VERSION ""

NS_ :

BS_:

BU_: IGW ADU

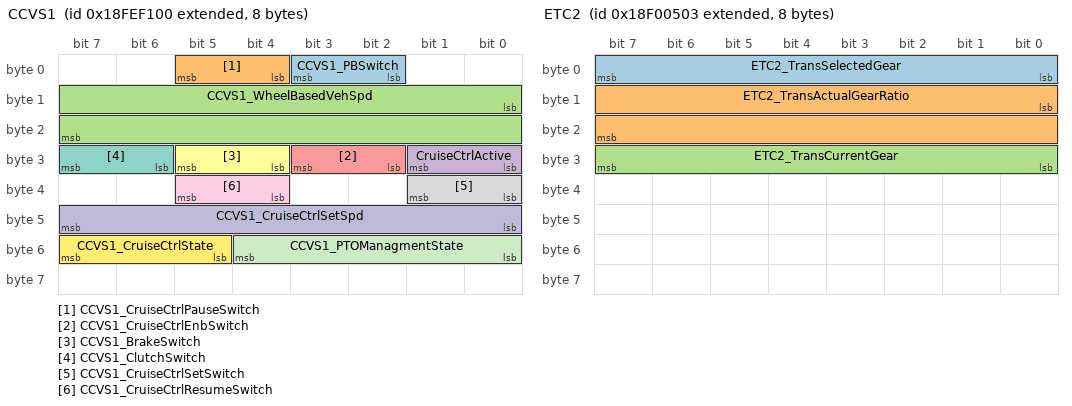
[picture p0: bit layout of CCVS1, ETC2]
BO_ 2566844672 CCVS1: 8 IGW
 SG_ CCVS1_PBSwitch : 2|2@1+ (1,0) [0|3] ""  ADU
 SG_ CCVS1_CruiseCtrlPauseSwitch : 4|2@1+ (1,0) [0|3] ""  ADU
 SG_ CCVS1_WheelBasedVehSpd : 8|16@1+ (0.00390625,0) [0|250.996] "km/h"  ADU
 SG_ CruiseCtrlActive : 24|2@1+ (1,0) [0|3] ""  ADU
 SG_ CCVS1_CruiseCtrlEnbSwitch : 26|2@1+ (1,0) [0|3] ""  ADU
 SG_ CCVS1_BrakeSwitch : 28|2@1+ (1,0) [0|3] ""  ADU
 SG_ CCVS1_ClutchSwitch : 30|2@1+ (1,0) [0|3] ""  ADU
 SG_ CCVS1_CruiseCtrlSetSwitch : 32|2@1+ (1,0) [0|3] ""  ADU
 SG_ CCVS1_CruiseCtrlResumeSwitch : 36|2@1+ (1,0) [0|3] ""  ADU
 SG_ CCVS1_CruiseCtrlSetSpd : 40|8@1+ (1,0) [0|250] "km/h"  ADU
 SG_ CCVS1_PTOManagmentState : 48|5@1+ (1,0) [0|31] ""  ADU
 SG_ CCVS1_CruiseCtrlState : 53|3@1+ (1,0) [0|7] ""  ADU

BO_ 2565866755 ETC2: 8 IGW
 SG_ ETC2_TransSelectedGear : 0|8@1+ (1,-125) [-125|125] ""  ADU
 SG_ ETC2_TransActualGearRatio : 8|16@1+ (0.001,0) [0|64.255] ""  ADU
 SG_ ETC2_TransCurrentGear : 24|8@1+ (1,-125) [-125|125] ""  ADU

BO_ 2566834768 DM1_EPB: 42 IGW
 SG_ DM1_EPB_ProtectLamp : 0|2@1+ (1,0) [0|3] ""  ADU
 SG_ DM1_EPB_AmberWarningLamp : 2|2@1+ (1,0) [0|3] ""  ADU
 SG_ DM1_EPB_RedStopLamp : 4|2@1+ (1,0) [0|3] ""  ADU
 SG_ DM1_EPB_MalfunctionIndicatorLamp : 6|2@1+ (1,0) [0|3] ""  ADU
 SG_ DM1_EPB_SAELamp_Reserved : 8|8@1+ (1,0) [0|255] ""  ADU
 SG_ DM1_EPB_SPN8_LeastSignificantBit : 16|8@1+ (1,0) [0|255] ""  ADU
 SG_ DM1_EPB_SPN_secondByteOfSPN : 24|8@1+ (1,0) [0|255] ""  ADU
 SG_ DM1_EPB_FMI : 32|5@1+ (1,0) [0|31] ""  ADU
 SG_ DM1_EPB_SPN3MmostSignificantBit : 37|3@1+ (1,0) [0|7] ""  ADU
 SG_ DM1_EPB_OccurrenceCount : 40|7@1+ (1,0) [0|126] ""  ADU
 SG_ DM1_EPB_SPNConversionMethod : 47|1@1+ (1,0) [0|1] ""  ADU

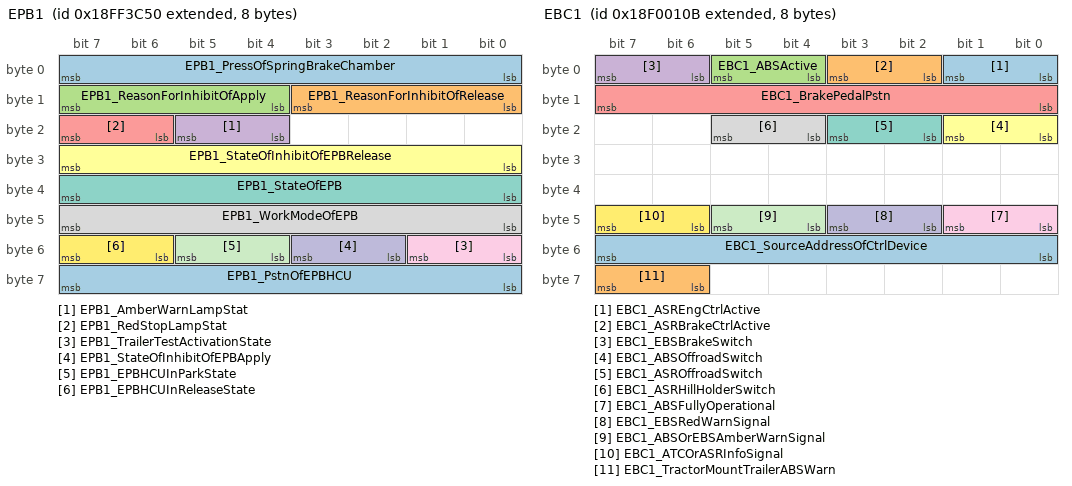
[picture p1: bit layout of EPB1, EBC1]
BO_ 2566863952 EPB1: 8 IGW
 SG_ EPB1_PressOfSpringBrakeChamber : 0|8@1+ (8,0) [0|2000] "kPa"  ADU
 SG_ EPB1_ReasonForInhibitOfRelease : 8|4@1+ (1,0) [0|15] ""  ADU
 SG_ EPB1_ReasonForInhibitOfApply : 12|4@1+ (1,0) [0|15] ""  ADU
 SG_ EPB1_AmberWarnLampStat : 20|2@1+ (1,0) [0|3] ""  ADU
 SG_ EPB1_RedStopLampStat : 22|2@1+ (1,0) [0|3] ""  ADU
 SG_ EPB1_StateOfInhibitOfEPBRelease : 24|8@1+ (1,0) [0|255] ""  ADU
 SG_ EPB1_StateOfEPB : 32|8@1+ (1,0) [0|255] ""  ADU
 SG_ EPB1_WorkModeOfEPB : 40|8@1+ (1,0) [0|255] ""  ADU
 SG_ EPB1_TrailerTestActivationState : 48|2@1+ (1,0) [0|3] ""  ADU
 SG_ EPB1_StateOfInhibitOfEPBApply : 50|2@1+ (1,0) [0|3] ""  ADU
 SG_ EPB1_EPBHCUInParkState : 52|2@1+ (1,0) [0|3] ""  ADU
 SG_ EPB1_EPBHCUInReleaseState : 54|2@1+ (1,0) [0|3] ""  ADU
 SG_ EPB1_PstnOfEPBHCU : 56|8@1+ (1,-125) [-125|125] "%"  ADU

BO_ 2566834699 DM1_ABS: 42 IGW
 SG_ DM1_ABS_ProtectLamp : 0|2@1+ (1,0) [0|3] ""  ADU
 SG_ DM1_ABS_AmberWarningLamp : 2|2@1+ (1,0) [0|3] ""  ADU
 SG_ DM1_ABS_RedStopLamp : 4|2@1+ (1,0) [0|3] ""  ADU
 SG_ DM1_ABS_MalfunctionIndicatorLamp : 6|2@1+ (1,0) [0|3] ""  ADU
 SG_ DM1_ABS_SPN8_LeastSignificantBit : 16|8@1+ (1,0) [0|255] ""  ADU
 SG_ DM1_ABS_SPN_secondByteOfSPN : 24|8@1+ (1,0) [0|255] ""  ADU
 SG_ DM1_ABS_FMI : 32|5@1+ (1,0) [0|31] ""  ADU
 SG_ DM1_ABS_SPN3MmostSignificantBit : 37|3@1+ (1,0) [0|7] ""  ADU
 SG_ DM1_ABS_OccurrenceCount : 40|7@1+ (1,0) [0|126] ""  ADU
 SG_ DM1_ABS_SPNConversionMethod : 47|1@1+ (1,0) [0|1] ""  ADU

BO_ 2565865739 EBC1: 8 IGW
 SG_ EBC1_ASREngCtrlActive : 0|2@1+ (1,0) [0|3] ""  ADU
 SG_ EBC1_ASRBrakeCtrlActive : 2|2@1+ (1,0) [0|3] ""  ADU
 SG_ EBC1_ABSActive : 4|2@1+ (1,0) [0|3] ""  ADU
 SG_ EBC1_EBSBrakeSwitch : 6|2@1+ (1,0) [0|3] ""  ADU
 SG_ EBC1_BrakePedalPstn : 8|8@1+ (0.4,0) [0|100] "%"  ADU
 SG_ EBC1_ABSOffroadSwitch : 16|2@1+ (1,0) [0|3] ""  ADU
 SG_ EBC1_ASROffroadSwitch : 18|2@1+ (1,0) [0|3] ""  ADU
 SG_ EBC1_ASRHillHolderSwitch : 20|2@1+ (1,0) [0|3] ""  ADU
 SG_ EBC1_ABSFullyOperational : 40|2@1+ (1,0) [0|3] ""  ADU
 SG_ EBC1_EBSRedWarnSignal : 42|2@1+ (1,0) [0|3] ""  ADU
 SG_ EBC1_ABSOrEBSAmberWarnSignal : 44|2@1+ (1,0) [0|3] ""  ADU
 SG_ EBC1_ATCOrASRInfoSignal : 46|2@1+ (1,0) [0|3] ""  ADU
 SG_ EBC1_SourceAddressOfCtrlDevice : 48|8@1+ (1,0) [0|253] ""  ADU
 SG_ EBC1_TractorMountTrailerABSWarn : 62|2@1+ (1,0) [0|3] ""  ADU

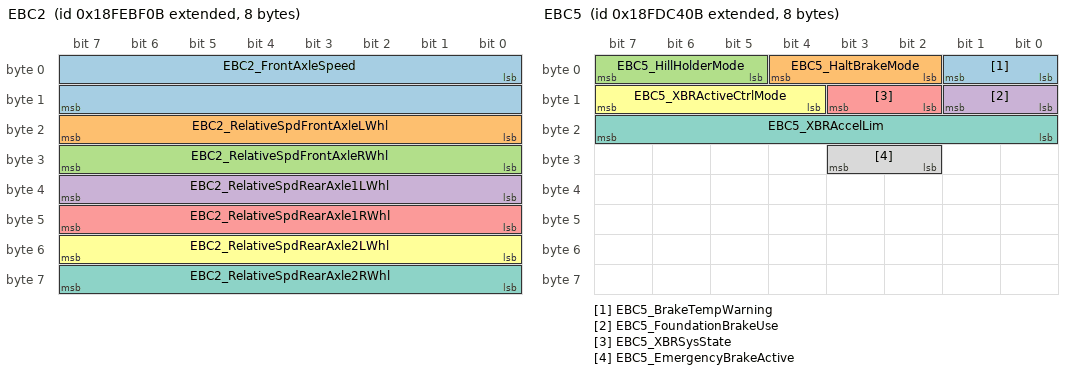
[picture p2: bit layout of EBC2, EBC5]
BO_ 2566831883 EBC2: 8 IGW
 SG_ EBC2_FrontAxleSpeed : 0|16@1+ (0.00390625,0) [0|250.996] "km/h"  ADU
 SG_ EBC2_RelativeSpdFrontAxleLWhl : 16|8@1+ (0.0625,-7.8125) [-7.8125|7.8125] "km/h"  ADU
 SG_ EBC2_RelativeSpdFrontAxleRWhl : 24|8@1+ (0.0625,-7.8125) [-7.8125|7.8125] "km/h"  ADU
 SG_ EBC2_RelativeSpdRearAxle1LWhl : 32|8@1+ (0.0625,-7.8125) [-7.8125|7.8125] "km/h"  ADU
 SG_ EBC2_RelativeSpdRearAxle1RWhl : 40|8@1+ (0.0625,-7.8125) [-7.8125|7.8125] "km/h"  ADU
 SG_ EBC2_RelativeSpdRearAxle2LWhl : 48|8@1+ (0.0625,-7.8125) [-7.8125|7.8125] "km/h"  ADU
 SG_ EBC2_RelativeSpdRearAxle2RWhl : 56|8@1+ (0.0625,-7.8125) [-7.8125|7.8125] "km/h"  ADU

BO_ 2566767627 EBC5: 8 IGW
 SG_ EBC5_BrakeTempWarning : 0|2@1+ (1,0) [0|3] ""  ADU
 SG_ EBC5_HaltBrakeMode : 2|3@1+ (1,0) [0|7] ""  ADU
 SG_ EBC5_HillHolderMode : 5|3@1+ (1,0) [0|7] ""  ADU
 SG_ EBC5_FoundationBrakeUse : 8|2@1+ (1,0) [0|3] ""  ADU
 SG_ EBC5_XBRSysState : 10|2@1+ (1,0) [0|3] ""  ADU
 SG_ EBC5_XBRActiveCtrlMode : 12|4@1+ (1,0) [0|15] ""  ADU
 SG_ EBC5_XBRAccelLim : 16|8@1+ (0.1,-12.5) [-12.5|12.5] "m/s2"  ADU
 SG_ EBC5_EmergencyBrakeActive : 26|2@1+ (1,0) [0|3] ""  ADU

BO_ 2566811659 CVW: 8 IGW
 SG_ CVW_PoweredVehWeight : 0|16@1+ (10,0) [0|642550] "kg"  ADU
 SG_ CVW_GrossCombineVehWeight : 16|16@1+ (10,0) [0|642550] "kg"  ADU

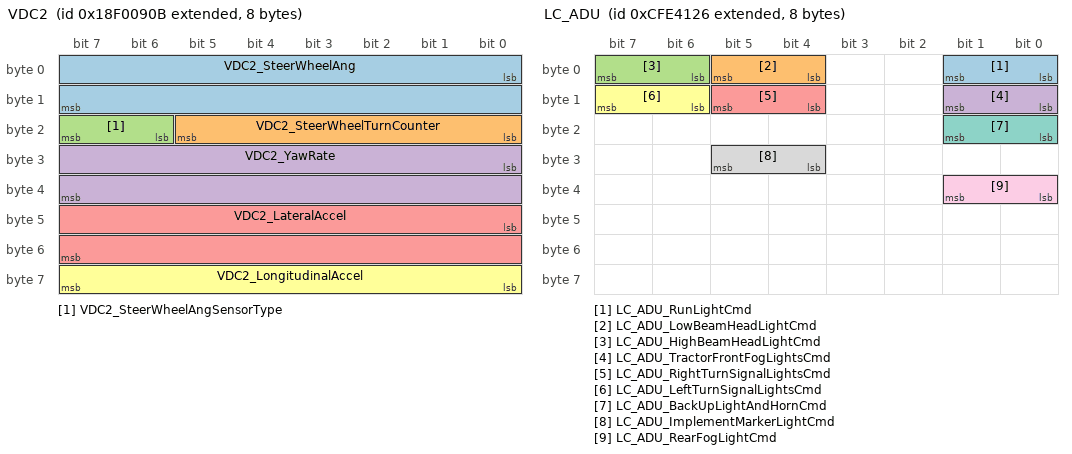
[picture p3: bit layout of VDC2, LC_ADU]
BO_ 2565867787 VDC2: 8 IGW
 SG_ VDC2_SteerWheelAng : 0|16@1+ (0.0009765625,-31.375) [-31.375|31.374] "rad"  ADU
 SG_ VDC2_SteerWheelTurnCounter : 16|6@1+ (1,-32) [-32|31] "turns"  ADU
 SG_ VDC2_SteerWheelAngSensorType : 22|2@1+ (1,0) [0|3] ""  ADU
 SG_ VDC2_YawRate : 24|16@1+ (0.0001220703125,-3.92) [-3.92|3.92] "rad/s"  ADU
 SG_ VDC2_LateralAccel : 40|16@1+ (0.00048828125,-15.687) [-15.687|15.687] "m/s2"  ADU
 SG_ VDC2_LongitudinalAccel : 56|8@1+ (0.1,-12.5) [-12.5|12.5] "m/s2"  ADU

BO_ 2365473062 LC_ADU: 8 ADU
 SG_ LC_ADU_RunLightCmd : 0|2@1+ (1,0) [0|3] ""  IGW
 SG_ LC_ADU_LowBeamHeadLightCmd : 4|2@1+ (1,0) [0|3] ""  IGW
 SG_ LC_ADU_HighBeamHeadLightCmd : 6|2@1+ (1,0) [0|3] ""  IGW
 SG_ LC_ADU_TractorFrontFogLightsCmd : 8|2@1+ (1,0) [0|3] ""  IGW
 SG_ LC_ADU_RightTurnSignalLightsCmd : 12|2@1+ (1,0) [0|3] ""  IGW
 SG_ LC_ADU_LeftTurnSignalLightsCmd : 14|2@1+ (1,0) [0|3] ""  IGW
 SG_ LC_ADU_BackUpLightAndHornCmd : 16|2@1+ (1,0) [0|3] ""  IGW
 SG_ LC_ADU_ImplementMarkerLightCmd : 28|2@1+ (1,0) [0|3] ""  IGW
 SG_ LC_ADU_RearFogLightCmd : 32|2@1+ (1,0) [0|3] ""  IGW

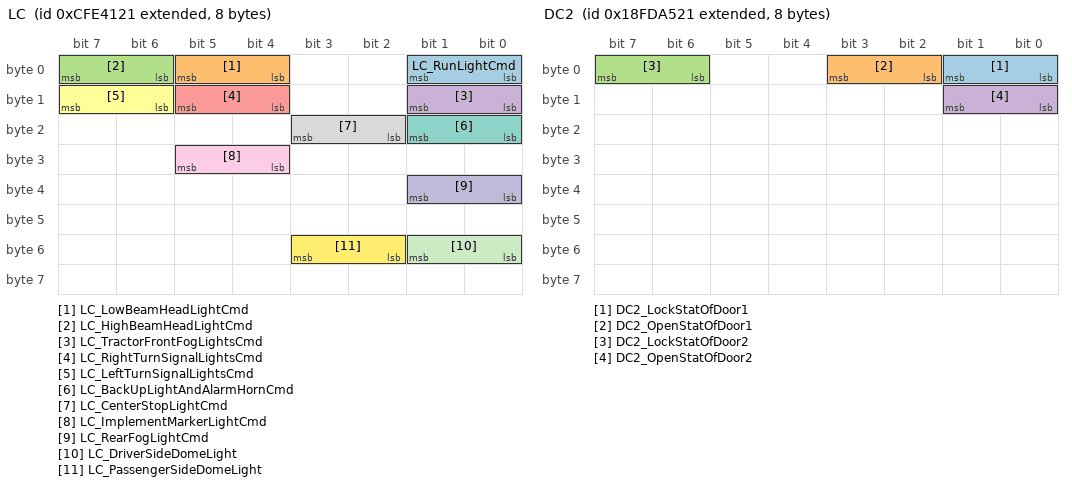
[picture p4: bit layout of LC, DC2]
BO_ 2365473057 LC: 8 IGW
 SG_ LC_RunLightCmd : 0|2@1+ (1,0) [0|3] ""  ADU
 SG_ LC_LowBeamHeadLightCmd : 4|2@1+ (1,0) [0|3] ""  ADU
 SG_ LC_HighBeamHeadLightCmd : 6|2@1+ (1,0) [0|3] ""  ADU
 SG_ LC_TractorFrontFogLightsCmd : 8|2@1+ (1,0) [0|3] ""  ADU
 SG_ LC_RightTurnSignalLightsCmd : 12|2@1+ (1,0) [0|3] ""  ADU
 SG_ LC_LeftTurnSignalLightsCmd : 14|2@1+ (1,0) [0|3] ""  ADU
 SG_ LC_BackUpLightAndAlarmHornCmd : 16|2@1+ (1,0) [0|3] ""  ADU
 SG_ LC_CenterStopLightCmd : 18|2@1+ (1,0) [0|3] ""  ADU
 SG_ LC_ImplementMarkerLightCmd : 28|2@1+ (1,0) [0|3] ""  ADU
 SG_ LC_RearFogLightCmd : 32|2@1+ (1,0) [0|3] ""  ADU
 SG_ LC_DriverSideDomeLight : 48|2@1+ (1,0) [0|3] ""  ADU
 SG_ LC_PassengerSideDomeLight : 50|2@1+ (1,0) [0|3] ""  ADU

BO_ 2566759713 DC2: 8 IGW
 SG_ DC2_LockStatOfDoor1 : 0|2@1+ (1,0) [0|3] ""  ADU
 SG_ DC2_OpenStatOfDoor1 : 2|2@1+ (1,0) [0|3] ""  ADU
 SG_ DC2_LockStatOfDoor2 : 6|2@1+ (1,0) [0|3] ""  ADU
 SG_ DC2_OpenStatOfDoor2 : 8|2@1+ (1,0) [0|3] ""  ADU

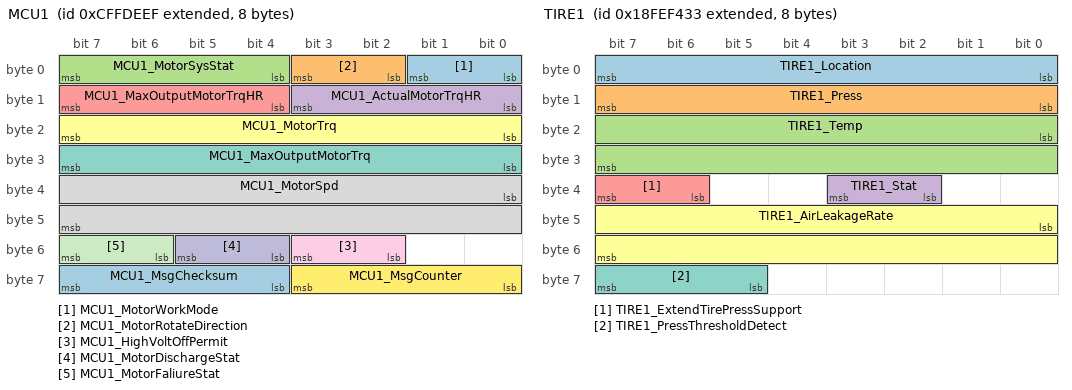
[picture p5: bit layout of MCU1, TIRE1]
BO_ 2365578991 MCU1: 8 IGW
 SG_ MCU1_MotorWorkMode : 0|2@1+ (1,0) [0|3] ""  ADU
 SG_ MCU1_MotorRotateDirection : 2|2@1+ (1,0) [0|3] ""  ADU
 SG_ MCU1_MotorSysStat : 4|4@1+ (1,0) [0|15] ""  ADU
 SG_ MCU1_ActualMotorTrqHR : 8|4@1+ (1,0) [0|15] ""  ADU
 SG_ MCU1_MaxOutputMotorTrqHR : 12|4@1+ (1,0) [0|15] ""  ADU
 SG_ MCU1_MotorTrq : 16|8@1+ (1,-125) [-125|125] "%"  ADU
 SG_ MCU1_MaxOutputMotorTrq : 24|8@1+ (1,-125) [-125|125] "%"  ADU
 SG_ MCU1_MotorSpd : 32|16@1+ (0.125,0) [0|8031.875] "rpm"  ADU
 SG_ MCU1_HighVoltOffPermit : 50|2@1+ (1,0) [0|3] ""  ADU
 SG_ MCU1_MotorDischargeStat : 52|2@1+ (1,0) [0|3] ""  ADU
 SG_ MCU1_MotorFaliureStat : 54|2@1+ (1,0) [0|3] ""  ADU
 SG_ MCU1_MsgCounter : 56|4@1+ (1,0) [0|15] ""  ADU
 SG_ MCU1_MsgChecksum : 60|4@1+ (1,0) [0|15] ""  ADU

BO_ 2566834707 DM1_EPS: 42 IGW
 SG_ DM1_EPS_ProtectLamp : 0|2@1+ (1,0) [0|3] ""  ADU
 SG_ DM1_EPS_AmberWarningLamp : 2|2@1+ (1,0) [0|3] ""  ADU
 SG_ DM1_EPS_RedStopLamp : 4|2@1+ (1,0) [0|3] ""  ADU
 SG_ DM1_EPS_MalfunctionIndicatorLamp : 6|2@1+ (1,0) [0|3] ""  ADU
 SG_ DM1_EPS_SAELamp_Reserved : 8|8@1+ (1,0) [0|255] ""  ADU
 SG_ DM1_EPS_SPN8_LeastSignificantBit : 16|8@1+ (1,0) [0|255] ""  ADU
 SG_ DM1_EPS_SPN_secondByteOfSPN : 24|8@1+ (1,0) [0|255] ""  ADU
 SG_ DM1_EPS_FMI : 32|5@1+ (1,0) [0|31] ""  ADU
 SG_ DM1_EPS_SPN3MmostSignificantBit : 37|3@1+ (1,0) [0|7] ""  ADU
 SG_ DM1_EPS_OccurrenceCount : 40|7@1+ (1,0) [0|126] ""  ADU
 SG_ DM1_EPS_SPNConversionMethod : 47|1@1+ (1,0) [0|1] ""  ADU

BO_ 2566845491 TIRE1: 8 IGW
 SG_ TIRE1_Location : 0|8@1+ (1,0) [0|255] ""  ADU
 SG_ TIRE1_Press : 8|8@1+ (4,0) [0|1000] "kpa"  ADU
 SG_ TIRE1_Temp : 16|16@1+ (0.03125,-273) [-273|1734.96875] "℃"  ADU
 SG_ TIRE1_Stat : 34|2@1+ (1,0) [0|3] ""  ADU
 SG_ TIRE1_ExtendTirePressSupport : 38|2@1+ (1,0) [0|3] ""  ADU
 SG_ TIRE1_AirLeakageRate : 40|16@1+ (0.1,0) [0|6425.5] "Pa/s"  ADU
 SG_ TIRE1_PressThresholdDetect : 61|3@1+ (1,0) [0|7] ""  ADU

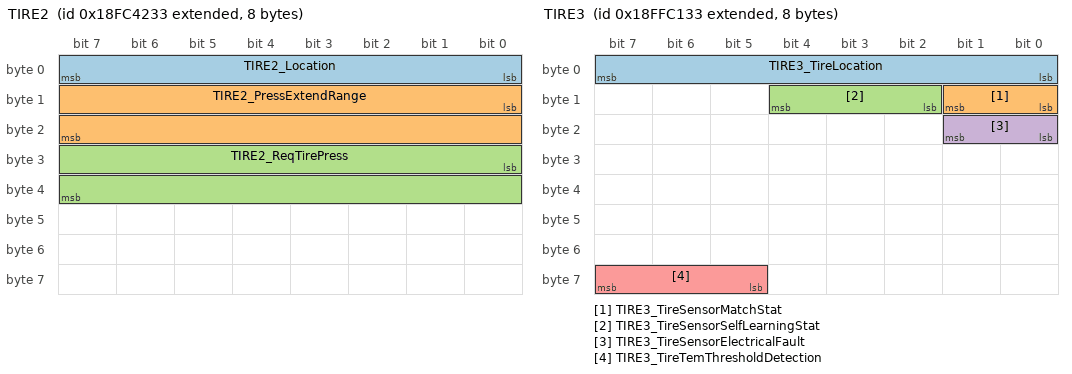
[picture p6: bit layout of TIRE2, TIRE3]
BO_ 2566668851 TIRE2: 8 IGW
 SG_ TIRE2_Location : 0|8@1+ (1,0) [0|255] ""  ADU
 SG_ TIRE2_PressExtendRange : 8|16@1+ (1,0) [0|64255] "kpa"  ADU
 SG_ TIRE2_ReqTirePress : 24|16@1+ (1,0) [0|64255] "kpa"  ADU

BO_ 2566897971 TIRE3: 8 IGW
 SG_ TIRE3_TireLocation : 0|8@1+ (1,0) [0|255] ""  ADU
 SG_ TIRE3_TireSensorMatchStat : 8|2@1+ (1,0) [0|3] ""  ADU
 SG_ TIRE3_TireSensorSelfLearningStat : 10|3@1+ (1,0) [0|7] ""  ADU
 SG_ TIRE3_TireSensorElectricalFault : 16|2@1+ (1,0) [0|3] ""  ADU
 SG_ TIRE3_TireTemThresholdDetection : 61|3@1+ (1,0) [0|7] ""  ADU

BO_ 2566834739 DM1_TPMS: 42 IGW
 SG_ DM1_TPMS_ProtectLamp : 0|2@1+ (1,0) [0|3] ""  ADU
 SG_ DM1_TPMS_AmberWarningLamp : 2|2@1+ (1,0) [0|3] ""  ADU
 SG_ DM1_TPMS_RedStopLamp : 4|2@1+ (1,0) [0|3] ""  ADU
 SG_ DM1_TPMS_MalfunctionLamp : 6|2@1+ (1,0) [0|3] ""  ADU
 SG_ DM1_TPMS_SAELamp_Reserved : 8|8@1+ (1,0) [0|255] ""  ADU
 SG_ DM1_TPMS_SPN_LeastSignificantBit : 16|8@1+ (1,0) [0|255] ""  ADU
 SG_ DM1_TPMS_SPN_secondByteOfSPN : 24|8@1+ (1,0) [0|255] ""  ADU
 SG_ DM1_TPMS_FMI : 32|5@1+ (1,0) [0|31] ""  ADU
 SG_ DM1_TPMS_SPN3MmostSignificantBit : 37|3@1+ (1,0) [0|7] ""  ADU
 SG_ DM1_TPMS_OccurrenceCount : 40|7@1+ (1,0) [0|126] ""  ADU
 SG_ DM1_TPMS_SPNConversionMethod : 47|1@1+ (1,0) [0|1] ""  ADU

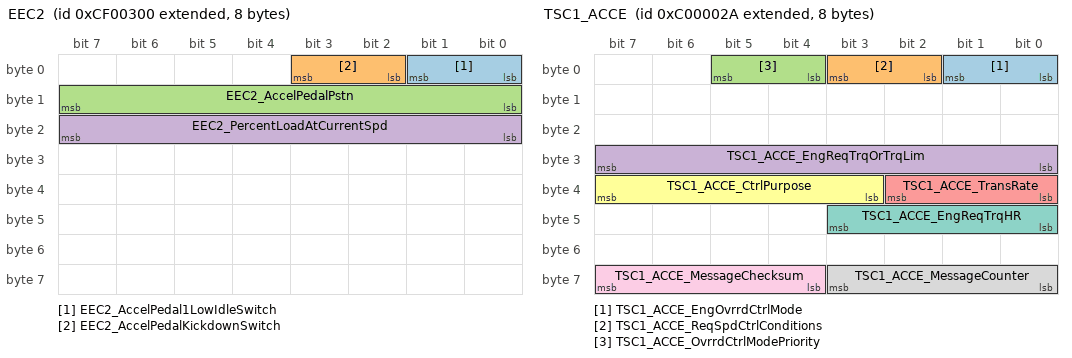
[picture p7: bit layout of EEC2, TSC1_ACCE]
BO_ 2364539648 EEC2: 8 IGW
 SG_ EEC2_AccelPedal1LowIdleSwitch : 0|2@1+ (1,0) [0|3] ""  ADU
 SG_ EEC2_AccelPedalKickdownSwitch : 2|2@1+ (1,0) [0|3] ""  ADU
 SG_ EEC2_AccelPedalPstn : 8|8@1+ (0.4,0) [0|100] "%"  ADU
 SG_ EEC2_PercentLoadAtCurrentSpd : 16|8@1+ (1,0) [0|250] "%"  ADU

BO_ 2348810282 TSC1_ACCE: 8 ADU
 SG_ TSC1_ACCE_EngOvrrdCtrlMode : 0|2@1+ (1,0) [0|3] ""  IGW
 SG_ TSC1_ACCE_ReqSpdCtrlConditions : 2|2@1+ (1,0) [0|3] ""  IGW
 SG_ TSC1_ACCE_OvrrdCtrlModePriority : 4|2@1+ (1,0) [0|3] ""  IGW
 SG_ TSC1_ACCE_EngReqTrqOrTrqLim : 24|8@1+ (1,-125) [-125|125] "%"  IGW
 SG_ TSC1_ACCE_TransRate : 32|3@1+ (1,0) [0|7] ""  IGW
 SG_ TSC1_ACCE_CtrlPurpose : 35|5@1+ (1,0) [0|31] ""  IGW
 SG_ TSC1_ACCE_EngReqTrqHR : 40|4@1+ (1,0) [0|15] ""  IGW
 SG_ TSC1_ACCE_MessageCounter : 56|4@1+ (1,0) [0|7] ""  IGW
 SG_ TSC1_ACCE_MessageChecksum : 60|4@1+ (1,0) [0|7] ""  IGW

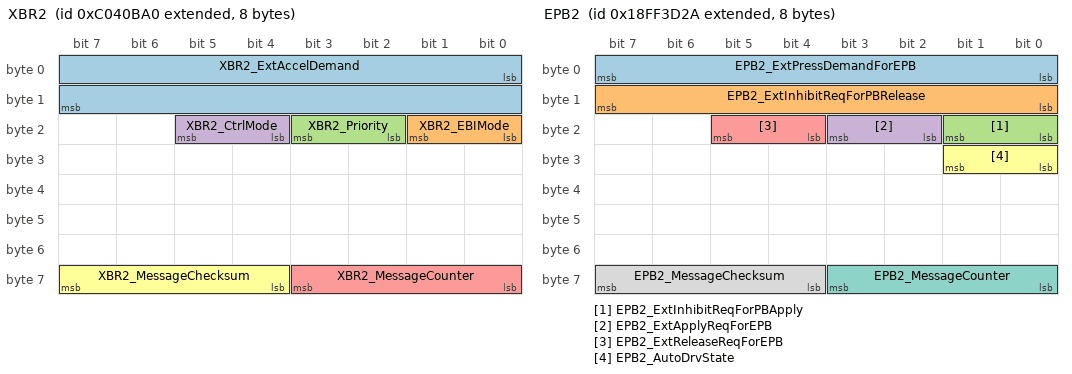
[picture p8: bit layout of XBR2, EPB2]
BO_ 2349075360 XBR2: 8 ADU
 SG_ XBR2_ExtAccelDemand : 0|16@1+ (0.00048828125,-15.687) [-15.687|15.687] "m/s2"  IGW
 SG_ XBR2_EBIMode : 16|2@1+ (1,0) [0|3] ""  IGW
 SG_ XBR2_Priority : 18|2@1+ (1,0) [0|3] ""  IGW
 SG_ XBR2_CtrlMode : 20|2@1+ (1,0) [0|3] ""  IGW
 SG_ XBR2_MessageCounter : 56|4@1+ (1,0) [0|15] ""  IGW
 SG_ XBR2_MessageChecksum : 60|4@1+ (1,0) [0|15] ""  IGW

BO_ 2348875814 TC1_ADU: 8 ADU
 SG_ TC1_ADU_TransReqGear : 16|8@1+ (1,-125) [-125|125] "%"  IGW

BO_ 2566864170 EPB2: 8 ADU
 SG_ EPB2_ExtPressDemandForEPB : 0|8@1+ (0.4,0) [0|100] "%"  IGW
 SG_ EPB2_ExtInhibitReqForPBRelease : 8|8@1+ (1,0) [0|255] ""  IGW
 SG_ EPB2_ExtInhibitReqForPBApply : 16|2@1+ (1,0) [0|3] ""  IGW
 SG_ EPB2_ExtApplyReqForEPB : 18|2@1+ (1,0) [0|3] ""  IGW
 SG_ EPB2_ExtReleaseReqForEPB : 20|2@1+ (1,0) [0|3] ""  IGW
 SG_ EPB2_AutoDrvState : 24|2@1+ (1,0) [0|3] ""  IGW
 SG_ EPB2_MessageCounter : 56|4@1+ (1,0) [0|15] ""  IGW
 SG_ EPB2_MessageChecksum : 60|4@1+ (1,0) [0|15] ""  IGW

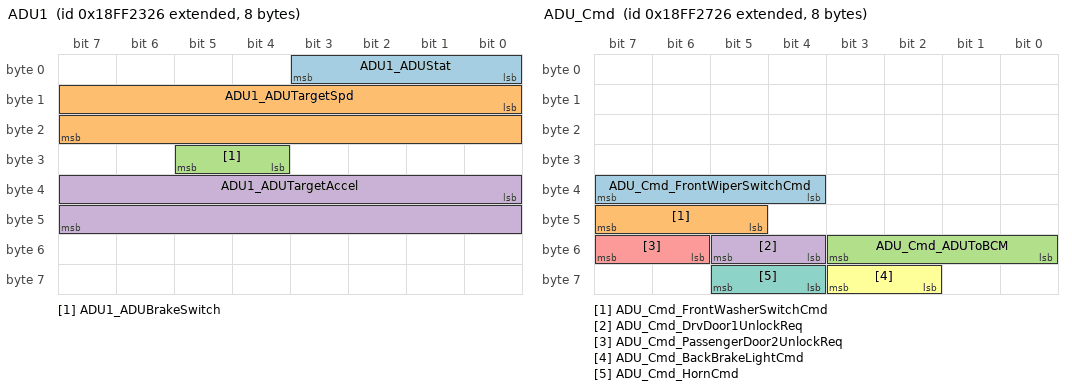
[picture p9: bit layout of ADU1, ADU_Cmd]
BO_ 2566857510 ADU1: 8 ADU
 SG_ ADU1_ADUStat : 0|4@1+ (1,0) [0|15] ""  IGW
 SG_ ADU1_ADUTargetSpd : 8|16@1+ (0.00390625,0) [0|250.996] "km/h"  IGW
 SG_ ADU1_ADUBrakeSwitch : 28|2@1+ (1,0) [0|3] ""  IGW
 SG_ ADU1_ADUTargetAccel : 32|16@1+ (0.00048828,-15.687) [-15.687|15.687] "m/s2"  IGW

BO_ 2566858534 ADU_Cmd: 8 ADU
 SG_ ADU_Cmd_FrontWiperSwitchCmd : 36|4@1+ (1,0) [0|15] ""  IGW
 SG_ ADU_Cmd_FrontWasherSwitchCmd : 45|3@1+ (1,0) [0|7] ""  IGW
 SG_ ADU_Cmd_ADUToBCM : 48|4@1+ (1,0) [0|15] ""  IGW
 SG_ ADU_Cmd_DrvDoor1UnlockReq : 52|2@1+ (1,0) [0|3] ""  IGW
 SG_ ADU_Cmd_PassengerDoor2UnlockReq : 54|2@1+ (1,0) [0|3] ""  IGW
 SG_ ADU_Cmd_BackBrakeLightCmd : 58|2@1+ (1,0) [0|3] ""  IGW
 SG_ ADU_Cmd_HornCmd : 60|2@1+ (1,0) [0|3] ""  IGW

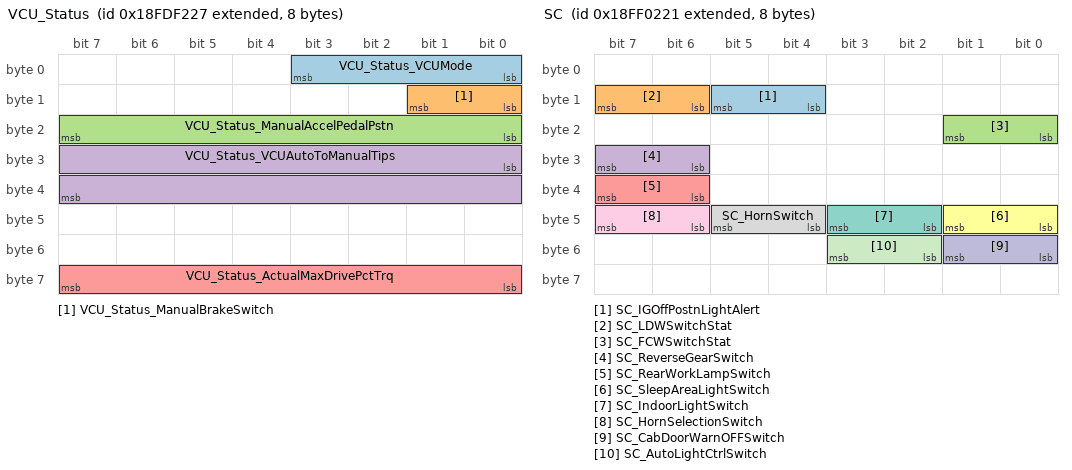
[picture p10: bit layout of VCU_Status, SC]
BO_ 2566779431 VCU_Status: 8 IGW
 SG_ VCU_Status_VCUMode : 0|4@1+ (1,0) [0|15] ""  ADU
 SG_ VCU_Status_ManualBrakeSwitch : 8|2@1+ (1,0) [0|3] ""  ADU
 SG_ VCU_Status_ManualAccelPedalPstn : 16|8@1+ (0.4,0) [0|100] "%"  ADU
 SG_ VCU_Status_VCUAutoToManualTips : 24|16@1+ (1,0) [0|65535] ""  ADU
 SG_ VCU_Status_ActualMaxDrivePctTrq : 56|8@1+ (1,-125) [-125|125] "%"  ADU

BO_ 2566769953 OWW: 8 IGW
 SG_ OWW_FrontOperatorWiperSwitch : 4|4@1+ (1,0) [0|15] ""  ADU
 SG_ OWW_FrontOperatorWasherSwitch : 45|3@1+ (1,0) [0|7] ""  ADU

BO_ 2566849057 SC: 8 IGW
 SG_ SC_IGOffPostnLightAlert : 12|2@1+ (1,0) [0|3] ""  ADU
 SG_ SC_LDWSwitchStat : 14|2@1+ (1,0) [0|3] ""  ADU
 SG_ SC_FCWSwitchStat : 16|2@1+ (1,0) [0|3] ""  ADU
 SG_ SC_ReverseGearSwitch : 30|2@1+ (1,0) [0|3] ""  ADU
 SG_ SC_RearWorkLampSwitch : 38|2@1+ (1,0) [0|3] ""  ADU
 SG_ SC_SleepAreaLightSwitch : 40|2@1+ (1,0) [0|3] ""  ADU
 SG_ SC_IndoorLightSwitch : 42|2@1+ (1,0) [0|3] ""  ADU
 SG_ SC_HornSwitch : 44|2@1+ (1,0) [0|3] ""  ADU
 SG_ SC_HornSelectionSwitch : 46|2@1+ (1,0) [0|3] ""  ADU
 SG_ SC_CabDoorWarnOFFSwitch : 48|2@1+ (1,0) [0|3] ""  ADU
 SG_ SC_AutoLightCtrlSwitch : 50|2@1+ (1,0) [0|3] ""  ADU

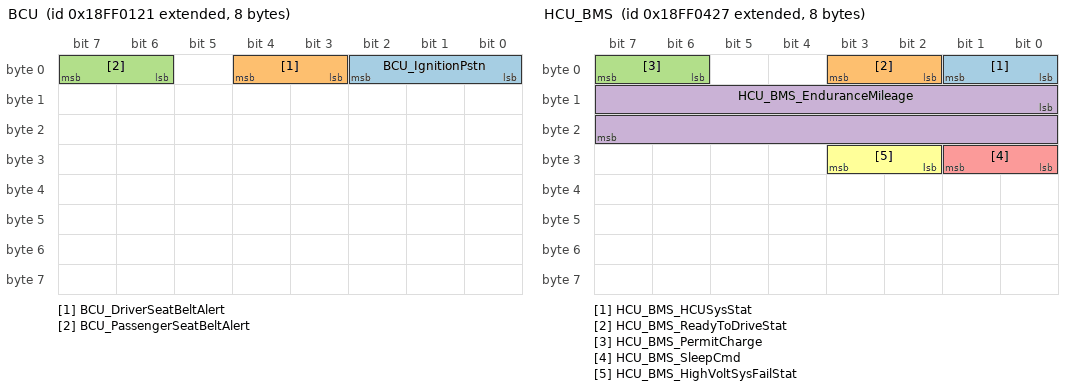
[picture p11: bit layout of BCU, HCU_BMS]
BO_ 2566848801 BCU: 8 IGW
 SG_ BCU_IgnitionPstn : 0|3@1+ (1,0) [0|7] ""  ADU
 SG_ BCU_DriverSeatBeltAlert : 3|2@1+ (1,0) [0|3] ""  ADU
 SG_ BCU_PassengerSeatBeltAlert : 6|2@1+ (1,0) [0|3] ""  ADU

BO_ 2566849575 HCU_BMS: 8 IGW
 SG_ HCU_BMS_HCUSysStat : 0|2@1+ (1,0) [0|3] ""  ADU
 SG_ HCU_BMS_ReadyToDriveStat : 2|2@1+ (1,0) [0|3] ""  ADU
 SG_ HCU_BMS_PermitCharge : 6|2@1+ (1,0) [0|3] ""  ADU
 SG_ HCU_BMS_EnduranceMileage : 8|16@1+ (0.125,0) [0|8031.875] "km"  ADU
 SG_ HCU_BMS_SleepCmd : 24|2@1+ (1,0) [0|3] ""  ADU
 SG_ HCU_BMS_HighVoltSysFailStat : 26|2@1+ (1,0) [0|3] ""  ADU

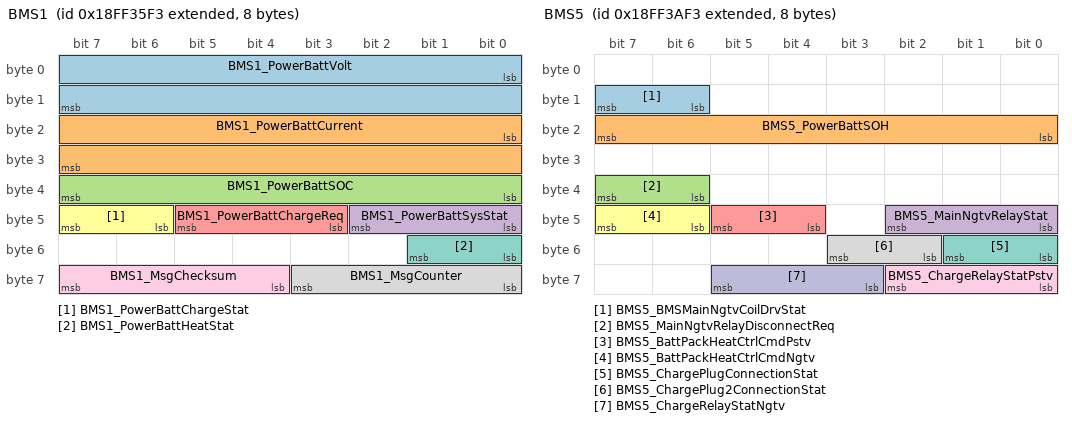
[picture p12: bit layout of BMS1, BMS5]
BO_ 2566862323 BMS1: 8 IGW
 SG_ BMS1_PowerBattVolt : 0|16@1+ (0.05,0) [0|3212.75] "V"  ADU
 SG_ BMS1_PowerBattCurrent : 16|16@1+ (0.05,-1600) [-1600|1612.75] "A"  ADU
 SG_ BMS1_PowerBattSOC : 32|8@1+ (0.4,0) [0|100] "%"  ADU
 SG_ BMS1_PowerBattSysStat : 40|3@1+ (1,0) [0|7] ""  ADU
 SG_ BMS1_PowerBattChargeReq : 43|3@1+ (1,0) [0|7] ""  ADU
 SG_ BMS1_PowerBattChargeStat : 46|2@1+ (1,0) [0|3] ""  ADU
 SG_ BMS1_PowerBattHeatStat : 48|2@1+ (1,0) [0|3] ""  ADU
 SG_ BMS1_MsgCounter : 56|4@1+ (1,0) [0|15] ""  ADU
 SG_ BMS1_MsgChecksum : 60|4@1+ (1,0) [0|15] ""  ADU

BO_ 2566863603 BMS5: 8 IGW
 SG_ BMS5_BMSMainNgtvCoilDrvStat : 14|2@1+ (1,0) [0|3] ""  ADU
 SG_ BMS5_PowerBattSOH : 16|8@1+ (0.4,0) [0|100] "%"  ADU
 SG_ BMS5_MainNgtvRelayDisconnectReq : 38|2@1+ (1,0) [0|3] ""  ADU
 SG_ BMS5_MainNgtvRelayStat : 40|3@1+ (1,0) [0|7] ""  ADU
 SG_ BMS5_BattPackHeatCtrlCmdPstv : 44|2@1+ (1,0) [0|3] ""  ADU
 SG_ BMS5_BattPackHeatCtrlCmdNgtv : 46|2@1+ (1,0) [0|3] ""  ADU
 SG_ BMS5_ChargePlugConnectionStat : 48|2@1+ (1,0) [0|3] ""  ADU
 SG_ BMS5_ChargePlug2ConnectionStat : 50|2@1+ (1,0) [0|3] ""  ADU
 SG_ BMS5_ChargeRelayStatPstv : 56|3@1+ (1,0) [0|7] ""  ADU
 SG_ BMS5_ChargeRelayStatNgtv : 59|3@1+ (1,0) [0|7] ""  ADU

BO_ 2566840343 VD: 8 IGW
 SG_ VD_TripDistance : 0|32@1+ (0.125,0) [0|526385151.875] "km"  ADU
 SG_ VD_TotalVehDistance : 32|32@1+ (0.125,0) [0|526385151.875] "km"  ADU

BO_ 2566834721 DM1_BCM: 42 IGW
 SG_ DM1_BCM_AmberWarningLamp : 2|2@1+ (1,0) [0|3] ""  ADU
 SG_ DM1_BCM_RedStopLamp : 4|2@1+ (1,0) [0|3] ""  ADU
 SG_ DM1_BCM_SAELamp_Reserved : 8|8@1+ (1,0) [0|255] ""  ADU
 SG_ DM1_BCM_SPN8_LeastSignificantBit : 16|8@1+ (1,0) [0|255] ""  ADU
 SG_ DM1_BCM_SPN_secondByteOfSPN : 24|5@1+ (1,0) [0|31] ""  ADU
 SG_ DM1_BCM_FMI : 32|5@1+ (1,0) [0|31] ""  ADU
 SG_ DM1_BCM_SPN3MmostSignificantBit : 37|3@1+ (1,0) [0|7] ""  ADU
 SG_ DM1_BCM_OccurrenceCount : 40|7@1+ (1,0) [0|126] ""  ADU
 SG_ DM1_BCM_SPNConversionMethod : 47|1@1+ (1,0) [0|1] ""  ADU

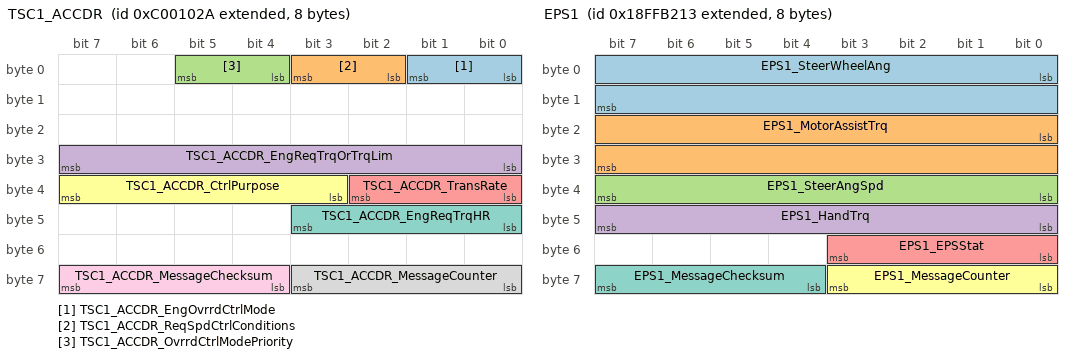
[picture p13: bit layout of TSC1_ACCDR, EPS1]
BO_ 2348814378 TSC1_ACCDR: 8 ADU
 SG_ TSC1_ACCDR_EngOvrrdCtrlMode : 0|2@1+ (1,0) [0|3] ""  IGW
 SG_ TSC1_ACCDR_ReqSpdCtrlConditions : 2|2@1+ (1,0) [0|3] ""  IGW
 SG_ TSC1_ACCDR_OvrrdCtrlModePriority : 4|2@1+ (1,0) [0|3] ""  IGW
 SG_ TSC1_ACCDR_EngReqTrqOrTrqLim : 24|8@1+ (1,-125) [-125|125] "%"  IGW
 SG_ TSC1_ACCDR_TransRate : 32|3@1+ (1,0) [0|7] ""  IGW
 SG_ TSC1_ACCDR_CtrlPurpose : 35|5@1+ (1,0) [0|31] ""  IGW
 SG_ TSC1_ACCDR_EngReqTrqHR : 40|4@1+ (1,0) [0|15] ""  IGW
 SG_ TSC1_ACCDR_MessageCounter : 56|4@1+ (1,0) [0|7] ""  IGW
 SG_ TSC1_ACCDR_MessageChecksum : 60|4@1+ (1,0) [0|7] ""  IGW

BO_ 2566841127 EC_EM1: 40 IGW
 SG_ EC_EM1_EngSpdAtPoint1 : 0|16@1+ (0.125,0) [0|8031.875] "rpm"  ADU
 SG_ EC_EM1_EngReferenceTrq : 152|16@1+ (1,0) [0|64255] "Nm"  ADU
 SG_ EC_EM1_SupportVariableRateTSC1 : 272|8@1+ (1,0) [0|255] ""  ADU

BO_ 2566894099 EPS1: 8 IGW
 SG_ EPS1_SteerWheelAng : 0|16@1+ (0.1,-1575) [-1575|1575] "°"  ADU
 SG_ EPS1_MotorAssistTrq : 16|16@1+ (0.000152,-5) [-5|4.76676] "Nm"  ADU
 SG_ EPS1_SteerAngSpd : 32|8@1+ (10,0) [0|540] "°/s"  ADU
 SG_ EPS1_HandTrq : 40|8@1+ (0.1,-12.8) [-12.8|12.7] "Nm"  ADU
 SG_ EPS1_EPSStat : 48|4@1+ (1,0) [0|15] ""  ADU
 SG_ EPS1_MessageCounter : 56|4@1+ (1,0) [0|15] ""  ADU
 SG_ EPS1_MessageChecksum : 60|4@1+ (1,0) [0|15] ""  ADU

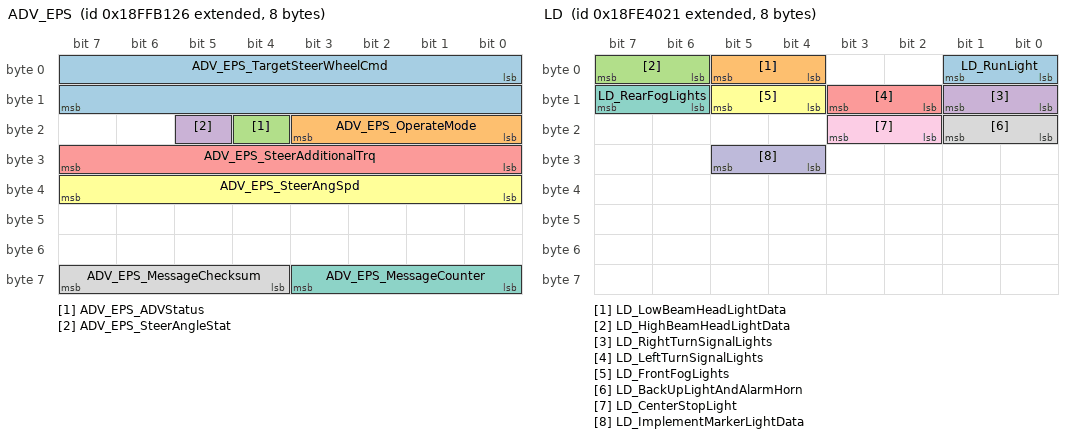
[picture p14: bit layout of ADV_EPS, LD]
BO_ 2566893862 ADV_EPS: 8 ADU
 SG_ ADV_EPS_TargetSteerWheelCmd : 0|16@1+ (0.1,-1575) [-1575|1575] "°"  IGW
 SG_ ADV_EPS_OperateMode : 16|4@1+ (1,0) [0|15] ""  IGW
 SG_ ADV_EPS_ADVStatus : 20|1@1+ (1,0) [0|1] ""  IGW
 SG_ ADV_EPS_SteerAngleStat : 21|1@1+ (1,0) [0|1] ""  IGW
 SG_ ADV_EPS_SteerAdditionalTrq : 24|8@1+ (0.1,-12.8) [-12.8|12.7] "Nm"  IGW
 SG_ ADV_EPS_SteerAngSpd : 32|8@1+ (10,0) [0|540] "°/s"  IGW
 SG_ ADV_EPS_MessageCounter : 56|4@1+ (1,0) [0|15] ""  IGW
 SG_ ADV_EPS_MessageChecksum : 60|4@1+ (1,0) [0|15] ""  IGW

BO_ 2566799393 LD: 8 IGW
 SG_ LD_RunLight : 0|2@1+ (1,0) [0|3] ""  ADU
 SG_ LD_LowBeamHeadLightData : 4|2@1+ (1,0) [0|3] ""  ADU
 SG_ LD_HighBeamHeadLightData : 6|2@1+ (1,0) [0|3] ""  ADU
 SG_ LD_RightTurnSignalLights : 8|2@1+ (1,0) [0|3] ""  ADU
 SG_ LD_LeftTurnSignalLights : 10|2@1+ (1,0) [0|3] ""  ADU
 SG_ LD_FrontFogLights : 12|2@1+ (1,0) [0|3] ""  ADU
 SG_ LD_RearFogLights : 14|2@1+ (1,0) [0|3] ""  ADU
 SG_ LD_BackUpLightAndAlarmHorn : 16|2@1+ (1,0) [0|3] ""  ADU
 SG_ LD_CenterStopLight : 18|2@1+ (1,0) [0|3] ""  ADU
 SG_ LD_ImplementMarkerLightData : 28|2@1+ (1,0) [0|3] ""  ADU

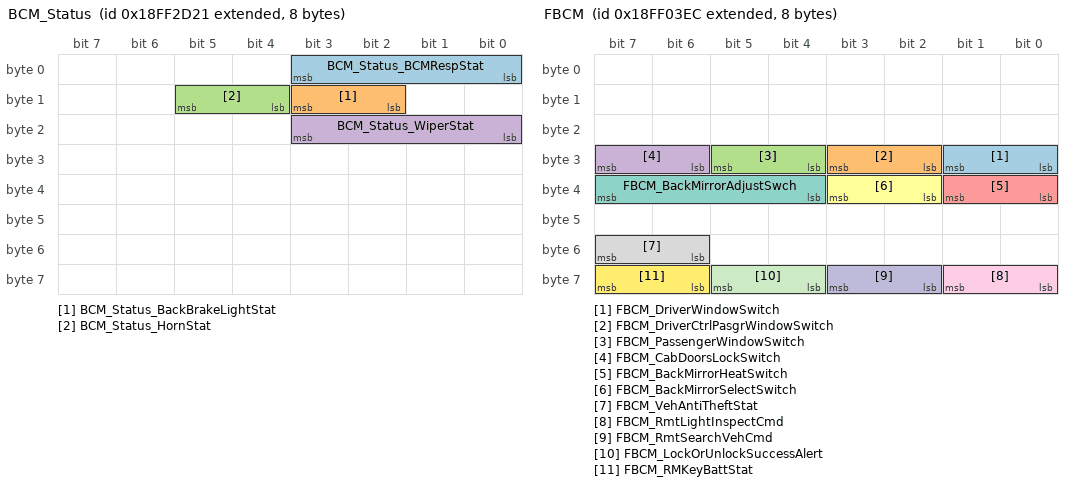
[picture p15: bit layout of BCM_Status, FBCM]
BO_ 2566860065 BCM_Status: 8 IGW
 SG_ BCM_Status_BCMRespStat : 0|4@1+ (1,0) [0|15] ""  ADU
 SG_ BCM_Status_BackBrakeLightStat : 10|2@1+ (1,0) [0|3] ""  ADU
 SG_ BCM_Status_HornStat : 12|2@1+ (1,0) [0|3] ""  ADU
 SG_ BCM_Status_WiperStat : 16|4@1+ (1,0) [0|15] ""  ADU

BO_ 2566834931 DM1_BMS: 42 IGW
 SG_ DM1_BMS_AmberWarningLamp : 2|2@1+ (1,0) [0|3] ""  ADU
 SG_ DM1_BMS_RedStopLamp : 4|2@1+ (1,0) [0|3] ""  ADU
 SG_ DM1_BMS_SAELamp_Reserved : 8|8@1+ (1,0) [0|255] ""  ADU
 SG_ DM1_BMS_SPN8_LeastSignificantBit : 16|8@1+ (1,0) [0|255] ""  ADU
 SG_ DM1_BMS_SPN_secondByteOfSPN : 24|5@1+ (1,0) [0|31] ""  ADU
 SG_ DM1_BMS_FMI : 32|5@1+ (1,0) [0|31] ""  ADU
 SG_ DM1_BMS_SPN3MmostSignificantBit : 37|3@1+ (1,0) [0|7] ""  ADU
 SG_ DM1_BMS_OccurrenceCount : 40|7@1+ (1,0) [0|126] ""  ADU
 SG_ DM1_BMS_SPNConversionMethod : 47|1@1+ (1,0) [0|1] ""  ADU

BO_ 2566834784 DM1_PTU: 42 IGW
 SG_ DM1_PTU_AmberWarningLamp : 2|2@1+ (1,0) [0|3] ""  ADU
 SG_ DM1_PTU_RedStopLamp : 4|2@1+ (1,0) [0|3] ""  ADU
 SG_ DM1_PTU_SAELamp_Reserved : 8|8@1+ (1,0) [0|255] ""  ADU
 SG_ DM1_PTU_SPN8_LeastSignificantBit : 16|8@1+ (1,0) [0|255] ""  ADU
 SG_ DM1_PTU_SPN_secondByteOfSPN : 24|5@1+ (1,0) [0|31] ""  ADU
 SG_ DM1_PTU_FMI : 32|5@1+ (1,0) [0|31] ""  ADU
 SG_ DM1_PTU_SPN3MmostSignificantBit : 37|3@1+ (1,0) [0|7] ""  ADU
 SG_ DM1_PTU_OccurrenceCount : 40|7@1+ (1,0) [0|126] ""  ADU
 SG_ DM1_PTU_SPNConversionMethod : 47|1@1+ (1,0) [0|1] ""  ADU

BO_ 2566834741 DM1_DCDC2: 42 IGW
 SG_ DM1_DCDC2_AmberWarningLamp : 2|2@1+ (1,0) [0|3] ""  ADU
 SG_ DM1_DCDC2_RedStopLamp : 4|2@1+ (1,0) [0|3] ""  ADU
 SG_ DM1_DCDC2_SAELamp_Reserved : 8|8@1+ (1,0) [0|255] ""  ADU
 SG_ DM1_DCDC2_SPN_LeastSgnificantBit : 16|8@1+ (1,0) [0|255] ""  ADU
 SG_ DM1_DCDC2_SPN_secondByteOfSPN : 24|5@1+ (1,0) [0|31] ""  ADU
 SG_ DM1_DCDC2_FMI : 32|5@1+ (1,0) [0|31] ""  ADU
 SG_ DM1_DCDC2_SPNMmostSignificantBit : 37|3@1+ (1,0) [0|7] ""  ADU
 SG_ DM1_DCDC2_OccurrenceCount : 40|7@1+ (1,0) [0|126] ""  ADU
 SG_ DM1_DCDC2_SPNConversionMethod : 47|1@1+ (1,0) [0|1] ""  ADU

BO_ 2566834736 DM1_APCU: 42 IGW
 SG_ DM1_APCU_AmberWarningLamp : 2|2@1+ (1,0) [0|3] ""  ADU
 SG_ DM1_APCU_RedStopLamp : 4|2@1+ (1,0) [0|3] ""  ADU
 SG_ DM1_APCU_SAELamp_Reserved : 8|8@1+ (1,0) [0|255] ""  ADU
 SG_ DM1_APCU_SPN_LeastSignificantBit : 16|8@1+ (1,0) [0|255] ""  ADU
 SG_ DM1_APCU_SPN_secondByteOfSPN : 24|5@1+ (1,0) [0|31] ""  ADU
 SG_ DM1_APCU_FMI : 32|5@1+ (1,0) [0|31] ""  ADU
 SG_ DM1_APCU_SPN3MmostSignificantBit : 37|3@1+ (1,0) [0|7] ""  ADU
 SG_ DM1_APCU_OccurrenceCount : 40|7@1+ (1,0) [0|126] ""  ADU
 SG_ DM1_APCU_SPNConversionMethod : 47|1@1+ (1,0) [0|1] ""  ADU

BO_ 2566849516 FBCM: 8 IGW
 SG_ FBCM_DriverWindowSwitch : 24|2@1+ (1,0) [0|3] ""  ADU
 SG_ FBCM_DriverCtrlPasgrWindowSwitch : 26|2@1+ (1,0) [0|3] ""  ADU
 SG_ FBCM_PassengerWindowSwitch : 28|2@1+ (1,0) [0|3] ""  ADU
 SG_ FBCM_CabDoorsLockSwitch : 30|2@1+ (1,0) [0|3] ""  ADU
 SG_ FBCM_BackMirrorHeatSwitch : 32|2@1+ (1,0) [0|3] ""  ADU
 SG_ FBCM_BackMirrorSelectSwitch : 34|2@1+ (1,0) [0|3] ""  ADU
 SG_ FBCM_BackMirrorAdjustSwch : 36|4@1+ (1,0) [0|15] ""  ADU
 SG_ FBCM_VehAntiTheftStat : 54|2@1+ (1,0) [0|3] ""  ADU
 SG_ FBCM_RmtLightInspectCmd : 56|2@1+ (1,0) [0|3] ""  ADU
 SG_ FBCM_RmtSearchVehCmd : 58|2@1+ (1,0) [0|3] ""  ADU
 SG_ FBCM_LockOrUnlockSuccessAlert : 60|2@1+ (1,0) [0|3] ""  ADU
 SG_ FBCM_RMKeyBattStat : 62|2@1+ (1,0) [0|3] ""  ADU

BO_ 2632777552 TPCM_EPB: 8 IGW
 SG_ TPCM_EPB : 0|64@1+ (1,0) [0|65535] ""  ADU

BO_ 2632712016 TPDT_EPB: 8 IGW
 SG_ TPDT_EPB : 0|64@1+ (1,0) [0|65535] ""  ADU

BO_ 2632777483 TPCM_EBS: 8 IGW
 SG_ TPCM_EBS : 0|64@1+ (1,0) [0|65535] ""  ADU

BO_ 2632711947 TPDT_EBS: 8 IGW
 SG_ TPDT_EBS : 0|64@1+ (1,0) [0|65535] ""  ADU

BO_ 2632777491 TPCM_EPS: 8 IGW
 SG_ TPCM_EPS : 0|64@1+ (1,0) [0|65535] ""  ADU

BO_ 2632711955 TPDT_EPS: 8 IGW
 SG_ TPDT_EPS : 0|64@1+ (1,0) [0|65535] ""  ADU

BO_ 2632777505 TPCM_BCM: 8 IGW
 SG_ TPCM_BCM : 0|64@1+ (1,0) [0|65535] ""  ADU

BO_ 2632711969 TPDT_BCM: 8 IGW
 SG_ TPDT_BCM : 0|64@1+ (1,0) [0|65535] ""  ADU

BO_ 2632777523 TPCM_TPMS: 8 IGW
 SG_ TPCM_TPMS : 0|64@1+ (1,0) [0|65535] ""  ADU

BO_ 2632711987 TPDT_TPMS: 8 IGW
 SG_ TPDT_TPMS : 0|64@1+ (1,0) [0|65535] ""  ADU

BO_ 2632777715 TPCM_BMS: 8 IGW
 SG_ TPCM_BMS : 0|64@1+ (1,0) [0|65535] ""  ADU

BO_ 2632712179 TPDT_BMS: 8 IGW
 SG_ TPDT_BMS : 0|64@1+ (1,0) [0|65535] ""  ADU

BO_ 2632777511 TPCM_VCU: 8 IGW
 SG_ TPCM_VCU : 0|16@1+ (1,0) [0|65535] ""  ADU

BO_ 2632711975 TPDT_VCU: 8 IGW
 SG_ TPDT_VCU : 0|16@1+ (1,0) [0|65535] ""  ADU

BO_ 2632777568 TPCM_PTU: 8 IGW
 SG_ TPCM_PTU : 0|16@1+ (1,0) [0|65535] ""  ADU

BO_ 2632712032 TPDT_PTU: 8 IGW
 SG_ TPDT_PTU : 0|16@1+ (1,0) [0|65535] ""  ADU

BO_ 2632777525 TPCM_DCDC2: 8 IGW
 SG_ TPCM_DCDC2 : 0|16@1+ (1,0) [0|65535] ""  ADU

BO_ 2632711989 TPDT_DCDC2: 8 IGW
 SG_ TPDT_DCDC2 : 0|16@1+ (1,0) [0|65535] ""  ADU

BO_ 2632777520 TPCM_APCU: 8 IGW
 SG_ TPCM_APCU : 0|16@1+ (1,0) [0|65535] ""  ADU

BO_ 2632711984 TPDT_APCU: 8 IGW
 SG_ TPDT_APCU : 0|16@1+ (1,0) [0|65535] ""  ADU

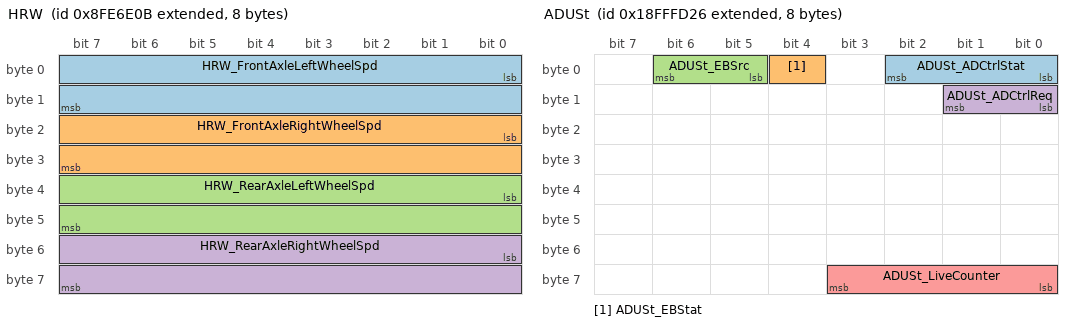
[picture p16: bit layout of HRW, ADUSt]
BO_ 2298375691 HRW: 8 IGW
 SG_ HRW_FrontAxleLeftWheelSpd : 0|16@1+ (0.00390625,0) [0|250.996] "km/h"  ADU
 SG_ HRW_FrontAxleRightWheelSpd : 16|16@1+ (0.00390625,0) [0|250.996] "km/h"  ADU
 SG_ HRW_RearAxleLeftWheelSpd : 32|16@1+ (0.00390625,0) [0|250.996] "km/h"  ADU
 SG_ HRW_RearAxleRightWheelSpd : 48|16@1+ (0.00390625,0) [0|250.996] "km/h"  ADU

BO_ 2566913318 ADUSt: 8 ADU
 SG_ ADUSt_ADCtrlStat : 0|3@1+ (1,0) [0|7] ""  IGW
 SG_ ADUSt_EBStat : 4|1@1+ (1,0) [0|1] ""  IGW
 SG_ ADUSt_EBSrc : 5|2@1+ (1,0) [0|3] ""  IGW
 SG_ ADUSt_ADCtrlReq : 8|2@1+ (1,0) [0|3] ""  IGW
 SG_ ADUSt_LiveCounter : 56|4@1+ (1,0) [0|15] ""  IGW

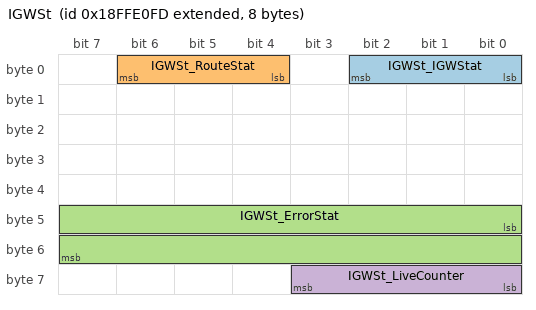
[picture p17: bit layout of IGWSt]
BO_ 2566906109 IGWSt: 8 IGW
 SG_ IGWSt_IGWStat : 0|3@1+ (1,0) [0|7] ""  ADU
 SG_ IGWSt_RouteStat : 4|3@1+ (1,0) [0|7] ""  ADU
 SG_ IGWSt_ErrorStat : 40|16@1+ (1,0) [0|65535] ""  ADU
 SG_ IGWSt_LiveCounter : 56|4@1+ (1,0) [0|15] ""  ADU

CM_ SG_ 2566844672 CCVS1_PBSwitch "Switch signal which indicates when the parking brake is set. In general the switch actuated by the operator's park brake control, whether a pedal, lever or other control mechanism  (see also SPN 619 and 5275).";
CM_ SG_ 2566844672 CCVS1_CruiseCtrlPauseSwitch "Swch signal which indicates the Postn of the Cruise Ctrl Pause Swch used on Rmot CruiseCtrl applications.";
CM_ SG_ 2566844672 CCVS1_WheelBasedVehSpd "Speed of the vehicle as calculated from wheel or tailshaft speed.";
CM_ SG_ 2566844672 CruiseCtrlActive "Cruise Ctrl is Swched on. It is not ensured that the Eng is Ctrlled by cruise Ctrl, as in the caseof a large Drv's demand the Eng is Ctrlled by the Drv while cruise Ctrl is active (maximumselection of cruise Ctrl and Drv's demand). The cruise Ctrl is set to 0 if a Swch off conditionoccurs.";
CM_ SG_ 2566844672 CCVS1_CruiseCtrlEnbSwitch "Swch signal which indicates that it is possible to manage the cruise Ctrl function";
CM_ SG_ 2566844672 CCVS1_BrakeSwitch "Swch signal which indicates that the Drv operated Brk foot pedal is being pressed. This Brk footpedal is Ctrlling the Vhcls' service Brk (total Vhcl braking application, not park Brks). It isnecessary for safe drivetrain behavior that the Swch activates before the physical braking componentsare activated (i.e. Disengage the cruise Ctrl function prior to the activation of friction Brks).";
CM_ SG_ 2566844672 CCVS1_ClutchSwitch "Swch signal which indicates that the clutch pedal is being pressed. It is necessary for a safe drivetrainbehavior that the clutch Swch is set before the clutch is opened (cruise Ctrl function).";
CM_ SG_ 2566844672 CCVS1_CruiseCtrlSetSwitch "Swch signal of the cruise Ctrl activator which indicates that the activator is in the Postn 'set.'";
CM_ SG_ 2566844672 CCVS1_CruiseCtrlResumeSwitch "Swch signal of the cruise Ctrl activator which indicates that the activator is in the Postn 'resume.'";
CM_ SG_ 2566844672 CCVS1_CruiseCtrlSetSpd "Value of set (chosen) velocity of velocity Ctrl Sys.";
CM_ SG_ 2566844672 CCVS1_PTOManagmentState "用于表示当前PTO处于的状态";
CM_ SG_ 2566844672 CCVS1_CruiseCtrlState "This parameter is used to indicate the Curr Sts, or mode, of operation by the cruise Ctrl device";
CM_ SG_ 2565866755 ETC2_TransSelectedGear "The gear that the transmission will attempt to achieve during the current shift if a shift is in progress, or the next shift if one
is pending";
CM_ SG_ 2565866755 ETC2_TransActualGearRatio "Actual ratio of input shaft speed to output shaft speed";
CM_ SG_ 2565866755 ETC2_TransCurrentGear "The gear currently engaged in the transmission or the last gear engaged while the transmission is in the process of
shifting to the new or selected gear";
CM_ SG_ 2566834768 DM1_EPB_ProtectLamp "保护灯状态";
CM_ SG_ 2566834768 DM1_EPB_AmberWarningLamp "琥珀色警示灯状态";
CM_ SG_ 2566834768 DM1_EPB_RedStopLamp "红色停止灯状态";
CM_ SG_ 2566834768 DM1_EPB_MalfunctionIndicatorLamp "故障指示灯状态";
CM_ SG_ 2566834768 DM1_EPB_SAELamp_Reserved "SAE保留分配灯状态";
CM_ SG_ 2566834768 DM1_EPB_SPN8_LeastSignificantBit "故障SPN的8个最低有效位（CM=0）
（第8位是最高有效位）";
CM_ SG_ 2566834768 DM1_EPB_SPN_secondByteOfSPN "故障SPN的第二字节（CM=0）
（第8位是最高有效位）";
CM_ SG_ 2566834768 DM1_EPB_FMI "FMI用于定义对SPN标识的子系统检测到的故障的类型（第5位是最高有效位）";
CM_ SG_ 2566834768 DM1_EPB_SPN3MmostSignificantBit "SPN， 3个最高有效位
（第8位是最高有效位）";
CM_ SG_ 2566834768 DM1_EPB_OccurrenceCount "故障发生次数
标识该故障由当前故障转变为历史故障的次数，如果故障发生次数不可知则全置位1";
CM_ SG_ 2566834768 DM1_EPB_SPNConversionMethod "故障SPN转换方式（CM）";
CM_ SG_ 2566863952 EPB1_PressOfSpringBrakeChamber "Pressure of spring brake chamber of EPBEPB弹簧制动气室的压力";
CM_ SG_ 2566863952 EPB1_ReasonForInhibitOfRelease "Reason for inhibition of EPB releaseEPB释放抑制的原因";
CM_ SG_ 2566863952 EPB1_ReasonForInhibitOfApply "Reason for inhibition of EPB apply";
CM_ SG_ 2566863952 EPB1_AmberWarnLampStat "黄色警示灯状态";
CM_ SG_ 2566863952 EPB1_StateOfInhibitOfEPBRelease "State of inhibition of EPB releaseEPB释放抑制状态";
CM_ SG_ 2566863952 EPB1_StateOfEPB "FE: Error
FF: Not available";
CM_ SG_ 2566863952 EPB1_WorkModeOfEPB "FE: Error
FF: Not available";
CM_ SG_ 2566863952 EPB1_TrailerTestActivationState "Trailer test activation state拖车试验激活状态";
CM_ SG_ 2566863952 EPB1_StateOfInhibitOfEPBApply "FE: Error
FF: Not available";
CM_ SG_ 2566863952 EPB1_EPBHCUInParkState "EPB HCU in parking state";
CM_ SG_ 2566834699 DM1_ABS_ProtectLamp "保护灯状态";
CM_ SG_ 2566834699 DM1_ABS_AmberWarningLamp "琥珀色警示灯状态";
CM_ SG_ 2566834699 DM1_ABS_RedStopLamp "红色停止灯状态";
CM_ SG_ 2566834699 DM1_ABS_MalfunctionIndicatorLamp "故障指示灯状态";
CM_ SG_ 2566834699 DM1_ABS_SPN8_LeastSignificantBit "故障SPN的8个最低有效位（CM=0）
（第8位是最高有效位）";
CM_ SG_ 2566834699 DM1_ABS_SPN_secondByteOfSPN "故障SPN的第二字节（CM=0）
（第8位是最高有效位）";
CM_ SG_ 2566834699 DM1_ABS_FMI "FMI用于定义对SPN标识的子系统检测到的故障的类型（第5位是最高有效位）";
CM_ SG_ 2566834699 DM1_ABS_SPN3MmostSignificantBit "SPN， 3个最高有效位
（第8位是最高有效位）";
CM_ SG_ 2566834699 DM1_ABS_OccurrenceCount "故障发生次数
标识该故障由当前故障转变为历史故障的次数，如果故障发生次数不可知则全置位1";
CM_ SG_ 2566834699 DM1_ABS_SPNConversionMethod "故障SPN转换方式（CM）";
CM_ SG_ 2565865739 EBC1_ASREngCtrlActive "State signal which indicates that ASR engine control has been commanded to be active. Active means that ASR actually tries tocontrol the engine. This state signal is independent of other control commands to the engine (e.g., from the transmission) whichmay have higher priority.";
CM_ SG_ 2565865739 EBC1_ASRBrakeCtrlActive "State signal which indicates that ASR brake control is active. Active means that ASR actually controls wheel brake pressure atone or more wheels of the driven axle(s).";
CM_ SG_ 2565865739 EBC1_ABSActive "State signal which indicates that the ABS is active. The signal is set active when wheel brake pressure actually starts to bemodulated by ABS and is reset to passive when all wheels are in a stable condition for a certain time. The signal can also be setactive when driven wheels are in high slip (e.g., caused by retarder). Whenever the ABS system is not fully operational (due to adefect or during off-road ABS operation) , this signal is only valid for that part of the system that is still working. When ABS isswitched off completely, the flag is set to passive regardless of the current wheel slip conditions.";
CM_ SG_ 2565865739 EBC1_EBSBrakeSwitch "Switch signal which indicates that the brake pedal is being pressed.The EBS brake switch is independent of the brake light switchand has no provisions for external connections.";
CM_ SG_ 2565865739 EBC1_BrakePedalPstn "Ratio of brake pedal position to maximum pedal position. Used for electric brake applications. 0% means no braking.Also whenthere are two brake pedals on the machine,the maximum of the two should be transmitted for Brake Pedal Position.";
CM_ SG_ 2565865739 EBC1_ABSOffroadSwitch "Switch signal which indicates the position of the ABS off-road switch.";
CM_ SG_ 2565865739 EBC1_ASROffroadSwitch "Switch signal which indicates the position of the ABS off-road switch.";
CM_ SG_ 2565865739 EBC1_ASRHillHolderSwitch "Switch signal which indicates the position of the ASR 'hill holder' switch.";
CM_ SG_ 2565865739 EBC1_ABSFullyOperational "Signal which indicates whether an ABS system is fully operational or whether its functionality is reduced by a defect or by anintended action (e.g., by activation of an ABS-off-road switch or during special diagnostic procedures). There are cases where thesignal is necessary to fulfill legal regulations for special applications (e.g., switching off integrated retarders).";
CM_ SG_ 2565865739 EBC1_EBSRedWarnSignal "This parameter commands the EBS red optical warning signal";
CM_ SG_ 2565865739 EBC1_ABSOrEBSAmberWarnSignal "This parameter commands the ABS/EBS amber/yellow optical warning signal";
CM_ SG_ 2565865739 EBC1_ATCOrASRInfoSignal "This parameter commands the ATC/ASR driver information signal, for example a dash lamp.";
CM_ SG_ 2565865739 EBC1_SourceAddressOfCtrlDevice "The source address of the SAE J1939 device currently controlling the brake system.";
CM_ SG_ 2565865739 EBC1_TractorMountTrailerABSWarn "This parameter commands the tractor-mounted trailer ABS optical warning signal.";
CM_ SG_ 2566831883 EBC2_FrontAxleSpeed "前轴平均速度
数值范围0-0xFAFF，当前轴中一轮出现故障时，将发送另一轮正常轮速，两轮故障时输出0xFEFF";
CM_ SG_ 2566831883 EBC2_RelativeSpdFrontAxleLWhl "前轴左侧轮相对于前轴的速度
数值范围0-0xFA，轮故障时输出0xFE，无效值0xFF";
CM_ SG_ 2566831883 EBC2_RelativeSpdFrontAxleRWhl "前轴右侧轮相对于前轴的速度";
CM_ SG_ 2566831883 EBC2_RelativeSpdRearAxle1LWhl "后轴左侧轮相对于前轴的速度";
CM_ SG_ 2566831883 EBC2_RelativeSpdRearAxle1RWhl "后轴右侧轮相对于前轴的速度";
CM_ SG_ 2566831883 EBC2_RelativeSpdRearAxle2LWhl "第二轴左侧轮相对于前轴的速度";
CM_ SG_ 2566831883 EBC2_RelativeSpdRearAxle2RWhl "第二轴右侧轮相对于前轴的速度";
CM_ SG_ 2566767627 EBC5_BrakeTempWarning "This parameter indicates if the temperature in the service brakes exceeds a certain value.It can be used for a warning information for the driver. The temperature warning valueis vehicle manufacturer specific.";
CM_ SG_ 2566767627 EBC5_HaltBrakeMode "Signal which indicates the current mode of the halt brake function.";
CM_ SG_ 2566767627 EBC5_HillHolderMode "Signal which indicates the current mode of the hill holder function.";
CM_ SG_ 2566767627 EBC5_FoundationBrakeUse "This parameter indicates if the brake system presently uses the foundation brakes.";
CM_ SG_ 2566767627 EBC5_XBRSysState "This parameter indicates which external brake control is allowed.";
CM_ SG_ 2566767627 EBC5_XBRActiveCtrlMode "This parameter indicates which XBR Control Mode is executed by the brake system";
CM_ SG_ 2566767627 EBC5_XBRAccelLim "The brake system may temporarily or generally limit the maximum brake performance available for external systems. A temporary limit may be nessary due to high brake temperature; a general limit may be defined by the vehicle manufacturer, e.g. a value of -2.5 m/s? due to liability reasons. The actual limit is communicated to the external systems that request braking. The limit is only effective in the XBR Priorities 01b to 11b. It is specified as an absolute acceleration in reference to the road.";
CM_ SG_ 2566767627 EBC5_EmergencyBrakeActive "Signal which indicates an emergency braking situation (ref. ECE Regulation 13 paragraph 5.2.1.31) with high  deceleration values.  This signal can be used to activate the hazard lights (ref ECE Regulation 48 paragraph 6.23) to
indicate other road users to the rear and front of the vehicle that a high retardation force has been applied to the vehicle relative to the prevailing road conditions.";
CM_ SG_ 2566811659 CVW_PoweredVehWeight "Total mass imposed by the tires of the powered Vhcl on the road surface. Does not include the trailer.";
CM_ SG_ 2566811659 CVW_GrossCombineVehWeight "The total weight of the truck and all attached trailers.";
CM_ BO_ 2565867787 "Vhcl Dynamic StabilityCtrl 2";
CM_ SG_ 2565867787 VDC2_SteerWheelAng "The main operator`s steering wheel angle (on the steering column, not the actual wheel angle).  The vehicle being steered to the left (counterclockwise) results in a positive steering wheel angle.  This is the yaw angle of the steering wheel with the z-axis along the centerline of the steering column.";
CM_ SG_ 2565867787 VDC2_SteerWheelTurnCounter "Indicates number of steering wheel turns, absolute position or relative position at ignition on. Positive values indicate left turns.";
CM_ SG_ 2565867787 VDC2_SteerWheelAngSensorType "Indicates whether the steering wheel angle sensor is capable of absolute measuring of the number of steering wheel turns or not (relative measuring to position at ignition on).";
CM_ SG_ 2565867787 VDC2_YawRate "Indicates the rate of rotation about the vertical axis. A positive yaw rate signal results when the vehicle turns counter-clockwise.";
CM_ SG_ 2565867787 VDC2_LateralAccel "Indicates a lateral acceleration of the vehicle (the component of vehicle acceleration vector along the Y-axis).";
CM_ SG_ 2565867787 VDC2_LongitudinalAccel "Indicates the longitudinal acceleration of the vehicle. A positive longitudinal acceleration signal results when the vehicle speedincreases, regardless of driving the vehicle forward or backward.";
CM_ SG_ 2365473062 LC_ADU_RunLightCmd "行车灯";
CM_ SG_ 2365473062 LC_ADU_LowBeamHeadLightCmd "近光灯控制";
CM_ SG_ 2365473062 LC_ADU_HighBeamHeadLightCmd "远光灯控制";
CM_ SG_ 2365473062 LC_ADU_TractorFrontFogLightsCmd "前雾灯控制";
CM_ SG_ 2365473062 LC_ADU_RightTurnSignalLightsCmd "右转向灯控制";
CM_ SG_ 2365473062 LC_ADU_LeftTurnSignalLightsCmd "左转向灯控制";
CM_ SG_ 2365473062 LC_ADU_BackUpLightAndHornCmd "倒车灯和蜂鸣器控制";
CM_ SG_ 2365473062 LC_ADU_ImplementMarkerLightCmd "位置灯、侧标志灯等控制";
CM_ SG_ 2365473062 LC_ADU_RearFogLightCmd "后雾灯控制";
CM_ SG_ 2365473057 LC_RunLightCmd "行车灯指令";
CM_ SG_ 2365473057 LC_LowBeamHeadLightCmd "近光灯指令";
CM_ SG_ 2365473057 LC_HighBeamHeadLightCmd "远光灯指令";
CM_ SG_ 2365473057 LC_TractorFrontFogLightsCmd "前雾灯指令";
CM_ SG_ 2365473057 LC_RightTurnSignalLightsCmd "右转向灯指令";
CM_ SG_ 2365473057 LC_LeftTurnSignalLightsCmd "左转向灯指令";
CM_ SG_ 2365473057 LC_BackUpLightAndAlarmHornCmd "倒车灯和蜂鸣器指令";
CM_ SG_ 2365473057 LC_CenterStopLightCmd "Command to activate or de-activate the tractor and implement center stop light";
CM_ SG_ 2365473057 LC_ImplementMarkerLightCmd "侧标志灯、位置灯、牌照灯等";
CM_ SG_ 2365473057 LC_RearFogLightCmd "后雾灯指令";
CM_ SG_ 2365473057 LC_DriverSideDomeLight "Swch signal which indicates the Sts of “Drv Side Reading Light“. It is the nonlocking Swch, the signal valueshould be 1 during the Swch be pressed.";
CM_ SG_ 2365473057 LC_PassengerSideDomeLight "Swch signal which indicates the Sts of “Pasgr Side Cab Dome Light“. It is the nonlocking Swch, the signalvalue should be 1 during the Swch be pressed.";
CM_ BO_ 2566759713 "Door Ctrl 2
Used for door information.";
CM_ SG_ 2566759713 DC2_LockStatOfDoor1 "Signal which indicates lock Sts of Drv door";
CM_ SG_ 2566759713 DC2_OpenStatOfDoor1 "Signal which indicates open Sts of Drv door.
Open Sts of bus door 1";
CM_ SG_ 2566759713 DC2_LockStatOfDoor2 "Signal which indicates lock Sts of Pasgr door.";
CM_ SG_ 2566759713 DC2_OpenStatOfDoor2 "Signal which indicates open Sts of Pasgr door.
Open Sts of bus door 2";
CM_ SG_ 2365578991 MCU1_MotorWorkMode "电机工作模式（实际工作模式）
电机有四种工作状态：自由随动状模式、扭矩控制模式、转速控制模式和转子零位标定。
要求电机处于自由随动状态运行时，电机的输出扭矩为零，即不能电动也不能发电，电耗降至极小值。要求具有快速进入电动及发电的响应速度。";
CM_ SG_ 2365578991 MCU1_MotorRotateDirection "电机旋转方向（实际转向）：
00 无旋转方向输出（转速在±10rpm以内无旋转方向
输出）；
01 正向：整车前进时电机旋转方向；
10 反向：整车后退时电机旋转方向；
11 不可用。";
CM_ SG_ 2365578991 MCU1_MotorSysStat "电机系统状态
0x0:表示低压上电完成，但高压电未建立的状态；
0x1:表示低压上电完成，高压上电过程中；
0x2:表示高、低压上电都完成后的状态，无扭矩输出的随动状态；
0x3:表示电机系统处于正常响应指令输出的牵引或制动状态；
0x4:表示电机系统处于限功率响应指令输出的牵引或制动状态，折扣输出；
0x5:表示电机系统发生故障；
0x6:表示高压下电过程中；
0xF:表示除以上状态以外的无效状态。";
CM_ SG_ 2365578991 MCU1_ActualMotorTrqHR "高精度电机扭矩.表示实际电机扭矩的小数部分，与信号＜电机扭矩＞共同组成实际电机扭矩。如果b3为1表示该参数不可用。当b3为0时，b0到b2用于表示电机扭矩的高精度部分，表示精度是0.125%，表示范围是0%-0.875%。";
CM_ SG_ 2365578991 MCU1_MaxOutputMotorTrqHR "表示电机可用最大电动高精度转矩的小数部分，与信号＜电机可用最大电动转矩＞共同组成电机可用电动扭矩。如果b3为1表示该参数不可用。当b3为0时，b0到b2用于表示电机扭矩的高精度部分，表示精度是0.125%，表示范围是0%-0.875%。";
CM_ SG_ 2365578991 MCU1_MotorTrq "表示电机扭矩。正值表示要求电机处于电动状态；负值表示要求电机处于发电状态。信号以扭矩百分比形式来表示，100.0%代表电机最大输出扭矩，最大输出扭矩是不随转速变化的常数（本项目园区清扫车为450Nm）。＜电机扭矩＞为实际电机扭矩的整数部分，同＜高精";
CM_ SG_ 2365578991 MCU1_MaxOutputMotorTrq "表示电机可用最大电动转矩。实际取值范围为0-125%。信号以扭矩百分比形式来表示，100.0%代表电机可用最大电动转矩，电动转矩是不随转速变化的常数。＜电机可用最大电动转矩＞为电机可用最大电动转矩的整数部分，同＜电机可用最大电动高精度转矩＞共同组成电机可用最大电动转矩。";
CM_ SG_ 2365578991 MCU1_MotorSpd "表示电机实际转速。
实际的物理值范围是0rpm-7000rpm。
实际的精度是1rpm。";
CM_ SG_ 2365578991 MCU1_HighVoltOffPermit "该信号是对电机高压下电请求信号的反馈。取值1表示允许下电，则整车控制器将切下电机母线侧的高压继电器。";
CM_ SG_ 2365578991 MCU1_MotorDischargeStat "表示电机主动放电状态。
00: 主动放电未启动，未接收到电机主动放电命令或者未启动主动放电
01：主动放电进行，执行主动放电过程中
10：主动放电完成，母线电容电压在3s内降到60V以内，
主动放电完成
11：主动放电退出，执行主动放电过程因故障退出";
CM_ SG_ 2365578991 MCU1_MotorFaliureStat "电机故障状态反馈。
三级故障为最严重故障。";
CM_ SG_ 2365578991 MCU1_MsgCounter "报文计数器用于检测由于报文发送者故障导致重复发生同一帧报文。报文接收者可以使用报文计数器检测到这种情况。报文发送者在每个报文发送周期令报文计数器增1，报文计时器从0开始计数直到15，然后再从0开始计数。";
CM_ SG_ 2365578991 MCU1_MsgChecksum "报文校验和用于验证从发送设备到接收设备的信号传输路径。校验和是下述数据的和：报文ID由高字节至低字节的和、数据区前7个字节以及报文计数器。校验和计算公式如下：校验和 = (字节1 + 字节2 + 字节3 + 字节4 + 字节5 + 字节6 + 字节7 + 报文计数器 & 0x0F + 报文ID低字节 + 报文ID中低字节 + 报文ID中高字节 + 报文ID高字节)校验和 = ((校验和 >> 4) + 校验和) & 0x0F校验和取值为0x0F时指示校验和不可用。为实现兼容性，当来自发送设备的此报文校验和不可用时，报文也应该被处理。";
CM_ SG_ 2566834707 DM1_EPS_ProtectLamp "保护灯状态";
CM_ SG_ 2566834707 DM1_EPS_AmberWarningLamp "琥珀色警示灯状态";
CM_ SG_ 2566834707 DM1_EPS_RedStopLamp "红色停止灯状态";
CM_ SG_ 2566834707 DM1_EPS_MalfunctionIndicatorLamp "故障指示灯状态";
CM_ SG_ 2566834707 DM1_EPS_SAELamp_Reserved "SAE保留分配灯状态";
CM_ SG_ 2566834707 DM1_EPS_SPN8_LeastSignificantBit "故障SPN的8个最低有效位（CM=0）
（第8位是最高有效位）";
CM_ SG_ 2566834707 DM1_EPS_SPN_secondByteOfSPN "故障SPN的第二字节（CM=0）
（第8位是最高有效位）";
CM_ SG_ 2566834707 DM1_EPS_FMI "FMI用于定义对SPN标识的子系统检测到的故障的类型（第5位是最高有效位）";
CM_ SG_ 2566834707 DM1_EPS_SPN3MmostSignificantBit "SPN， 3个最高有效位
（第8位是最高有效位）";
CM_ SG_ 2566834707 DM1_EPS_OccurrenceCount "故障发生次数
标识该故障由当前故障转变为历史故障的次数，如果故障发生次数不可知则全置位1";
CM_ SG_ 2566834707 DM1_EPS_SPNConversionMethod "故障SPN转换方式（CM）";
CM_ SG_ 2566845491 TIRE1_Location "Identifies which tire is associated with the parametric data in this PGN.
The low order 4 bits represent a position number, counting left to right when facing in the direction of normal vehicle travel (forward).
The high order 4 bits represent a ...";
CM_ SG_ 2566845491 TIRE1_Press "Pressure at which air is contained in cavity formed by tire and rim.";
CM_ SG_ 2566845491 TIRE1_Temp "Temperature at the surface of the tire sidewall.";
CM_ SG_ 2566845491 TIRE1_Stat "Indicates the status of the tire.";
CM_ SG_ 2566845491 TIRE1_ExtendTirePressSupport "Defines the choice of using the tire pressure (PGN 65268) or Extended Tire Pressure (PGN 64578). The state value '01' indicates the extended tire pressure SPN is used for the pressure data. Any other value indicates the extended tire pressure SPN is ...";
CM_ SG_ 2566845491 TIRE1_AirLeakageRate "The pressure loss rate of a tire.";
CM_ SG_ 2566845491 TIRE1_PressThresholdDetect "Signal indicating the pressure level of the tire.";
CM_ SG_ 2566668851 TIRE2_Location "Identifies which tire is associated with the parametric data in PGN 64578. Refer to SPN 929 for further details and examples. The low order 4 bits represent a position number, counting left to right when facing in the direction of normal vehicle .Examples: Tire pressure for location 0x00 would be left front tire.Tire pressure for location 0x23 would be right outside rear rear on a 3-axle tractor with dual axle per side (3rd axle, 4thtire).";
CM_ SG_ 2566668851 TIRE2_PressExtendRange "Pressure at which air is contained in cavity formed by tire and rim. See SPN 241 for alternate tire pressure with a lower range and coarser resolution.";
CM_ SG_ 2566668851 TIRE2_ReqTirePress "The required tire pressure at which air is contained in cavity formed by tire and rim.

This pressure of the tire is compensated to meet the specific physical environmental conditions (temperature) of the vehicle.";
CM_ SG_ 2566897971 TIRE3_TireLocation "Identifies which tire is associated with the parametric data in this PGN.The low order 4 bits represent a Postn number, counting left to right when facing in the direction of normal Vhcltravel (forward).The high order 4 bits represent a Postn number, counting front to back on the Vhcl.The value 0xFF indicates not available.It is recommended that output devices add 1 to the Postn number (range 1 to 15, not 0 to 14) for use by Drvs andservice technicians.Examples: Tire Press for location 0x00 would be left front tire.Tire Press for location 0x23 would be right outside rear rear on a 3-axle tractor with dual axle per side (3rd axle,4th tire).";
CM_ SG_ 2566897971 TIRE3_TireSensorMatchStat "Identifies whether the tire sensor is matched or not.";
CM_ SG_ 2566897971 TIRE3_TireSensorSelfLearningStat "Identifies the self learning Sts of tire sensor.";
CM_ SG_ 2566897971 TIRE3_TireSensorElectricalFault "Indicates the Sts of electrical fault on the tire sensor.";
CM_ SG_ 2566897971 TIRE3_TireTemThresholdDetection "Signal indicating the Temperature level of the tire. The levels defined represent different temperatureconditions of the tire.";
CM_ SG_ 2566834739 DM1_TPMS_ProtectLamp "保护灯状态";
CM_ SG_ 2566834739 DM1_TPMS_AmberWarningLamp "琥珀色警示灯状态";
CM_ SG_ 2566834739 DM1_TPMS_RedStopLamp "红色停止灯状态";
CM_ SG_ 2566834739 DM1_TPMS_MalfunctionLamp "故障指示灯状态";
CM_ SG_ 2566834739 DM1_TPMS_SAELamp_Reserved "SAE保留分配灯状态";
CM_ SG_ 2566834739 DM1_TPMS_SPN_LeastSignificantBit "故障SPN的8个最低有效位（CM=0）
（第8位是最高有效位）";
CM_ SG_ 2566834739 DM1_TPMS_SPN_secondByteOfSPN "故障SPN的第二字节（CM=0）
（第8位是最高有效位）";
CM_ SG_ 2566834739 DM1_TPMS_FMI "FMI用于定义对SPN标识的子系统检测到的故障的类型（第5位是最高有效位）";
CM_ SG_ 2566834739 DM1_TPMS_SPN3MmostSignificantBit "SPN， 3个最高有效位
（第8位是最高有效位）";
CM_ SG_ 2566834739 DM1_TPMS_OccurrenceCount "故障发生次数
标识该故障由当前故障转变为历史故障的次数，如果故障发生次数不可知则全置位1";
CM_ SG_ 2566834739 DM1_TPMS_SPNConversionMethod "故障SPN转换方式（CM）";
CM_ SG_ 2364539648 EEC2_AccelPedal1LowIdleSwitch "Switch signal which indicates the state of the accelerator pedal 1 low idle switch.";
CM_ SG_ 2364539648 EEC2_AccelPedalKickdownSwitch "Switch signal which indicates whether the accelerator pedal kickdown switch is opened or closed.";
CM_ SG_ 2364539648 EEC2_AccelPedalPstn "The ratio of actual accelerator pedal position to maximum pedal position. Although it is used as aninput to determine powertrain demand, it also provides anticipatory information to transmission andASR algorithms about driver actions.";
CM_ SG_ 2364539648 EEC2_PercentLoadAtCurrentSpd "The ratio of actual engine percent torque (indicated) to maximum indicated torque available at thecurrent engine speed, clipped to zero torque during engine braking";
CM_ SG_ 2348810282 TSC1_ACCE_EngOvrrdCtrlMode "The override Ctrl mode defines which sort of Cmd is used.
发动机控制模式";
CM_ SG_ 2348810282 TSC1_ACCE_ReqSpdCtrlConditions "This mode tells the Eng Ctrl Sys the governor characteristics that are desired during speed Ctrl.
速度控制时用的
0x0:针对传动系统脱离和非锁定情况进行的瞬态优化
0x1:为传动系统脱离和非锁定条件优化的稳定性
0x2:针对传动系统啮合和/或处于锁定状态1的稳定性进行了优化
0x3:为传动系统啮合和/或处于锁定状态而优化的稳定性2";
CM_ SG_ 2348810282 TSC1_ACCE_OvrrdCtrlModePriority "This field is used as an input to the Eng or retarder to determine thepriority of the Override Ctrl Mode received in theTorque/Speed Ctrl message (see PGN 0). The default is 11 (Low priority). It is not required to use the same priority duringthe entire override function. For example, the transmission can use priority 01 (High priority) during a shift, but can set thepriority to 11 (Low priority) at the end of the shift to allow traction Ctrl to also interact with the torque limit of the Eng.
该字段被用作发动机或减速机的输入，以确定在转矩/速度控制消息中接收到的超驰控制模式的优先级(参见PGN 0)。默认值是11(低优先级)。在整个override函数中不需要使用相同的优先级。例如，变速器在换挡时可以使用优先级01(高优先级)，但在换挡结束时可以将优先级设置为11(低优先级)，以便牵引力控制也可以与发动机的扭矩限制相互作用。";
CM_ SG_ 2348810282 TSC1_ACCE_EngReqTrqOrTrqLim "Parameter provided to the Eng or retarder in the torque/speed Ctrl message for Ctrlling or limiting the output torque.Reqed torque to the Eng is measured in indicated torque as a percentage of reference Eng torque. This is the Engtorque at which the Eng is expected to operate if the torque Ctrl mode is active or the Eng torque which the Eng is notexpected to exceed if the torque limit mode is active
在转矩/速度控制信息中提供给发动机或减速机的参数，用于控制或限制输出转矩。要求的发动机转矩是用指示转矩作为参考发动机转矩的百分比来测量的。这是在转矩控制模式为Auto模式时发动机预期运行的发动机转矩，或在转矩限制模式为Auto模式时发动机预期不会超过的发动机转矩";
CM_ SG_ 2348810282 TSC1_ACCE_TransRate "This parameter indicates the transmission rate at which the sending device will transmit the TSC1 message. The Eng shall Adj its timeout for TSC1 messages accordingly. Variable TSC1 transmission rates shall only apply to messages sent to the Eng.
该参数表示发送设备发送TSC1消息的传输速率。引擎应相应地调整TSC1消息的超时时间。可变的TSC1传输速率仅适用于发送到发动机的消息。";
CM_ SG_ 2348810282 TSC1_ACCE_CtrlPurpose "Sts signal which indicates which Ctrl mode the sending device is using to generate the TSC1 Cmd. Note that the modes are not in prioritized order. Not all modes may be relevant for a given device. Some devices may not implement all functions. The TSC1 Ctrl purpose shall only apply to messages sent to the Eng.
指示发送设备使用哪种控制模式来生成TSC1命令。注意，这些模式并不是按照优先顺序排列的。并非所有模式都适用于特定设备。有些设备可能不能实现所有的功能。TSC1的控制用途仅适用于发送给发动机的消息。";
CM_ SG_ 2348810282 TSC1_ACCE_EngReqTrqHR "This parameter displays an additional torque in percent of the reference Eng torque.
发动机扭矩请求的小数部分";
CM_ SG_ 2348810282 TSC1_ACCE_MessageCounter "The message counter is used to detect situations where the transmitting ECU malfunction repeats the same frame all the time.The receiver of the formation may use the counter parameter to detect this situation. The transmitting device will increase themessage counter in every cycle. The message counter will count from 0 to 7 and then wrap. The values 0x8 thru 0xE are SAEreserved and should be ignored by the receiver.Value 0xF (all bits set to 1) will indicate that the message counter is not available.For co";
CM_ SG_ 2348810282 TSC1_ACCE_MessageChecksum "The message checksum is used to verify the signal path from the transmitting device to the receiving device.The message checksum is calculated using the first 7 data bytes, the message counter and the bytes of the messageidentifier. It is calculated as follows:Checksum = (Byte1 + Byte2 + Byte3 + Byte4 + Byte5 + Byte6 + Byte7 + message counter & 0x0F + message ID low byte +message ID mid low byte + message ID mid high byte + message ID high byte)Message Checksum = (((Checksum >> 6) & 0x03) + (Checksum >>3)";
CM_ SG_ 2349075360 XBR2_ExtAccelDemand "Parameter provided to the Brk Sys from external sources. This is the Acc which the Brk Sys is expected torealize. It is specified as an absolute Acc in reference to the road. Pstv values lead to increasing Vhcl speed,Ngtv values lead to decreasing Vhcl speed.Note: Normally only the Ngtv data range is used,but e.g. in case of downhilldriving also Pstv values are possible.";
CM_ SG_ 2349075360 XBR2_EBIMode "The XBR EBI (Endurance Brk Integration) Mode is used as an input for the Brk Sys to prescribe the use of enduranceBrks like retarders or Eng Brks.";
CM_ SG_ 2349075360 XBR2_Priority "The XBR Priority is used as an input to the Brk Sys to manage the priority of overlapping external and internal Reqs.";
CM_ SG_ 2349075360 XBR2_CtrlMode "The XBR Ctrl Mode is used as an input to the Brk Sys and defines how the external Acc demand has to berealized.";
CM_ SG_ 2349075360 XBR2_MessageCounter "The XBR message counter is to verify the signal path from the demanding device to the brakecontroller on electronic brake systems";
CM_ SG_ 2349075360 XBR2_MessageChecksum "The XBR message checksum is used to verify the signal path from the demanding device to the brakecontroller on electronic brake systems.The 4 bit XBR message checksum is calculated using the first 7 data bytes, the 4 bit message counterand the bytes of the message identifier. It is calculated as follows:Checksum = (Byte1 + Byte2 + Byte3 + Byte4 + Byte5 + Byte6 + Byte7 + message counter&0x0F +message ID low byte + message ID mid low byte + message ID mid high byte + message ID highbyte)XBR Message Checksum = ((Checksum >> 4) + Checksum) & 0x0F";
CM_ SG_ 2348875814 TC1_ADU_TransReqGear "Negative values are reverse gears, positive values are forward gears, zero is neutral.";
CM_ BO_ 2566864170 "Electronic Parking Brk 2";
CM_ SG_ 2566864170 EPB2_ExtPressDemandForEPB "External pressure demand for Electronic Parking Brake
FE: Error
FF: Not available";
CM_ SG_ 2566864170 EPB2_ExtInhibitReqForPBRelease "External inhibition request for Parking Brake release";
CM_ SG_ 2566864170 EPB2_ExtInhibitReqForPBApply "External inhibition request for Parking Brake application";
CM_ SG_ 2566864170 EPB2_ExtApplyReqForEPB "External application request for Electronic Parking Brake";
CM_ SG_ 2566864170 EPB2_ExtReleaseReqForEPB "External release request for Electronic Parking Brake";
CM_ SG_ 2566864170 EPB2_AutoDrvState "智驾模式";
CM_ SG_ 2566864170 EPB2_MessageCounter "The message counter is to verify the signal path from the demanding device to the brake controller onelectronic brake systems.";
CM_ SG_ 2566864170 EPB2_MessageChecksum "Checksum = (Byte1 + Byte2 + Byte3 + Byte4 + Byte5 + Byte6 + Byte7 + message counter&0x0F +message ID low byte + message ID mid low byte + message ID mid high byte + message ID highbyte)Message Checksum = ((Checksum >> 4) + Checksum) & 0x0F";
CM_ SG_ 2566857510 ADU1_ADUStat "表示ADU实际工作状态。接口说明：VCU接收控制模式为沿变模式， ADU控制需按照周期性发送，且需发送5个连续的控制模式0，然后发送控制模式1.备注：如当前不满足ADU控制模式，（VCU自动驾驶相关状态报文中信号AutoToManualTips会说明不满足的条件），在满足条件后，仍然需要发送5个连续的控制模式0，然后发送控制模式1，才能进入无人模式.";
CM_ SG_ 2566857510 ADU1_ADUTargetSpd "Ego truck target speed";
CM_ SG_ 2566857510 ADU1_ADUBrakeSwitch "ADU发送的制动开关信号";
CM_ SG_ 2566857510 ADU1_ADUTargetAccel "Ego truck target acceleration";
CM_ SG_ 2566858534 ADU_Cmd_FrontWiperSwitchCmd "该信号表示雨刮开关控制命令，用于ADV控制BCM驱动雨刮。";
CM_ SG_ 2566858534 ADU_Cmd_FrontWasherSwitchCmd "该信号表示洗涤开关控制命令，用于ADV控制BCM驱动雨刷。";
CM_ SG_ 2566858534 ADU_Cmd_ADUToBCM "该信号表示ADV对BCM的请求控制命令。";
CM_ SG_ 2566858534 ADU_Cmd_DrvDoor1UnlockReq "该信号表示主驾驶侧车门解闭锁请求，用于ADV控制DCM。";
CM_ SG_ 2566858534 ADU_Cmd_PassengerDoor2UnlockReq "该信号表示副驾驶侧车门解闭锁请求，用于ADV控制DCM。";
CM_ SG_ 2566858534 ADU_Cmd_BackBrakeLightCmd "该信号表示后制动开关，用于ADV控制BCM点亮后制动灯。";
CM_ SG_ 2566858534 ADU_Cmd_HornCmd "该信号用于控制前后喇叭命令。";
CM_ SG_ 2566779431 VCU_Status_VCUMode "表示VCU实际工作模式状态。";
CM_ SG_ 2566779431 VCU_Status_ManualBrakeSwitch "表示VCU发送的制动开关信号。注：只有有人踩下才会变化";
CM_ SG_ 2566779431 VCU_Status_ManualAccelPedalPstn "表示VCU发送的油门开关信号。注：只有有人踩下才会变化";
CM_ SG_ 2566779431 VCU_Status_VCUAutoToManualTips "16个位分别代表不同的条件：
位1：舒适CAN总线关闭；
位2：动力CAN总线关闭；
位3：ADV控制模式报文超时；
位4：ADV扭矩请求报文CS/LC故障；
位5：手刹开关拉下；
位6：挂车手刹开关拉下；
位7：巡航激活；
位8：油门踩下大于一定阈值；
位9：油门踏板故障时；
位10：刹车踏板踩下；
位11：刹车踏板故障时；
位12：智能驾驶功能屏蔽。";
CM_ SG_ 2566779431 VCU_Status_ActualMaxDrivePctTrq "Actual_Max_Available_Drive_Pct_Torque
当前状态下电机能够提供的最大实时相对驱动参考扭矩值的百分比，不包含此时的滑行扭矩值。";
CM_ SG_ 2566769953 OWW_FrontOperatorWiperSwitch "State of operation selected by operator switch for the Wiper in front of the operator position.";
CM_ SG_ 2566769953 OWW_FrontOperatorWasherSwitch "State of operation selected by operator switch for the washer in front of the operator position.";
CM_ BO_ 2566849057 "Swch_Cmd";
CM_ SG_ 2566849057 SC_IGOffPostnLightAlert "Signal which indicates Postn light alert Sts. When alert condition is meeted, 0x1 is sent";
CM_ SG_ 2566849057 SC_LDWSwitchStat "Signal which indicates LDW Swch Sts. It is the nonlocking Swch, the signal value should be 1 during the Swch be pressed
LDW开关状态，自复位开关";
CM_ SG_ 2566849057 SC_FCWSwitchStat "Signal which indicates FCW Swch Sts. It is the nonlocking Swch, the signal value should be 1during the Swch be pressed";
CM_ SG_ 2566849057 SC_ReverseGearSwitch "Indicates the Sts of reverse gear Swch.";
CM_ SG_ 2566849057 SC_RearWorkLampSwitch "Indicates the Sts of rear work lamp Swch";
CM_ SG_ 2566849057 SC_SleepAreaLightSwitch "Swch signal which indicates the Sts of “sleep area light“. It is the nonlocking Swch, the signal valueshould be 1 during the Swch be pressed.";
CM_ SG_ 2566849057 SC_IndoorLightSwitch "Swch signal which indicates the Sts of “indoor light“. It is the nonlocking Swch, the signal valueshould be 1 during the Swch be pressed";
CM_ SG_ 2566849057 SC_HornSwitch "Swch signal which indicates the Sts of menu “horn“. It is the nonlocking Swch, the signal valueshould be 1 during the Swch be pressed.";
CM_ SG_ 2566849057 SC_HornSelectionSwitch "indicate the selected Postn of the horn selection Swch";
CM_ SG_ 2566849057 SC_CabDoorWarnOFFSwitch "indicate the cab door Warn off Swch";
CM_ SG_ 2566849057 SC_AutoLightCtrlSwitch "indicate the auto light Ctrl Swch";
CM_ SG_ 2566848801 BCU_IgnitionPstn "点火开关状态";
CM_ SG_ 2566848801 BCU_DriverSeatBeltAlert "Indicates whether the Drv's side safety belt is not fastened to alarm";
CM_ SG_ 2566848801 BCU_PassengerSeatBeltAlert "Indicates whether the Pasgr side safety belt is not fastened to alarm";
CM_ SG_ 2566849575 HCU_BMS_HCUSysStat "表示整车控制器系统工作状态：";
CM_ SG_ 2566849575 HCU_BMS_ReadyToDriveStat "表示整车运行准备就绪状态。";
CM_ SG_ 2566849575 HCU_BMS_PermitCharge "Indicates whether Charge is allowed.";
CM_ SG_ 2566849575 HCU_BMS_EnduranceMileage "Indicates the mileage, used for the display of the instrument.The actual physical value range is 0km-500km";
CM_ SG_ 2566849575 HCU_BMS_SleepCmd "Indicates the sleep Cmd sent by HCU. After receiving it, the receiving node realizes the sleep wakefunction according to the network sleep wake strategy.";
CM_ SG_ 2566849575 HCU_BMS_HighVoltSysFailStat "Indicates High Voltage System Failure Status.
Level 1 failure: alarm；
Level 2 failure: limit；
Level 2 failure: Shut Down";
CM_ SG_ 2566862323 BMS1_PowerBattVolt "Represents the power Battary Voltage.The actual physical value ranges from 0V to 1000V.";
CM_ SG_ 2566862323 BMS1_PowerBattCurrent "Represents power Batt Curr, Ngtv value represents charge, Pstv value represents discharge.";
CM_ SG_ 2566862323 BMS1_PowerBattSOC "Represents the remaining charge of the power Batt";
CM_ SG_ 2566862323 BMS1_PowerBattSysStat "Represents the Current working Status of the power Battary System.The first alarm is a general fault;The secondary alarm is a serious fault; (limited power)Three-level alarm for emergency failure; (electricity)";
CM_ SG_ 2566862323 BMS1_PowerBattChargeReq "Indicates whether there is a charge Req.000：No charge Req before charge ready001：When the Chrg is ready, send the Chrg Req010：Req Chrg stop in case of recoverable fault (reservation)011：Unrecoverable fault occurs, Req for Chrg (reservation)";
CM_ SG_ 2566862323 BMS1_PowerBattChargeStat "Represents the Current Charge Status of the power Battary";
CM_ SG_ 2566862323 BMS1_PowerBattHeatStat "Indicates the heating Sts of the power Batt";
CM_ SG_ 2566862323 BMS1_MsgCounter "The message counter is used to detect situations where the transmitting ECU malfunction repeats thesame frame all the time. The receiver of the formation may use the counter parameter to detect thissituation. The transmitting device will increase the message counter in every cycle. The message counterwill count from 0 to 7 and then wrap. The values 0x8 thru 0xE are SAE reserved and should be ignoredby the receiver.Value 0xF (all bits set to 1) will indicate that the message counter is not available. Forcompatibility purposes, TSC1 should also be honored if the message counter is not available from thetransmitting device.";
CM_ SG_ 2566862323 BMS1_MsgChecksum "Message checksum is used to verify the signal transmission path from the sending device to the receivingdevice. The checksum is the sum of the following data: the sum of the message ID from high to lowbytes, the first seven bytes of the data area, and the message counter. The checksum calculation formulais as follows:Checksum = (byte 1 + byte 2 + byte 3 + byte 4 + byte 5 + byte 6 + byte 7 + message counter & 0x0F +message ID low byte + message ID medium low byte + message ID high byte + message ID high byte)Checksum = ((checksum >> 4) + checksum) & 0x0FThe checksum value 0x0F indicates that the checksum is not available.";
CM_ SG_ 2566863603 BMS5_BMSMainNgtvCoilDrvStat "BMS primary negative coil drive state";
CM_ SG_ 2566863603 BMS5_PowerBattSOH "Represents the Batt health Sts, and the value range is 0-100%.";
CM_ SG_ 2566863603 BMS5_MainNgtvRelayDisconnectReq "Main Negative Relay Disconnect Request
Represents that BMS sends the main-Ngtv relay disconnect Req to HCU:
When the HCU has no response, the BMS will actively disconnect the main-Ngtv relay after 30s";
CM_ SG_ 2566863603 BMS5_MainNgtvRelayStat "Represents the state of the main-negative relay:";
CM_ SG_ 2566863603 BMS5_BattPackHeatCtrlCmdPstv "Indicates the Battery Pack Heating Positive Relay Control Command Signal";
CM_ SG_ 2566863603 BMS5_BattPackHeatCtrlCmdNgtv "Indicates the Battery Pack Heating Negative Relay Control Command Signal";
CM_ SG_ 2566863603 BMS5_ChargePlugConnectionStat "ndicates the connection Sts of the Chrg plug.If the dual gun is charged, the signal indicates cc2-1.";
CM_ SG_ 2566863603 BMS5_ChargePlug2ConnectionStat "Represents the connection Sts of Chrg plug 2. The signal can only be obtained when the dual gun ischarged (cc2-2)";
CM_ SG_ 2566863603 BMS5_ChargeRelayStatPstv "Represents the state of charging positive relay.";
CM_ SG_ 2566863603 BMS5_ChargeRelayStatNgtv "Represents the state of charging positive relay.";
CM_ BO_ 2566840343 "Vhcl Distance";
CM_ SG_ 2566840343 VD_TripDistance "Distance traveled during all or part of a journey.

NOTE See SPN 918 for alternate resolution.";
CM_ SG_ 2566840343 VD_TotalVehDistance "Accumulated distance traveled by Vhcl during its operation.

NOTE See SPN 917 for alternate resolution.";
CM_ SG_ 2566834721 DM1_BCM_AmberWarningLamp "琥珀色警示灯状态
当检测到车辆系统存在非关键性故障时，需要点亮琥珀色报警灯。这时，并不要求立即停车处理";
CM_ SG_ 2566834721 DM1_BCM_RedStopLamp "红色停止灯状态
如果检测到的危险性故障，会设置红色报警状态。这时，车辆必须停止。";
CM_ SG_ 2566834721 DM1_BCM_SAELamp_Reserved "SAE保留分配灯状态";
CM_ SG_ 2566834721 DM1_BCM_SPN8_LeastSignificantBit "SPN， 8个最低有效位
（第8位是最高有效位）";
CM_ SG_ 2566834721 DM1_BCM_SPN_secondByteOfSPN "SPN， SPN第二字节
（第8位是最高有效位）";
CM_ SG_ 2566834721 DM1_BCM_FMI "FMI用于定义对SPN标识的子系统检测到的故障的类型";
CM_ SG_ 2566834721 DM1_BCM_SPN3MmostSignificantBit "SPN， 3个最高有效位
（第8位是最高有效位）";
CM_ SG_ 2566834721 DM1_BCM_OccurrenceCount "标识该故障由当前故障转变为历史故障的次数，如果故障发生次数不可知则全置位1";
CM_ SG_ 2566834721 DM1_BCM_SPNConversionMethod "SPN转换方式,始终是0";
CM_ SG_ 2348814378 TSC1_ACCDR_EngOvrrdCtrlMode "The override Ctrl mode defines which sort of Cmd is used.
发动机控制模式";
CM_ SG_ 2348814378 TSC1_ACCDR_ReqSpdCtrlConditions "This mode tells the Eng Ctrl Sys the governor characteristics that are desired during speed Ctrl.
速度控制时用的
0x0:针对传动系统脱离和非锁定情况进行的瞬态优化
0x1:为传动系统脱离和非锁定条件优化的稳定性
0x2:针对传动系统啮合和/或处于锁定状态1的稳定性进行了优化
0x3:为传动系统啮合和/或处于锁定状态而优化的稳定性2";
CM_ SG_ 2348814378 TSC1_ACCDR_OvrrdCtrlModePriority "This field is used as an input to the Eng or retarder to determine thepriority of the Override Ctrl Mode received in theTorque/Speed Ctrl message (see PGN 0). The default is 11 (Low priority). It is not required to use the same priority duringthe entire override function. For example, the transmission can use priority 01 (High priority) during a shift, but can set thepriority to 11 (Low priority) at the end of the shift to allow traction Ctrl to also interact with the torque limit of the Eng.
该字段被用作发动机或减速机的输入，以确定在转矩/速度控制消息中接收到的超驰控制模式的优先级(参见PGN 0)。默认值是11(低优先级)。在整个override函数中不需要使用相同的优先级。例如，变速器在换挡时可以使用优先级01(高优先级)，但在换挡结束时可以将优先级设置为11(低优先级)，以便牵引力控制也可以与发动机的扭矩限制相互作用。";
CM_ SG_ 2348814378 TSC1_ACCDR_EngReqTrqOrTrqLim "Parameter provided to the Eng or retarder in the torque/speed Ctrl message for Ctrlling or limiting the output torque.Reqed torque to the Eng is measured in indicated torque as a percentage of reference Eng torque. This is the Engtorque at which the Eng is expected to operate if the torque Ctrl mode is active or the Eng torque which the Eng is notexpected to exceed if the torque limit mode is active
在转矩/速度控制信息中提供给发动机或减速机的参数，用于控制或限制输出转矩。要求的发动机转矩是用指示转矩作为参考发动机转矩的百分比来测量的。这是在转矩控制模式为Auto模式时发动机预期运行的发动机转矩，或在转矩限制模式为Auto模式时发动机预期不会超过的发动机转矩";
CM_ SG_ 2348814378 TSC1_ACCDR_TransRate "This parameter indicates the transmission rate at which the sending device will transmit the TSC1 message. The Eng shall Adj its timeout for TSC1 messages accordingly. Variable TSC1 transmission rates shall only apply to messages sent to the Eng.
该参数表示发送设备发送TSC1消息的传输速率。引擎应相应地调整TSC1消息的超时时间。可变的TSC1传输速率仅适用于发送到发动机的消息。";
CM_ SG_ 2348814378 TSC1_ACCDR_CtrlPurpose "Sts signal which indicates which Ctrl mode the sending device is using to generate the TSC1 Cmd. Note that the modes are not in prioritized order. Not all modes may be relevant for a given device. Some devices may not implement all functions. The TSC1 Ctrl purpose shall only apply to messages sent to the Eng.
指示发送设备使用哪种控制模式来生成TSC1命令。注意，这些模式并不是按照优先顺序排列的。并非所有模式都适用于特定设备。有些设备可能不能实现所有的功能。TSC1的控制用途仅适用于发送给发动机的消息。";
CM_ SG_ 2348814378 TSC1_ACCDR_EngReqTrqHR "This parameter displays an additional torque in percent of the reference Eng torque.
发动机扭矩请求的小数部分";
CM_ SG_ 2348814378 TSC1_ACCDR_MessageCounter "The message counter is used to detect situations where the transmitting ECU malfunction repeats the same frame all the time.The receiver of the formation may use the counter parameter to detect this situation. The transmitting device will increase themessage counter in every cycle. The message counter will count from 0 to 7 and then wrap. The values 0x8 thru 0xE are SAEreserved and should be ignored by the receiver.Value 0xF (all bits set to 1) will indicate that the message counter is not available.For co";
CM_ SG_ 2348814378 TSC1_ACCDR_MessageChecksum "The message checksum is used to verify the signal path from the transmitting device to the receiving device.The message checksum is calculated using the first 7 data bytes, the message counter and the bytes of the messageidentifier. It is calculated as follows:Checksum = (Byte1 + Byte2 + Byte3 + Byte4 + Byte5 + Byte6 + Byte7 + message counter & 0x0F + message ID low byte +message ID mid low byte + message ID mid high byte + message ID high byte)Message Checksum = (((Checksum >> 6) & 0x03) + (Checksum >>3)";
CM_ SG_ 2566841127 EC_EM1_EngSpdAtPoint1 "Stationary low idle speed of engine which includes influences due to engine temperature (after powerup) and other stationary changes (calibration offsets, sensor failures, etc).This parameter is point 1 ofthe engine configuration map";
CM_ SG_ 2566841127 EC_EM1_EngReferenceTrq "This parameter is the 100% reference value for all defined indicated engine torque parameters. It isonly defined once and doesn't change if a different engine torque map becomes valid.";
CM_ SG_ 2566841127 EC_EM1_SupportVariableRateTSC1 "This parameter indicates which TSC1 transmission rates are supported by the engine ECU in additionto the required 10ms transmission rate for temporary powertrain control purposes. Suggest to send 0xEF.";
CM_ SG_ 2566894099 EPS1_SteerWheelAng "方向盘转向角度，用于表示方向盘实际角度大小";
CM_ SG_ 2566894099 EPS1_MotorAssistTrq "电机助力扭矩，用于表示电机助力扭矩";
CM_ SG_ 2566894099 EPS1_SteerAngSpd "方向盘反馈角速度，用于表示方向盘角速度";
CM_ SG_ 2566894099 EPS1_HandTrq "手力矩信号，用于表示手力矩";
CM_ SG_ 2566894099 EPS1_EPSStat "EPS控制器状态，表示EPS目前状态";
CM_ SG_ 2566894099 EPS1_MessageCounter "报文计数器用于检测由于报文发送者故障导致重复发生同一帧报文。报文接收者可以使用报文计数器检测到这种情况。报文发送者在每个报文发送周期令报文计数器增1，报文计时器从0开始计数直到15，然后再从0开始计数";
CM_ SG_ 2566894099 EPS1_MessageChecksum "报文校验和用于验证从发送设备到接收设备的信号传输路径。校验和是下述数据的和：报文ID由高字节至低字节的和、数据区前7个字节以及报文计数器。校验和计算公式如下：校验和 = (字节1 + 字节2 + 字节3 + 字节4 + 字节5 + 字节6 + 字节7 + 报文计数器 &0x0F + 报文ID低字节 + 报文ID中低字节 + 报文ID中高字节 + 报文ID高字节)校验和 = ((校验和 >> 4) + 校验和) & 0x0F";
CM_ SG_ 2566893862 ADV_EPS_TargetSteerWheelCmd "目标方向盘转向指令角度,用于表示目标方向盘指令角度";
CM_ SG_ 2566893862 ADV_EPS_OperateMode "表示ADV对EPS工作模式指令";
CM_ SG_ 2566893862 ADV_EPS_ADVStatus "ADV状态";
CM_ SG_ 2566893862 ADV_EPS_SteerAngleStat "转向角指令状态";
CM_ SG_ 2566893862 ADV_EPS_SteerAdditionalTrq "转向叠加扭矩信号";
CM_ SG_ 2566893862 ADV_EPS_SteerAngSpd "方向盘目标角速度，实际取值范围50~540";
CM_ SG_ 2566893862 ADV_EPS_MessageCounter "报文计数器用于检测由于报文发送者故障导致重复发生同一帧报文。报文接收者可以使用报文计数器检测到这种情况。报文发送者在每个报文发送周期令报文计数器增1，报文计时器从0开始计数直到15，然后再从0开始计数。";
CM_ SG_ 2566893862 ADV_EPS_MessageChecksum "报文校验和用于验证从发送设备到接收设备的信号传输路径。校验和是下述数据的和：报文ID由高字节至低字节的和、数据区前7个字节以及报文计数器。校验和计算公式如下：校验和 = (字节1 + 字节2 + 字节3 + 字节4 + 字节5 + 字节6 + 字节7 + 报文计数器 &0x0F + 报文ID低字节 + 报文ID中低字节 + 报文ID中高字节 + 报文ID高字节)校验和 = ((校验和 >> 4) + 校验和) & 0x0F";
CM_ SG_ 2566799393 LD_RunLight "行车灯状态";
CM_ SG_ 2566799393 LD_LowBeamHeadLightData "近光灯状态";
CM_ SG_ 2566799393 LD_HighBeamHeadLightData "远光灯状态";
CM_ SG_ 2566799393 LD_RightTurnSignalLights "右转向灯状态";
CM_ SG_ 2566799393 LD_LeftTurnSignalLights "左转向灯状态";
CM_ SG_ 2566799393 LD_FrontFogLights "前雾灯的状态";
CM_ SG_ 2566799393 LD_RearFogLights "后雾灯的状态";
CM_ SG_ 2566799393 LD_BackUpLightAndAlarmHorn "倒车灯和蜂鸣器状态";
CM_ SG_ 2566799393 LD_CenterStopLight "This parameter provides measured data from the tractor and attached implement center stop lights.";
CM_ SG_ 2566799393 LD_ImplementMarkerLightData "表示位置灯的状态";
CM_ SG_ 2566860065 BCM_Status_BCMRespStat "表示BCM对ADV的响应状态。";
CM_ SG_ 2566860065 BCM_Status_BackBrakeLightStat "表示后制动灯的实际状态。";
CM_ SG_ 2566860065 BCM_Status_HornStat "表示前后喇叭的实际控制状态。";
CM_ SG_ 2566860065 BCM_Status_WiperStat "表示雨刮控制状态";
CM_ SG_ 2566834931 DM1_BMS_AmberWarningLamp "琥珀色警示灯状态
当检测到车辆系统存在非关键性故障时，需要点亮琥珀色报警灯。这时，并不要求立即停车处理";
CM_ SG_ 2566834931 DM1_BMS_RedStopLamp "红色停止灯状态
如果检测到的危险性故障，会设置红色报警状态。这时，车辆必须停止。";
CM_ SG_ 2566834931 DM1_BMS_SAELamp_Reserved "SAE保留分配灯状态";
CM_ SG_ 2566834931 DM1_BMS_SPN8_LeastSignificantBit "SPN， 8个最低有效位
（第8位是最高有效位）";
CM_ SG_ 2566834931 DM1_BMS_SPN_secondByteOfSPN "SPN， SPN第二字节
（第8位是最高有效位）";
CM_ SG_ 2566834931 DM1_BMS_FMI "FMI用于定义对SPN标识的子系统检测到的故障的类型";
CM_ SG_ 2566834931 DM1_BMS_SPN3MmostSignificantBit "SPN， 3个最高有效位
（第8位是最高有效位）";
CM_ SG_ 2566834931 DM1_BMS_OccurrenceCount "标识该故障由当前故障转变为历史故障的次数，如果故障发生次数不可知则全置位1";
CM_ SG_ 2566834931 DM1_BMS_SPNConversionMethod "SPN转换方式,始终是0";
CM_ SG_ 2566834784 DM1_PTU_AmberWarningLamp "琥珀色警示灯状态
当检测到车辆系统存在非关键性故障时，需要点亮琥珀色报警灯。这时，并不要求立即停车处理";
CM_ SG_ 2566834784 DM1_PTU_RedStopLamp "红色停止灯状态
如果检测到的危险性故障，会设置红色报警状态。这时，车辆必须停止。";
CM_ SG_ 2566834784 DM1_PTU_SAELamp_Reserved "SAE保留分配灯状态";
CM_ SG_ 2566834784 DM1_PTU_SPN8_LeastSignificantBit "SPN， 8个最低有效位
（第8位是最高有效位）";
CM_ SG_ 2566834784 DM1_PTU_SPN_secondByteOfSPN "SPN， SPN第二字节
（第8位是最高有效位）";
CM_ SG_ 2566834784 DM1_PTU_FMI "FMI用于定义对SPN标识的子系统检测到的故障的类型";
CM_ SG_ 2566834784 DM1_PTU_SPN3MmostSignificantBit "SPN， 3个最高有效位
（第8位是最高有效位）";
CM_ SG_ 2566834784 DM1_PTU_OccurrenceCount "标识该故障由当前故障转变为历史故障的次数，如果故障发生次数不可知则全置位1";
CM_ SG_ 2566834784 DM1_PTU_SPNConversionMethod "SPN转换方式,始终是0";
CM_ SG_ 2566834741 DM1_DCDC2_AmberWarningLamp "琥珀色警示灯状态
当检测到车辆系统存在非关键性故障时，需要点亮琥珀色报警灯。这时，并不要求立即停车处理";
CM_ SG_ 2566834741 DM1_DCDC2_RedStopLamp "红色停止灯状态
如果检测到的危险性故障，会设置红色报警状态。这时，车辆必须停止。";
CM_ SG_ 2566834741 DM1_DCDC2_SAELamp_Reserved "SAE保留分配灯状态";
CM_ SG_ 2566834741 DM1_DCDC2_SPN_LeastSgnificantBit "SPN， 8个最低有效位
（第8位是最高有效位）";
CM_ SG_ 2566834741 DM1_DCDC2_SPN_secondByteOfSPN "SPN， SPN第二字节
（第8位是最高有效位）";
CM_ SG_ 2566834741 DM1_DCDC2_FMI "FMI用于定义对SPN标识的子系统检测到的故障的类型";
CM_ SG_ 2566834741 DM1_DCDC2_SPNMmostSignificantBit "SPN， 3个最高有效位
（第8位是最高有效位）";
CM_ SG_ 2566834741 DM1_DCDC2_OccurrenceCount "标识该故障由当前故障转变为历史故障的次数，如果故障发生次数不可知则全置位1";
CM_ SG_ 2566834741 DM1_DCDC2_SPNConversionMethod "SPN转换方式,始终是0";
CM_ SG_ 2566834736 DM1_APCU_AmberWarningLamp "琥珀色警示灯状态
当检测到车辆系统存在非关键性故障时，需要点亮琥珀色报警灯。这时，并不要求立即停车处理";
CM_ SG_ 2566834736 DM1_APCU_RedStopLamp "红色停止灯状态
如果检测到的危险性故障，会设置红色报警状态。这时，车辆必须停止。";
CM_ SG_ 2566834736 DM1_APCU_SAELamp_Reserved "SAE保留分配灯状态";
CM_ SG_ 2566834736 DM1_APCU_SPN_LeastSignificantBit "SPN， 8个最低有效位
（第8位是最高有效位）";
CM_ SG_ 2566834736 DM1_APCU_SPN_secondByteOfSPN "SPN， SPN第二字节
（第8位是最高有效位）";
CM_ SG_ 2566834736 DM1_APCU_FMI "FMI用于定义对SPN标识的子系统检测到的故障的类型";
CM_ SG_ 2566834736 DM1_APCU_SPN3MmostSignificantBit "SPN， 3个最高有效位
（第8位是最高有效位）";
CM_ SG_ 2566834736 DM1_APCU_OccurrenceCount "标识该故障由当前故障转变为历史故障的次数，如果故障发生次数不可知则全置位1";
CM_ SG_ 2566834736 DM1_APCU_SPNConversionMethod "SPN转换方式,始终是0";
CM_ SG_ 2566849516 FBCM_DriverWindowSwitch "Indicates the status of driver window switch.Used the signal to collect data for frequency statistics.";
CM_ SG_ 2566849516 FBCM_DriverCtrlPasgrWindowSwitch "Indicates the status of driver control passenger window switch.Used the signal to collect data forfrequency statistics.";
CM_ SG_ 2566849516 FBCM_PassengerWindowSwitch "Indicates the status of passenger window switch.Used the signal to collect data for frequencystatistics.";
CM_ SG_ 2566849516 FBCM_CabDoorsLockSwitch "Indicates the status of cab doors lock/unlock central control switch.Used the signal to collect data forfrequency statistics.";
CM_ SG_ 2566849516 FBCM_BackMirrorHeatSwitch "Swch signal which indicates the Sts of menu “back Mirr heat“. It is the nonlocking Swch, thesignal value should be 1 during the Swch be pressed";
CM_ SG_ 2566849516 FBCM_BackMirrorSelectSwitch "Indicates the status of back mirror selection switch..";
CM_ SG_ 2566849516 FBCM_BackMirrorAdjustSwch "indicate the selected position of the back mirror adjustment switch.";
CM_ SG_ 2566849516 FBCM_VehAntiTheftStat "Indicates the status of vehicle anti-theft.";
CM_ SG_ 2566849516 FBCM_RmtLightInspectCmd "Indicates the command of light inspection. DCM is the arbitration of light inspection function whichactivated by remote key.";
CM_ SG_ 2566849516 FBCM_RmtSearchVehCmd "Indicates the command of remote search vehicle and light self-inspection. DCM is the arbitration ofremote search vechicle function which activated by remote key.";
CM_ SG_ 2566849516 FBCM_LockOrUnlockSuccessAlert "Signal which indicates whether there is a lock/unlock success alert.If Lock/Unlock is not success, then 0x3 is sent.";
CM_ SG_ 2566849516 FBCM_RMKeyBattStat "indicate status of current remote key battery. If the current remote key battery is too low, signalRMKeyBatterySt will be set to warning driver change remote key battery.";
CM_ BO_ 2632777552 "refer to 《SAE J1939-21 SURFACE Vhcl RECOMMENDED PRACTICE：Data Link Layer》";
CM_ BO_ 2632712016 "refer to 《SAE J1939-21 SURFACE Vhcl RECOMMENDED PRACTICE：Data Link Layer》";
CM_ BO_ 2632777483 "refer to 《SAE J1939-21 SURFACE Vhcl RECOMMENDED PRACTICE：Data Link Layer》";
CM_ BO_ 2632711947 "refer to 《SAE J1939-21 SURFACE Vhcl RECOMMENDED PRACTICE：Data Link Layer》";
CM_ BO_ 2632777491 "refer to 《SAE J1939-21 SURFACE Vhcl RECOMMENDED PRACTICE：Data Link Layer》";
CM_ BO_ 2632711955 "refer to 《SAE J1939-21 SURFACE Vhcl RECOMMENDED PRACTICE：Data Link Layer》";
CM_ BO_ 2632777505 "refer to 《SAE J1939-21 SURFACE Vhcl RECOMMENDED PRACTICE：Data Link Layer》";
CM_ BO_ 2632711969 "refer to 《SAE J1939-21 SURFACE Vhcl RECOMMENDED PRACTICE：Data Link Layer》";
CM_ BO_ 2632777523 "refer to 《SAE J1939-21 SURFACE Vhcl RECOMMENDED PRACTICE：Data Link Layer》";
CM_ BO_ 2632711987 "refer to 《SAE J1939-21 SURFACE Vhcl RECOMMENDED PRACTICE：Data Link Layer》";
CM_ BO_ 2632777715 "refer to 《SAE J1939-21 SURFACE Vhcl RECOMMENDED PRACTICE：Data Link Layer》";
CM_ BO_ 2632712179 "refer to 《SAE J1939-21 SURFACE Vhcl RECOMMENDED PRACTICE：Data Link Layer》";
CM_ BO_ 2632777511 "refer to 《SAE J1939-21 SURFACE VEHICLE RECOMMENDED PRACTICE：Data Link Layer》";
CM_ BO_ 2632711975 "refer to 《SAE J1939-21 SURFACE VEHICLE RECOMMENDED PRACTICE：Data Link Layer》";
CM_ BO_ 2632777568 "refer to 《SAE J1939-21 SURFACE VEHICLE RECOMMENDED PRACTICE：Data Link Layer》";
CM_ BO_ 2632712032 "refer to 《SAE J1939-21 SURFACE VEHICLE RECOMMENDED PRACTICE：Data Link Layer》";
CM_ BO_ 2632777525 "refer to 《SAE J1939-21 SURFACE VEHICLE RECOMMENDED PRACTICE：Data Link Layer》";
CM_ BO_ 2632711989 "refer to 《SAE J1939-21 SURFACE VEHICLE RECOMMENDED PRACTICE：Data Link Layer》";
CM_ BO_ 2632777520 "refer to 《SAE J1939-21 SURFACE VEHICLE RECOMMENDED PRACTICE：Data Link Layer》";
CM_ BO_ 2632711984 "refer to 《SAE J1939-21 SURFACE VEHICLE RECOMMENDED PRACTICE：Data Link Layer》";
CM_ BO_ 2298375691 "此报文非解放输入";
CM_ SG_ 2298375691 HRW_FrontAxleLeftWheelSpd "High resolution measurement of the speed of the left wheel on the front axle.";
CM_ SG_ 2298375691 HRW_FrontAxleRightWheelSpd "High resolution measurement of the speed of the right wheel on the front axle.";
CM_ SG_ 2298375691 HRW_RearAxleLeftWheelSpd "High resolution measurement of the speed of the left wheel on the rear axle.";
CM_ SG_ 2298375691 HRW_RearAxleRightWheelSpd "High resolution measurement of the speed of the right wheel on the rear axle.";
CM_ BO_ 2566913318 "ADU工作状态，ADU需要发送该报文以使IGW判断ADU要激活控车";
CM_ SG_ 2566913318 ADUSt_ADCtrlStat "ADU自动驾驶控制状态：
Init：上电默认Init；
Standby：ADU自检无误后进入Standby；急停结束后进入Standby；
Passive：ADU不满足使能（激活）条件；
Active：ADU控车激活，Active时IGW视为ADU线控激活，当无更高优先级控制源激活时，开始路由ADU线控报文；
Error：ADU自身检测到故障；";
CM_ SG_ 2566913318 ADUSt_EBStat "1.ADU紧急制动状态，ADU触发紧急制动时，将该信号置1；
2.ADU将此信号置1时，应同时发送制动线控报文；
3.网关不会根据该信号自行紧急制动，制动控制由ADU进行；";
CM_ SG_ 2566913318 ADUSt_EBSrc "ADU进行紧急制动的触发源，表示当前ADU进行紧急制动的动作，是从哪里来的指令.
0x0:当前无紧急制动命令；
0x1:当前紧急制动由ADU自行发起，如ADU检测远程控制指令超时、异常，或检测到车辆关键执行器出现故障等；
0x2:当前紧急制动由后台操作急停发起；
0x3:人工按下车辆急停按键触发急停（预留）；";
CM_ SG_ 2566913318 ADUSt_ADCtrlReq "1.在具备自动驾驶的车辆上，ADU主动向云端发起的远程代驾请求，如当ADU检测到自身故障时，主动向云端发起远程代驾请求；信号状态由RDU收到后发给后台
2.信号值1和2用于区分请求的紧急程度；";
CM_ BO_ 2566906109 "IGW工作状态反馈";
CM_ SG_ 2566906109 IGWSt_IGWStat "IGW工作状态：
Init：上电默认Init；
Standby：IGW自检后进入Standby，此时IGW往ADCAN上发送默认报文，不路由任何控制源报文；
Passive：IGW检测不满足外部线控激活条件；
Routing：IGW路由上传控制器的线控报文；
AEB：IGW自动触发紧急停车；
Error：IGW自身检测到故障；";
CM_ SG_ 2566906109 IGWSt_RouteStat "1.当前网关路由的线控报文源头，即网关仲裁后的响应指令源；Default为IGW往ADCAN上发送默认报文，不路由任何控制源报文；
2.网关根据RDU_RmtCtrlStat/RCU_RmtCtrlStat/ADU_ADCtrlStat的Active状态，进行响应，优先级顺序为RCU>RDU>ADU;
3.IGW主动触发紧急制动，此时状态置置0x4";
CM_ SG_ 2566906109 IGWSt_ErrorStat "IGW检测到的故障状态，每个bit表示1个故障状态，置1时表示故障产生
bit0：IGW硬件故障；                    bit1：IGW软件故障；
bit2：CAN通信异常-ADC AN；   bit5：CAN通信异常-RDU CAN；
bit6：CAN通信异常-RCU CAN； bit7~bit15：预留";
BA_DEF_ BU_  "NmCAN" INT 1 2;
BA_DEF_ BU_  "NodeLayerModules" STRING ;
BA_DEF_ BU_  "ILUsed" ENUM  "No","Yes";
BA_DEF_ SG_  "GenSigSendType" ENUM  "Cycle","CyclicX","Event","OnChange","OnWrite","IfActive","OnChangeWithRepetition","OnWriteWithRepetition","IfActiveWithRepetition","NoSigSendType","OnChangeAndIfActive","OnChangeAndIfActiveWithRepetition","CA","CE","SpontanX","On Request";
BA_DEF_ SG_  "SPN" INT 0 0;
BA_DEF_ SG_  "GenSigInactiveValue" HEX 0 0;
BA_DEF_ SG_  "GenSigStartValue" HEX 0 0;
BA_DEF_ SG_  "GenSigInvalidValue" HEX 0 0;
BA_DEF_  "Baudrate" INT 0 1000000;
BA_DEF_  "NmMessageCount" INT 0 255;
BA_DEF_  "NmBaseAddress" HEX 0 2047;
BA_DEF_  "BusType" STRING ;
BA_DEF_  "VersionYear" INT 2010 2999;
BA_DEF_  "ProtocolType" STRING ;
BA_DEF_  "DBName" STRING ;
BA_DEF_  "NmType" STRING ;
BA_DEF_ BO_  "DiagResponse" ENUM  "No","Yes";
BA_DEF_ BO_  "GenMsgCycleTimeFast" INT 0 0;
BA_DEF_ BO_  "GenMsgSendType" ENUM  "Cycle","CyclicX","Event","NoMsgSendType","IfActive","SpontanX","CA","CE","On Request";
BA_DEF_ BO_  "GenMsgNrOfRepetition" INT 0 0;
BA_DEF_ BO_  "GenMsgStartDelayTime" INT 0 0;
BA_DEF_ BO_  "VFrameFormat" ENUM  "StandardCAN","ExtendedCAN","StandardCAN_FD","ExtendedCAN_FD","StandardCAN_FD","ExtendedCAN_FD","J1939PG";
BA_DEF_ BO_  "GenMsgCycleTime" INT 0 0;
BA_DEF_ BO_  "GenMsgDelayTime" INT 0 0;
BA_DEF_ BO_  "DiagRequest" ENUM  "No","Yes";
BA_DEF_ BO_  "GenMsgILSupport" ENUM  "No","Yes";
BA_DEF_DEF_  "NmCAN" 2;
BA_DEF_DEF_  "NodeLayerModules" "OSEKNM01.dll,CANoeILNLVector.dll";
BA_DEF_DEF_  "ILUsed" "Yes";
BA_DEF_DEF_  "GenSigSendType" "Cycle";
BA_DEF_DEF_  "SPN" 0;
BA_DEF_DEF_  "GenSigInactiveValue" 0;
BA_DEF_DEF_  "GenSigStartValue" 0;
BA_DEF_DEF_  "GenSigInvalidValue" 0;
BA_DEF_DEF_  "Baudrate" 500000;
BA_DEF_DEF_  "NmMessageCount" 128;
BA_DEF_DEF_  "NmBaseAddress" 1536;
BA_DEF_DEF_  "BusType" "CAN";
BA_DEF_DEF_  "VersionYear" 2019;
BA_DEF_DEF_  "ProtocolType" "";
BA_DEF_DEF_  "DBName" "";
BA_DEF_DEF_  "NmType" "OSEK";
BA_DEF_DEF_  "DiagResponse" "No";
BA_DEF_DEF_  "GenMsgCycleTimeFast" 0;
BA_DEF_DEF_  "GenMsgSendType" "Cycle";
BA_DEF_DEF_  "GenMsgNrOfRepetition" 0;
BA_DEF_DEF_  "GenMsgStartDelayTime" 0;
BA_DEF_DEF_  "VFrameFormat" "StandardCAN";
BA_DEF_DEF_  "GenMsgCycleTime" 100;
BA_DEF_DEF_  "GenMsgDelayTime" 0;
BA_DEF_DEF_  "DiagRequest" "No";
BA_DEF_DEF_  "GenMsgILSupport" "Yes";
BA_ "ProtocolType" "J1939";
BA_ "DBName" "J6F_ADUCAN";
BA_ "VFrameFormat" BO_ 2566844672 6;
BA_ "VFrameFormat" BO_ 2565866755 6;
BA_ "GenMsgCycleTime" BO_ 2566834768 1000;
BA_ "VFrameFormat" BO_ 2566834768 6;
BA_ "VFrameFormat" BO_ 2566863952 6;
BA_ "GenMsgCycleTime" BO_ 2566834699 1000;
BA_ "VFrameFormat" BO_ 2566834699 6;
BA_ "VFrameFormat" BO_ 2565865739 6;
BA_ "VFrameFormat" BO_ 2566831883 6;
BA_ "VFrameFormat" BO_ 2566767627 6;
BA_ "GenMsgSendType" BO_ 2566811659 8;
BA_ "GenMsgCycleTime" BO_ 2566811659 0;
BA_ "VFrameFormat" BO_ 2566811659 6;
BA_ "GenMsgCycleTime" BO_ 2565867787 10;
BA_ "VFrameFormat" BO_ 2565867787 6;
BA_ "VFrameFormat" BO_ 2365473062 6;
BA_ "GenMsgCycleTime" BO_ 2365473057 35;
BA_ "VFrameFormat" BO_ 2365473057 6;
BA_ "VFrameFormat" BO_ 2566759713 6;
BA_ "GenMsgCycleTime" BO_ 2365578991 10;
BA_ "VFrameFormat" BO_ 2365578991 6;
BA_ "GenMsgCycleTime" BO_ 2566834707 1000;
BA_ "VFrameFormat" BO_ 2566834707 6;
BA_ "GenMsgCycleTime" BO_ 2566845491 500;
BA_ "VFrameFormat" BO_ 2566845491 6;
BA_ "GenMsgCycleTime" BO_ 2566668851 500;
BA_ "VFrameFormat" BO_ 2566668851 6;
BA_ "GenMsgCycleTime" BO_ 2566897971 500;
BA_ "VFrameFormat" BO_ 2566897971 6;
BA_ "GenMsgCycleTime" BO_ 2566834739 1000;
BA_ "VFrameFormat" BO_ 2566834739 6;
BA_ "GenMsgCycleTime" BO_ 2364539648 50;
BA_ "VFrameFormat" BO_ 2364539648 6;
BA_ "GenMsgSendType" BO_ 2348810282 2;
BA_ "GenMsgCycleTimeFast" BO_ 2348810282 10;
BA_ "GenMsgCycleTime" BO_ 2348810282 0;
BA_ "VFrameFormat" BO_ 2348810282 6;
BA_ "GenMsgCycleTime" BO_ 2349075360 20;
BA_ "VFrameFormat" BO_ 2349075360 6;
BA_ "GenMsgCycleTime" BO_ 2348875814 50;
BA_ "VFrameFormat" BO_ 2348875814 6;
BA_ "VFrameFormat" BO_ 2566864170 6;
BA_ "VFrameFormat" BO_ 2566857510 6;
BA_ "GenMsgCycleTime" BO_ 2566858534 20;
BA_ "VFrameFormat" BO_ 2566858534 6;
BA_ "VFrameFormat" BO_ 2566779431 6;
BA_ "GenMsgCycleTime" BO_ 2566769953 200;
BA_ "VFrameFormat" BO_ 2566769953 6;
BA_ "VFrameFormat" BO_ 2566849057 6;
BA_ "VFrameFormat" BO_ 2566848801 6;
BA_ "VFrameFormat" BO_ 2566849575 6;
BA_ "VFrameFormat" BO_ 2566862323 6;
BA_ "GenMsgCycleTime" BO_ 2566863603 20;
BA_ "VFrameFormat" BO_ 2566863603 6;
BA_ "VFrameFormat" BO_ 2566840343 6;
BA_ "GenMsgCycleTime" BO_ 2566834721 1000;
BA_ "VFrameFormat" BO_ 2566834721 6;
BA_ "GenMsgSendType" BO_ 2348814378 2;
BA_ "GenMsgCycleTimeFast" BO_ 2348814378 50;
BA_ "GenMsgCycleTime" BO_ 2348814378 0;
BA_ "VFrameFormat" BO_ 2348814378 6;
BA_ "GenMsgCycleTime" BO_ 2566841127 5000;
BA_ "VFrameFormat" BO_ 2566841127 6;
BA_ "GenMsgCycleTime" BO_ 2566894099 20;
BA_ "VFrameFormat" BO_ 2566894099 6;
BA_ "GenMsgCycleTime" BO_ 2566893862 20;
BA_ "VFrameFormat" BO_ 2566893862 6;
BA_ "VFrameFormat" BO_ 2566799393 6;
BA_ "VFrameFormat" BO_ 2566860065 6;
BA_ "GenMsgCycleTime" BO_ 2566834931 1000;
BA_ "VFrameFormat" BO_ 2566834931 6;
BA_ "GenMsgCycleTime" BO_ 2566834784 1000;
BA_ "VFrameFormat" BO_ 2566834784 6;
BA_ "GenMsgCycleTime" BO_ 2566834741 1000;
BA_ "VFrameFormat" BO_ 2566834741 6;
BA_ "GenMsgCycleTime" BO_ 2566834736 1000;
BA_ "VFrameFormat" BO_ 2566834736 6;
BA_ "VFrameFormat" BO_ 2566849516 6;
BA_ "GenMsgSendType" BO_ 2632777552 3;
BA_ "GenMsgCycleTime" BO_ 2632777552 0;
BA_ "VFrameFormat" BO_ 2632777552 6;
BA_ "GenMsgSendType" BO_ 2632712016 3;
BA_ "GenMsgCycleTime" BO_ 2632712016 0;
BA_ "VFrameFormat" BO_ 2632712016 6;
BA_ "GenMsgSendType" BO_ 2632777483 3;
BA_ "GenMsgCycleTime" BO_ 2632777483 0;
BA_ "VFrameFormat" BO_ 2632777483 6;
BA_ "GenMsgSendType" BO_ 2632711947 3;
BA_ "GenMsgCycleTime" BO_ 2632711947 0;
BA_ "VFrameFormat" BO_ 2632711947 6;
BA_ "GenMsgSendType" BO_ 2632777491 3;
BA_ "GenMsgCycleTime" BO_ 2632777491 0;
BA_ "VFrameFormat" BO_ 2632777491 6;
BA_ "GenMsgSendType" BO_ 2632711955 3;
BA_ "GenMsgCycleTime" BO_ 2632711955 0;
BA_ "VFrameFormat" BO_ 2632711955 6;
BA_ "GenMsgSendType" BO_ 2632777505 3;
BA_ "GenMsgCycleTime" BO_ 2632777505 0;
BA_ "VFrameFormat" BO_ 2632777505 6;
BA_ "GenMsgSendType" BO_ 2632711969 3;
BA_ "GenMsgCycleTime" BO_ 2632711969 0;
BA_ "VFrameFormat" BO_ 2632711969 6;
BA_ "GenMsgSendType" BO_ 2632777523 3;
BA_ "GenMsgCycleTime" BO_ 2632777523 0;
BA_ "VFrameFormat" BO_ 2632777523 6;
BA_ "GenMsgSendType" BO_ 2632711987 3;
BA_ "GenMsgCycleTime" BO_ 2632711987 0;
BA_ "VFrameFormat" BO_ 2632711987 6;
BA_ "GenMsgSendType" BO_ 2632777715 3;
BA_ "GenMsgCycleTime" BO_ 2632777715 0;
BA_ "VFrameFormat" BO_ 2632777715 6;
BA_ "GenMsgSendType" BO_ 2632712179 3;
BA_ "GenMsgCycleTime" BO_ 2632712179 0;
BA_ "VFrameFormat" BO_ 2632712179 6;
BA_ "GenMsgSendType" BO_ 2632777511 3;
BA_ "GenMsgCycleTime" BO_ 2632777511 0;
BA_ "VFrameFormat" BO_ 2632777511 6;
BA_ "GenMsgSendType" BO_ 2632711975 3;
BA_ "GenMsgCycleTime" BO_ 2632711975 0;
BA_ "VFrameFormat" BO_ 2632711975 6;
BA_ "GenMsgSendType" BO_ 2632777568 3;
BA_ "GenMsgCycleTime" BO_ 2632777568 0;
BA_ "VFrameFormat" BO_ 2632777568 6;
BA_ "GenMsgSendType" BO_ 2632712032 3;
BA_ "GenMsgCycleTime" BO_ 2632712032 0;
BA_ "VFrameFormat" BO_ 2632712032 6;
BA_ "GenMsgSendType" BO_ 2632777525 3;
BA_ "GenMsgCycleTime" BO_ 2632777525 0;
BA_ "VFrameFormat" BO_ 2632777525 6;
BA_ "GenMsgSendType" BO_ 2632711989 3;
BA_ "GenMsgCycleTime" BO_ 2632711989 0;
BA_ "VFrameFormat" BO_ 2632711989 6;
BA_ "GenMsgSendType" BO_ 2632777520 3;
BA_ "GenMsgCycleTime" BO_ 2632777520 0;
BA_ "VFrameFormat" BO_ 2632777520 6;
BA_ "GenMsgSendType" BO_ 2632711984 3;
BA_ "GenMsgCycleTime" BO_ 2632711984 0;
BA_ "VFrameFormat" BO_ 2632711984 6;
BA_ "GenMsgCycleTime" BO_ 2298375691 20;
BA_ "VFrameFormat" BO_ 2298375691 6;
BA_ "VFrameFormat" BO_ 2566913318 6;
BA_ "VFrameFormat" BO_ 2566906109 6;
BA_ "SPN" SG_ 2566844672 CCVS1_PBSwitch 70;
BA_ "SPN" SG_ 2566844672 CCVS1_WheelBasedVehSpd 84;
BA_ "GenSigStartValue" SG_ 2566844672 CCVS1_CruiseCtrlSetSpd 255;
BA_ "GenSigStartValue" SG_ 2565866755 ETC2_TransSelectedGear 125;
BA_ "SPN" SG_ 2565866755 ETC2_TransSelectedGear 524;
BA_ "SPN" SG_ 2565866755 ETC2_TransActualGearRatio 526;
BA_ "GenSigStartValue" SG_ 2565866755 ETC2_TransCurrentGear 125;
BA_ "SPN" SG_ 2565866755 ETC2_TransCurrentGear 523;
BA_ "GenSigStartValue" SG_ 2566834768 DM1_EPB_SAELamp_Reserved 255;
BA_ "GenSigStartValue" SG_ 2566863952 EPB1_PstnOfEPBHCU 125;
BA_ "SPN" SG_ 2565865739 EBC1_ASREngCtrlActive 561;
BA_ "SPN" SG_ 2565865739 EBC1_ASRBrakeCtrlActive 562;
BA_ "SPN" SG_ 2565865739 EBC1_ABSActive 563;
BA_ "SPN" SG_ 2565865739 EBC1_EBSBrakeSwitch 1121;
BA_ "SPN" SG_ 2565865739 EBC1_BrakePedalPstn 521;
BA_ "SPN" SG_ 2565865739 EBC1_ABSOffroadSwitch 575;
BA_ "SPN" SG_ 2565865739 EBC1_ASROffroadSwitch 576;
BA_ "SPN" SG_ 2565865739 EBC1_ASRHillHolderSwitch 577;
BA_ "SPN" SG_ 2565865739 EBC1_ABSFullyOperational 1243;
BA_ "SPN" SG_ 2565865739 EBC1_EBSRedWarnSignal 1439;
BA_ "SPN" SG_ 2565865739 EBC1_ABSOrEBSAmberWarnSignal 1438;
BA_ "SPN" SG_ 2565865739 EBC1_ATCOrASRInfoSignal 1793;
BA_ "SPN" SG_ 2565865739 EBC1_SourceAddressOfCtrlDevice 1481;
BA_ "SPN" SG_ 2565865739 EBC1_TractorMountTrailerABSWarn 1792;
BA_ "GenSigStartValue" SG_ 2566831883 EBC2_RelativeSpdFrontAxleLWhl 125;
BA_ "GenSigStartValue" SG_ 2566831883 EBC2_RelativeSpdFrontAxleRWhl 125;
BA_ "GenSigStartValue" SG_ 2566831883 EBC2_RelativeSpdRearAxle1LWhl 125;
BA_ "GenSigStartValue" SG_ 2566831883 EBC2_RelativeSpdRearAxle1RWhl 125;
BA_ "GenSigStartValue" SG_ 2566831883 EBC2_RelativeSpdRearAxle2LWhl 125;
BA_ "GenSigStartValue" SG_ 2566831883 EBC2_RelativeSpdRearAxle2RWhl 125;
BA_ "GenSigStartValue" SG_ 2566767627 EBC5_XBRAccelLim 125;
BA_ "GenSigSendType" SG_ 2566811659 CVW_PoweredVehWeight 3;
BA_ "GenSigStartValue" SG_ 2566811659 CVW_PoweredVehWeight 65535;
BA_ "GenSigSendType" SG_ 2566811659 CVW_GrossCombineVehWeight 3;
BA_ "GenSigStartValue" SG_ 2566811659 CVW_GrossCombineVehWeight 65535;
BA_ "SPN" SG_ 2566811659 CVW_GrossCombineVehWeight 1760;
BA_ "GenSigStartValue" SG_ 2565867787 VDC2_SteerWheelAng 32128;
BA_ "GenSigStartValue" SG_ 2565867787 VDC2_SteerWheelTurnCounter 32;
BA_ "GenSigStartValue" SG_ 2565867787 VDC2_YawRate 32128;
BA_ "GenSigStartValue" SG_ 2565867787 VDC2_LateralAccel 32128;
BA_ "GenSigStartValue" SG_ 2565867787 VDC2_LongitudinalAccel 125;
BA_ "SPN" SG_ 2365473062 LC_ADU_RunLightCmd 2403;
BA_ "SPN" SG_ 2365473057 LC_RunLightCmd 2403;
BA_ "SPN" SG_ 2365473057 LC_LowBeamHeadLightCmd 2349;
BA_ "SPN" SG_ 2365473057 LC_HighBeamHeadLightCmd 2347;
BA_ "SPN" SG_ 2365473057 LC_TractorFrontFogLightsCmd 2387;
BA_ "SPN" SG_ 2365473057 LC_RightTurnSignalLightsCmd 2369;
BA_ "SPN" SG_ 2365473057 LC_LeftTurnSignalLightsCmd 2367;
BA_ "SPN" SG_ 2365473057 LC_BackUpLightAndAlarmHornCmd 2391;
BA_ "SPN" SG_ 2365473057 LC_CenterStopLightCmd 2375;
BA_ "SPN" SG_ 2365473057 LC_RearFogLightCmd 2389;
BA_ "SPN" SG_ 2566759713 DC2_OpenStatOfDoor1 3413;
BA_ "SPN" SG_ 2566759713 DC2_OpenStatOfDoor2 3416;
BA_ "GenSigStartValue" SG_ 2365578991 MCU1_ActualMotorTrqHR 15;
BA_ "GenSigStartValue" SG_ 2365578991 MCU1_MaxOutputMotorTrqHR 15;
BA_ "GenSigStartValue" SG_ 2365578991 MCU1_MotorTrq 125;
BA_ "GenSigStartValue" SG_ 2365578991 MCU1_MaxOutputMotorTrq 125;
BA_ "GenSigStartValue" SG_ 2566834707 DM1_EPS_SAELamp_Reserved 255;
BA_ "GenSigStartValue" SG_ 2566845491 TIRE1_Location 255;
BA_ "SPN" SG_ 2566845491 TIRE1_Location 929;
BA_ "GenSigStartValue" SG_ 2566845491 TIRE1_Press 255;
BA_ "SPN" SG_ 2566845491 TIRE1_Press 521033;
BA_ "GenSigStartValue" SG_ 2566845491 TIRE1_Temp 65535;
BA_ "SPN" SG_ 2566845491 TIRE1_Temp 521111;
BA_ "GenSigStartValue" SG_ 2566845491 TIRE1_Stat 3;
BA_ "SPN" SG_ 2566845491 TIRE1_Stat 521333;
BA_ "GenSigStartValue" SG_ 2566845491 TIRE1_ExtendTirePressSupport 3;
BA_ "SPN" SG_ 2566845491 TIRE1_ExtendTirePressSupport 6990;
BA_ "GenSigStartValue" SG_ 2566845491 TIRE1_AirLeakageRate 65535;
BA_ "SPN" SG_ 2566845491 TIRE1_AirLeakageRate 521533;
BA_ "GenSigStartValue" SG_ 2566845491 TIRE1_PressThresholdDetect 7;
BA_ "SPN" SG_ 2566845491 TIRE1_PressThresholdDetect 521613;
BA_ "GenSigStartValue" SG_ 2566668851 TIRE2_Location 255;
BA_ "SPN" SG_ 2566668851 TIRE2_Location 6987;
BA_ "GenSigStartValue" SG_ 2566668851 TIRE2_PressExtendRange 65535;
BA_ "SPN" SG_ 2566668851 TIRE2_PressExtendRange 6988;
BA_ "GenSigStartValue" SG_ 2566668851 TIRE2_ReqTirePress 65535;
BA_ "SPN" SG_ 2566668851 TIRE2_ReqTirePress 6989;
BA_ "GenSigStartValue" SG_ 2566897971 TIRE3_TireLocation 255;
BA_ "GenSigStartValue" SG_ 2566897971 TIRE3_TireSensorMatchStat 3;
BA_ "GenSigStartValue" SG_ 2566897971 TIRE3_TireSensorSelfLearningStat 7;
BA_ "GenSigStartValue" SG_ 2566897971 TIRE3_TireSensorElectricalFault 3;
BA_ "GenSigStartValue" SG_ 2566897971 TIRE3_TireTemThresholdDetection 2;
BA_ "GenSigStartValue" SG_ 2566834739 DM1_TPMS_SAELamp_Reserved 255;
BA_ "GenSigSendType" SG_ 2348810282 TSC1_ACCE_EngOvrrdCtrlMode 6;
BA_ "SPN" SG_ 2348810282 TSC1_ACCE_EngOvrrdCtrlMode 695;
BA_ "GenSigSendType" SG_ 2348810282 TSC1_ACCE_ReqSpdCtrlConditions 6;
BA_ "GenSigSendType" SG_ 2348810282 TSC1_ACCE_OvrrdCtrlModePriority 6;
BA_ "GenSigStartValue" SG_ 2348810282 TSC1_ACCE_OvrrdCtrlModePriority 3;
BA_ "SPN" SG_ 2348810282 TSC1_ACCE_OvrrdCtrlModePriority 897;
BA_ "GenSigSendType" SG_ 2348810282 TSC1_ACCE_EngReqTrqOrTrqLim 6;
BA_ "GenSigStartValue" SG_ 2348810282 TSC1_ACCE_EngReqTrqOrTrqLim 125;
BA_ "SPN" SG_ 2348810282 TSC1_ACCE_EngReqTrqOrTrqLim 518;
BA_ "GenSigSendType" SG_ 2348810282 TSC1_ACCE_TransRate 6;
BA_ "GenSigSendType" SG_ 2348810282 TSC1_ACCE_CtrlPurpose 6;
BA_ "GenSigSendType" SG_ 2348810282 TSC1_ACCE_EngReqTrqHR 6;
BA_ "SPN" SG_ 2348810282 TSC1_ACCE_EngReqTrqHR 4191;
BA_ "GenSigSendType" SG_ 2348810282 TSC1_ACCE_MessageCounter 6;
BA_ "SPN" SG_ 2348810282 TSC1_ACCE_MessageCounter 4206;
BA_ "GenSigSendType" SG_ 2348810282 TSC1_ACCE_MessageChecksum 6;
BA_ "SPN" SG_ 2348810282 TSC1_ACCE_MessageChecksum 4207;
BA_ "GenSigStartValue" SG_ 2348875814 TC1_ADU_TransReqGear 255;
BA_ "GenSigStartValue" SG_ 2566858534 ADU_Cmd_ADUToBCM 15;
BA_ "GenSigStartValue" SG_ 2566858534 ADU_Cmd_DrvDoor1UnlockReq 3;
BA_ "GenSigStartValue" SG_ 2566858534 ADU_Cmd_PassengerDoor2UnlockReq 3;
BA_ "GenSigStartValue" SG_ 2566858534 ADU_Cmd_HornCmd 3;
BA_ "GenSigStartValue" SG_ 2566769953 OWW_FrontOperatorWiperSwitch 15;
BA_ "SPN" SG_ 2566769953 OWW_FrontOperatorWiperSwitch 2863;
BA_ "GenSigStartValue" SG_ 2566769953 OWW_FrontOperatorWasherSwitch 7;
BA_ "SPN" SG_ 2566769953 OWW_FrontOperatorWasherSwitch 2866;
BA_ "GenSigStartValue" SG_ 2566849057 SC_HornSelectionSwitch 3;
BA_ "GenSigStartValue" SG_ 2566849057 SC_CabDoorWarnOFFSwitch 3;
BA_ "GenSigStartValue" SG_ 2566849057 SC_AutoLightCtrlSwitch 3;
BA_ "GenSigStartValue" SG_ 2566862323 BMS1_PowerBattCurrent 32000;
BA_ "GenSigStartValue" SG_ 2566863603 BMS5_BMSMainNgtvCoilDrvStat 3;
BA_ "GenSigStartValue" SG_ 2566863603 BMS5_PowerBattSOH 255;
BA_ "GenSigStartValue" SG_ 2566863603 BMS5_MainNgtvRelayDisconnectReq 3;
BA_ "GenSigStartValue" SG_ 2566863603 BMS5_MainNgtvRelayStat 7;
BA_ "GenSigStartValue" SG_ 2566863603 BMS5_BattPackHeatCtrlCmdPstv 3;
BA_ "GenSigStartValue" SG_ 2566863603 BMS5_BattPackHeatCtrlCmdNgtv 3;
BA_ "GenSigStartValue" SG_ 2566863603 BMS5_ChargePlugConnectionStat 3;
BA_ "GenSigStartValue" SG_ 2566863603 BMS5_ChargePlug2ConnectionStat 3;
BA_ "GenSigStartValue" SG_ 2566863603 BMS5_ChargeRelayStatPstv 7;
BA_ "SPN" SG_ 2566840343 VD_TripDistance 244;
BA_ "SPN" SG_ 2566840343 VD_TotalVehDistance 245;
BA_ "GenSigStartValue" SG_ 2566834721 DM1_BCM_SAELamp_Reserved 255;
BA_ "GenSigSendType" SG_ 2348814378 TSC1_ACCDR_EngOvrrdCtrlMode 6;
BA_ "SPN" SG_ 2348814378 TSC1_ACCDR_EngOvrrdCtrlMode 695;
BA_ "GenSigSendType" SG_ 2348814378 TSC1_ACCDR_ReqSpdCtrlConditions 6;
BA_ "GenSigSendType" SG_ 2348814378 TSC1_ACCDR_OvrrdCtrlModePriority 6;
BA_ "GenSigStartValue" SG_ 2348814378 TSC1_ACCDR_OvrrdCtrlModePriority 3;
BA_ "SPN" SG_ 2348814378 TSC1_ACCDR_OvrrdCtrlModePriority 897;
BA_ "GenSigSendType" SG_ 2348814378 TSC1_ACCDR_EngReqTrqOrTrqLim 6;
BA_ "GenSigStartValue" SG_ 2348814378 TSC1_ACCDR_EngReqTrqOrTrqLim 125;
BA_ "SPN" SG_ 2348814378 TSC1_ACCDR_EngReqTrqOrTrqLim 518;
BA_ "GenSigSendType" SG_ 2348814378 TSC1_ACCDR_TransRate 6;
BA_ "GenSigSendType" SG_ 2348814378 TSC1_ACCDR_CtrlPurpose 6;
BA_ "GenSigSendType" SG_ 2348814378 TSC1_ACCDR_EngReqTrqHR 6;
BA_ "SPN" SG_ 2348814378 TSC1_ACCDR_EngReqTrqHR 4191;
BA_ "GenSigSendType" SG_ 2348814378 TSC1_ACCDR_MessageCounter 6;
BA_ "SPN" SG_ 2348814378 TSC1_ACCDR_MessageCounter 4206;
BA_ "GenSigSendType" SG_ 2348814378 TSC1_ACCDR_MessageChecksum 6;
BA_ "SPN" SG_ 2348814378 TSC1_ACCDR_MessageChecksum 4207;
BA_ "SPN" SG_ 2566841127 EC_EM1_EngSpdAtPoint1 188;
BA_ "GenSigStartValue" SG_ 2566841127 EC_EM1_EngReferenceTrq 65535;
BA_ "SPN" SG_ 2566841127 EC_EM1_EngReferenceTrq 544;
BA_ "GenSigStartValue" SG_ 2566841127 EC_EM1_SupportVariableRateTSC1 255;
BA_ "GenSigStartValue" SG_ 2566894099 EPS1_SteerWheelAng 65535;
BA_ "GenSigStartValue" SG_ 2566894099 EPS1_MotorAssistTrq 65535;
BA_ "GenSigStartValue" SG_ 2566894099 EPS1_SteerAngSpd 255;
BA_ "GenSigStartValue" SG_ 2566894099 EPS1_HandTrq 255;
BA_ "GenSigStartValue" SG_ 2566893862 ADV_EPS_TargetSteerWheelCmd 65535;
BA_ "GenSigStartValue" SG_ 2566893862 ADV_EPS_OperateMode 15;
BA_ "GenSigStartValue" SG_ 2566893862 ADV_EPS_ADVStatus 1;
BA_ "GenSigStartValue" SG_ 2566893862 ADV_EPS_SteerAngleStat 1;
BA_ "GenSigStartValue" SG_ 2566893862 ADV_EPS_SteerAdditionalTrq 255;
BA_ "GenSigStartValue" SG_ 2566893862 ADV_EPS_SteerAngSpd 255;
BA_ "GenSigStartValue" SG_ 2566799393 LD_RunLight 3;
BA_ "SPN" SG_ 2566799393 LD_RunLight 2404;
BA_ "GenSigStartValue" SG_ 2566799393 LD_LowBeamHeadLightData 3;
BA_ "SPN" SG_ 2566799393 LD_LowBeamHeadLightData 2350;
BA_ "GenSigStartValue" SG_ 2566799393 LD_HighBeamHeadLightData 3;
BA_ "SPN" SG_ 2566799393 LD_HighBeamHeadLightData 2348;
BA_ "GenSigStartValue" SG_ 2566799393 LD_RightTurnSignalLights 3;
BA_ "SPN" SG_ 2566799393 LD_RightTurnSignalLights 2368;
BA_ "GenSigStartValue" SG_ 2566799393 LD_LeftTurnSignalLights 3;
BA_ "SPN" SG_ 2566799393 LD_LeftTurnSignalLights 2370;
BA_ "GenSigStartValue" SG_ 2566799393 LD_FrontFogLights 3;
BA_ "GenSigStartValue" SG_ 2566799393 LD_RearFogLights 3;
BA_ "GenSigStartValue" SG_ 2566799393 LD_BackUpLightAndAlarmHorn 3;
BA_ "SPN" SG_ 2566799393 LD_BackUpLightAndAlarmHorn 2392;
BA_ "SPN" SG_ 2566799393 LD_CenterStopLight 2376;
BA_ "GenSigStartValue" SG_ 2566799393 LD_ImplementMarkerLightData 3;
BA_ "GenSigStartValue" SG_ 2566860065 BCM_Status_BCMRespStat 15;
BA_ "GenSigStartValue" SG_ 2566860065 BCM_Status_BackBrakeLightStat 3;
BA_ "GenSigStartValue" SG_ 2566860065 BCM_Status_HornStat 3;
BA_ "GenSigStartValue" SG_ 2566860065 BCM_Status_WiperStat 15;
BA_ "GenSigStartValue" SG_ 2566834931 DM1_BMS_SAELamp_Reserved 255;
BA_ "GenSigStartValue" SG_ 2566834784 DM1_PTU_SAELamp_Reserved 255;
BA_ "GenSigStartValue" SG_ 2566834741 DM1_DCDC2_SAELamp_Reserved 255;
BA_ "GenSigStartValue" SG_ 2566834736 DM1_APCU_SAELamp_Reserved 255;
BA_ "GenSigStartValue" SG_ 2566849516 FBCM_DriverWindowSwitch 3;
BA_ "GenSigStartValue" SG_ 2566849516 FBCM_DriverCtrlPasgrWindowSwitch 3;
BA_ "GenSigStartValue" SG_ 2566849516 FBCM_PassengerWindowSwitch 3;
BA_ "GenSigStartValue" SG_ 2566849516 FBCM_CabDoorsLockSwitch 3;
BA_ "GenSigStartValue" SG_ 2566849516 FBCM_BackMirrorHeatSwitch 3;
BA_ "GenSigStartValue" SG_ 2566849516 FBCM_BackMirrorSelectSwitch 3;
BA_ "GenSigStartValue" SG_ 2566849516 FBCM_BackMirrorAdjustSwch 15;
BA_ "GenSigSendType" SG_ 2632777552 TPCM_EPB 9;
BA_ "GenSigSendType" SG_ 2632712016 TPDT_EPB 9;
BA_ "GenSigSendType" SG_ 2632777483 TPCM_EBS 9;
BA_ "GenSigSendType" SG_ 2632711947 TPDT_EBS 9;
BA_ "GenSigSendType" SG_ 2632777491 TPCM_EPS 9;
BA_ "GenSigSendType" SG_ 2632711955 TPDT_EPS 9;
BA_ "GenSigSendType" SG_ 2632777505 TPCM_BCM 9;
BA_ "GenSigSendType" SG_ 2632711969 TPDT_BCM 9;
BA_ "GenSigSendType" SG_ 2632777523 TPCM_TPMS 9;
BA_ "GenSigSendType" SG_ 2632711987 TPDT_TPMS 9;
BA_ "GenSigSendType" SG_ 2632777715 TPCM_BMS 9;
BA_ "GenSigSendType" SG_ 2632712179 TPDT_BMS 9;
BA_ "GenSigSendType" SG_ 2632777511 TPCM_VCU 9;
BA_ "GenSigSendType" SG_ 2632711975 TPDT_VCU 9;
BA_ "GenSigSendType" SG_ 2632777568 TPCM_PTU 9;
BA_ "GenSigSendType" SG_ 2632712032 TPDT_PTU 9;
BA_ "GenSigSendType" SG_ 2632777525 TPCM_DCDC2 9;
BA_ "GenSigSendType" SG_ 2632711989 TPDT_DCDC2 9;
BA_ "GenSigSendType" SG_ 2632777520 TPCM_APCU 9;
BA_ "GenSigSendType" SG_ 2632711984 TPDT_APCU 9;
VAL_ 2566844672 CCVS1_PBSwitch 3 "NA" 2 "Error" 1 "Parking brake set" 0 "Parking brake not set" ;
VAL_ 2566844672 CCVS1_CruiseCtrlPauseSwitch 3 "Not avalable" 2 "Error" 1 "on" 0 "off" ;
VAL_ 2566844672 CruiseCtrlActive 3 "Not available" 2 "Reserved" 1 "Cruise Ctrl Swched on" 0 "Cruise Ctrl Swched off" ;
VAL_ 2566844672 CCVS1_CruiseCtrlEnbSwitch 3 "Not available" 2 "Error" 1 "Cruise Ctrl enabled" 0 "Cruise Ctrl disabled" ;
VAL_ 2566844672 CCVS1_BrakeSwitch 3 "Not available" 2 "Error" 1 "Brk pedal depressed" 0 "Brk pedal Relsd" ;
VAL_ 2566844672 CCVS1_ClutchSwitch 3 "Not available" 2 "Error" 1 "Clutch pedal depressed" 0 "Clutch pedal Relsd" ;
VAL_ 2566844672 CCVS1_CruiseCtrlSetSwitch 3 "Not available" 2 "Error" 1 "Cruise Ctrl activator in Postn “set“" 0 "Cruise Ctrl activator not in the Postn “set“" ;
VAL_ 2566844672 CCVS1_CruiseCtrlResumeSwitch 3 "Not available" 2 "Error" 1 "Cruise Ctrl activator in Postn “resume“" 0 "Cruise Ctrl activator not in the Postn “resume“" ;
VAL_ 2566844672 CCVS1_PTOManagmentState 31 "不可用" 30 "保留" 20 "保留" 19 "PTO设置速度记忆2 PTO set speed memory 2" 18 "PTO设置速度记忆1 PTO set speed memory 1" 17 "预设速度8 Preprogrammed set speed 8" 16 "预设速度7 Preprogrammed set speed 7" 15 "预设速度6 Preprogrammed set speed 6" 14 "预设速度5 Preprogrammed set speed 5" 13 "预设速度4 Preprogrammed set speed 4" 12 "预设速度3 Preprogrammed set speed 3" 11 "预设速度2 Preprogrammed set speed 2" 10 "预设速度1 Preprogrammed set speed 1" 9 "加速器覆盖Accelerator Override" 8 "加速Accelerate" 7 "恢复Resume" 6 "减速Decelerate/Coast" 5 "设定Set" 4 "远程等待Remote Standby" 3 "等待Standby" 2 "远程保持Remote Hold" 1 "保持Hold" 0 "关闭Off/Disabled" ;
VAL_ 2566844672 CCVS1_CruiseCtrlState 7 "Not available" 6 "Accelerator Override" 5 "Set" 4 "Resume" 3 "Decelerate" 2 "Accelerate" 1 "Hold" 0 "Off/Disabled" ;
VAL_ 2566834768 DM1_EPB_ProtectLamp 3 "保留" 2 "保留" 1 "点亮" 0 "关闭" ;
VAL_ 2566834768 DM1_EPB_AmberWarningLamp 3 "保留" 2 "保留" 1 "点亮" 0 "关闭" ;
VAL_ 2566834768 DM1_EPB_RedStopLamp 3 "保留" 2 "保留" 1 "点亮" 0 "关闭" ;
VAL_ 2566834768 DM1_EPB_MalfunctionIndicatorLamp 3 "保留" 2 "保留" 1 "点亮" 0 "关闭" ;
VAL_ 2566863952 EPB1_ReasonForInhibitOfRelease 15 "not available" 14 "error" 4 "Trailer test active" 3 "insufficient air pressure" 2 "External inhibit reason" 1 "Brake pedal not pressed" 0 "no active inhibit reason" ;
VAL_ 2566863952 EPB1_ReasonForInhibitOfApply 15 "not available" 14 "error" 3 "External inhibit reason" 2 "High vehicle speed" 1 "Workshop mode active" 0 "Parking brake apply not inhibited" ;
VAL_ 2566863952 EPB1_AmberWarnLampStat 3 "Take No Action" 2 "Reserved" 1 "Lamp On" 0 "Lamp Off" ;
VAL_ 2566863952 EPB1_RedStopLampStat 3 "Take No Action" 2 "Reserved" 1 "Lamp On" 0 "Lamp Off" ;
VAL_ 2566863952 EPB1_StateOfInhibitOfEPBRelease 2 "Auto and manual release inhibited" 1 "Auto release inhibited" 0 "No release inhibit active" ;
VAL_ 2566863952 EPB1_StateOfEPB 6 "XBR braking active" 5 "Secondary braking active" 3 "Parking brake applying" 2 "Parking brake releasing" 1 "Parking brake applied" 0 "Parking brake not applied" ;
VAL_ 2566863952 EPB1_WorkModeOfEPB 7 "Internal error" 6 "Remote mode active" 5 "Roller Test Bench Mode Active" 3 "Automatic mode active" 2 "Backup mode active" 1 "Workshop mode active" 0 "Normal mode active" ;
VAL_ 2566863952 EPB1_TrailerTestActivationState 3 "not available" 2 "error" 1 "Prking brake in trailer test position" 0 "Prking brake not in trailer test position" ;
VAL_ 2566863952 EPB1_StateOfInhibitOfEPBApply 3 "not available" 2 "error" 1 "parking brake automatic apply inhibited" 0 "parking brake apply not inhibited" ;
VAL_ 2566863952 EPB1_EPBHCUInParkState 3 "not available" 2 "error" 1 "Lever in Position" 0 "Lever not in position" ;
VAL_ 2566863952 EPB1_EPBHCUInReleaseState 3 "not available" 2 "error" 1 "Lever in Position" 0 "Lever not in position" ;
VAL_ 2566834699 DM1_ABS_ProtectLamp 3 "保留" 2 "保留" 1 "点亮" 0 "关闭" ;
VAL_ 2566834699 DM1_ABS_AmberWarningLamp 3 "保留" 2 "保留" 1 "点亮" 0 "关闭" ;
VAL_ 2566834699 DM1_ABS_RedStopLamp 3 "保留" 2 "保留" 1 "点亮" 0 "关闭" ;
VAL_ 2566834699 DM1_ABS_MalfunctionIndicatorLamp 3 "保留" 2 "保留" 1 "点亮" 0 "关闭" ;
VAL_ 2565865739 EBC1_ASREngCtrlActive 3 "NA" 2 "Reserved" 1 "ASR engine control active" 0 "ASR engine control passive but installed" ;
VAL_ 2565865739 EBC1_ASRBrakeCtrlActive 3 "NA" 2 "Reserved" 1 "ASR brake control active" 0 "ASR brake control passive but installed" ;
VAL_ 2565865739 EBC1_ABSActive 3 "NA" 2 "Reserved" 1 "ABS active" 0 "ABS passive but installed" ;
VAL_ 2565865739 EBC1_EBSBrakeSwitch 3 "NA" 2 "Error" 1 "Brake pedal is being pressed" 0 "Brake pedal is not being pressed" ;
VAL_ 2565865739 EBC1_ABSOffroadSwitch 3 "NA" 2 "Error" 1 "ABS off-road switch active" 0 "ABS off-road switch passive" ;
VAL_ 2565865739 EBC1_ASROffroadSwitch 3 "NA" 2 "Error" 1 "ASR off-road switch active" 0 "ASR off-road switch passive" ;
VAL_ 2565865739 EBC1_ASRHillHolderSwitch 3 "NA" 2 "Error" 1 "ASR “hill holder“ switch active" 0 "ASR “hill holder“ switch passive" ;
VAL_ 2565865739 EBC1_ABSFullyOperational 3 "NA" 2 "Reserved" 1 "Fully Operational" 0 "Not Fully Operational" ;
VAL_ 2565865739 EBC1_EBSRedWarnSignal 3 "Take no action" 2 "Reserved" 1 "On" 0 "Off" ;
VAL_ 2565865739 EBC1_ABSOrEBSAmberWarnSignal 3 "Take no action" 2 "Reserved" 1 "On" 0 "Off" ;
VAL_ 2565865739 EBC1_ATCOrASRInfoSignal 3 "Take no action" 2 "Reserved" 1 "On" 0 "Off" ;
VAL_ 2565865739 EBC1_TractorMountTrailerABSWarn 3 "NA" 2 "Reserved" 1 "On" 0 "Off" ;
VAL_ 2566767627 EBC5_BrakeTempWarning 3 "Not available" 2 "Reserved" 1 "Active" 0 "Not Active" ;
VAL_ 2566767627 EBC5_HaltBrakeMode 7 "NA" 6 "Halt brake not functional" 5 "Reserved" 4 "Reserved" 3 "Reserved" 2 "Active, but will change to inactive in a short time. " 1 "Active" 0 "Inactive" ;
VAL_ 2566767627 EBC5_HillHolderMode 7 "NA" 6 "Hill holder not functional" 5 "Reserved" 4 "Reserved" 3 "Reserved" 2 "Active, but will change to inactive in a short time." 1 "Active" 0 "Inactive" ;
VAL_ 2566767627 EBC5_FoundationBrakeUse 3 "NA" 2 "Reserved" 1 "Foundation brakes In use" 0 "Foundation brakes Not in use" ;
VAL_ 2566767627 EBC5_XBRSysState 3 "not available" 2 "No external brake demand will be accepted (e.g. because of fault in brake system)" 1 "Only external brake demand of highest XBR Priority (00) will be accepted (e.g. because the temperature limit of the brake system is exceeded)" 0 "Any external brake demand will be accepted (brake system fully operational)" ;
VAL_ 2566767627 EBC5_XBRActiveCtrlMode 15 " Not available" 14 "Reserved" 4 "Reserved" 3 "Maximum mode of XBR acceleration control being executed" 2 "Addition mode of XBR acceleration control being executed" 1 " Driver's brake demand being executed, no external brake demand" 0 "No brake demand being executed (default mode)" ;
VAL_ 2566767627 EBC5_EmergencyBrakeActive 3 "NA" 2 "Reserved" 1 "Active" 0 "Inactive" ;
VAL_ 2565867787 VDC2_SteerWheelAngSensorType 3 "NA" 2 "Reserved" 1 "Absolute measuring principle" 0 "Relative measuring principle" ;
VAL_ 2365473062 LC_ADU_RunLightCmd 3 "Don't Care" 2 "Reserved" 1 "Activate" 0 "De-activate" ;
VAL_ 2365473062 LC_ADU_LowBeamHeadLightCmd 3 "Don't Care" 2 "Reserved" 1 "Activate" 0 "De-activate" ;
VAL_ 2365473062 LC_ADU_HighBeamHeadLightCmd 3 "Don't Care" 2 "Reserved" 1 "Activate" 0 "De-activate" ;
VAL_ 2365473062 LC_ADU_TractorFrontFogLightsCmd 3 "Don't Care" 2 "Reserved" 1 "Activate" 0 "De-activate" ;
VAL_ 2365473062 LC_ADU_RightTurnSignalLightsCmd 3 "Don't Care" 2 "Reserved" 1 "Activate" 0 "De-activate" ;
VAL_ 2365473062 LC_ADU_LeftTurnSignalLightsCmd 3 "Don't Care" 2 "Reserved" 1 "Activate" 0 "De-activate" ;
VAL_ 2365473062 LC_ADU_BackUpLightAndHornCmd 3 "NA" 2 "Reserved" 1 "Activate" 0 "De-activate" ;
VAL_ 2365473062 LC_ADU_ImplementMarkerLightCmd 3 "Don't Care" 2 "Reserved" 1 "Activate" 0 "De-activate" ;
VAL_ 2365473062 LC_ADU_RearFogLightCmd 3 "Don't Care" 2 "Reserved" 1 "Activate" 0 "De-activate" ;
VAL_ 2365473057 LC_RunLightCmd 3 "Don't Care" 2 "Reserved" 1 "Activate" 0 "De-activate" ;
VAL_ 2365473057 LC_LowBeamHeadLightCmd 3 "Don't Care" 2 "Reserved" 1 "Activate" 0 "De-activate" ;
VAL_ 2365473057 LC_HighBeamHeadLightCmd 3 "Don't Care" 2 "Reserved" 1 "Activate" 0 "De-activate" ;
VAL_ 2365473057 LC_TractorFrontFogLightsCmd 3 "Don't Care" 2 "Reserved" 1 "Activate" 0 "De-activate" ;
VAL_ 2365473057 LC_RightTurnSignalLightsCmd 3 "Don't Care" 2 "Reserved" 1 "Activate" 0 "De-activate" ;
VAL_ 2365473057 LC_LeftTurnSignalLightsCmd 3 "Don't Care" 2 "Reserved" 1 "Activate" 0 "De-activate" ;
VAL_ 2365473057 LC_BackUpLightAndAlarmHornCmd 3 "Don't Care" 2 "Reserved" 1 "Activate" 0 "De-activate" ;
VAL_ 2365473057 LC_CenterStopLightCmd 3 "Don't Care" 2 "Reserved" 1 "Activate" 0 "De-activate" ;
VAL_ 2365473057 LC_ImplementMarkerLightCmd 3 "Don't Care" 2 "Reserved" 1 "Activate" 0 "De-activate" ;
VAL_ 2365473057 LC_RearFogLightCmd 3 "Don't Care" 2 "Reserved" 1 "Activate" 0 "De-activate" ;
VAL_ 2365473057 LC_DriverSideDomeLight 3 "NA" 2 "Error" 1 "Pressed" 0 "Not Pressed" ;
VAL_ 2365473057 LC_PassengerSideDomeLight 3 "NA" 2 "Error" 1 "Pressed" 0 "Not Pressed" ;
VAL_ 2566759713 DC2_LockStatOfDoor1 3 "NA" 2 "Error" 1 "Locked" 0 "Unlocked" ;
VAL_ 2566759713 DC2_OpenStatOfDoor1 3 "not available" 2 "error" 1 "door opened" 0 "door closed" ;
VAL_ 2566759713 DC2_LockStatOfDoor2 3 "NA" 2 "Error" 1 "Locked" 0 "Unlocked" ;
VAL_ 2566759713 DC2_OpenStatOfDoor2 3 "not available" 2 "error" 1 "door opened" 0 "door closed" ;
VAL_ 2365578991 MCU1_MotorWorkMode 3 "转子零位标定（保留）" 2 "转速控制模式" 1 "扭矩控制模式" 0 "自由随动模式" ;
VAL_ 2365578991 MCU1_MotorRotateDirection 3 "不可用" 2 "反向" 1 "正向" 0 "无旋转方向输出" ;
VAL_ 2365578991 MCU1_MotorSysStat 15 "不可用" 14 "保留" 7 "保留" 6 "下电状态" 5 "故障状态" 4 "限制状态" 3 "正常状态" 2 "随动状态" 1 "上电状态" 0 "未激活" ;
VAL_ 2365578991 MCU1_ActualMotorTrqHR 15 "不可用" 14 "保留" 8 "保留" 7 "+0.875%" 6 "+0.750%" 5 "+0.625%" 4 "+0.500%" 3 "+0.375%" 2 "+0.250%" 1 "+0.125%" 0 "+0.000%" ;
VAL_ 2365578991 MCU1_MaxOutputMotorTrqHR 15 "不可用" 14 "保留" 8 "保留" 7 "+0.875%" 6 "+0.750%" 5 "+0.625%" 4 "+0.500%" 3 "+0.375%" 2 "+0.250%" 1 "+0.125%" 0 "+0.000%" ;
VAL_ 2365578991 MCU1_HighVoltOffPermit 3 "不可用" 2 "保留" 1 "允许高压下电" 0 "不允许高压下电" ;
VAL_ 2365578991 MCU1_MotorDischargeStat 3 "主动放电退出" 2 "主动放电完成" 1 "主动放电进行" 0 "主动放电未启动" ;
VAL_ 2365578991 MCU1_MotorFaliureStat 3 "三级故障" 2 "二级故障" 1 "一级故障" 0 "无故障" ;
VAL_ 2566834707 DM1_EPS_ProtectLamp 3 "保留" 2 "保留" 1 "点亮" 0 "关闭" ;
VAL_ 2566834707 DM1_EPS_AmberWarningLamp 3 "保留" 2 "保留" 1 "点亮" 0 "关闭" ;
VAL_ 2566834707 DM1_EPS_RedStopLamp 3 "保留" 2 "保留" 1 "点亮" 0 "关闭" ;
VAL_ 2566834707 DM1_EPS_MalfunctionIndicatorLamp 3 "保留" 2 "保留" 1 "点亮" 0 "关闭" ;
VAL_ 2566845491 TIRE1_Stat 3 "NotSupported" 2 "Error" 1 "TireLeakDetected" 0 "Ok" ;
VAL_ 2566845491 TIRE1_ExtendTirePressSupport 3 "Not Supported" 2 "Error" 1 "Using Extended Tire Pressure" 0 "Not Using Extended Tire Pressure" ;
VAL_ 2566845491 TIRE1_PressThresholdDetect 7 "Not Available" 6 "Error indicator" 5 "Reserved" 4 "Reserved" 3 "Under pressure" 2 "No warning pressure" 1 "Over pressure" 0 "Reserved" ;
VAL_ 2566897971 TIRE3_TireSensorMatchStat 3 "Not available" 2 "Reserved" 1 "Not Matched" 0 "Matched" ;
VAL_ 2566897971 TIRE3_TireSensorSelfLearningStat 7 "Not available" 6 "Reserved" 4 "Reserved" 3 "Learning Failure" 2 "Learning Success" 1 "Start Learning" 0 "Inactive" ;
VAL_ 2566897971 TIRE3_TireSensorElectricalFault 3 "Not available" 2 "Sensor Failure" 1 "Battary Low" 0 "Sensor OK" ;
VAL_ 2566897971 TIRE3_TireTemThresholdDetection 7 "Not available" 6 "Error indicator" 5 "Reserved" 4 "Reserved" 3 "Under temperature" 2 "No warning temperature" 1 "Over temperature" 0 "Reserved" ;
VAL_ 2566834739 DM1_TPMS_ProtectLamp 3 "保留" 2 "保留" 1 "点亮" 0 "关闭" ;
VAL_ 2566834739 DM1_TPMS_AmberWarningLamp 3 "保留" 2 "保留" 1 "点亮" 0 "关闭" ;
VAL_ 2566834739 DM1_TPMS_RedStopLamp 3 "保留" 2 "保留" 1 "点亮" 0 "关闭" ;
VAL_ 2566834739 DM1_TPMS_MalfunctionLamp 3 "保留" 2 "保留" 1 "点亮" 0 "关闭" ;
VAL_ 2364539648 EEC2_AccelPedal1LowIdleSwitch 3 " NA" 2 " Error" 1 " Accelerator pedal 1 in low idle condition" 0 " Accelerator pedal 1 not in low idle condition" ;
VAL_ 2364539648 EEC2_AccelPedalKickdownSwitch 3 "Not available" 2 "Error" 1 "Kickdown active" 0 "Kickdown passive" ;
VAL_ 2348810282 TSC1_ACCE_EngOvrrdCtrlMode 3 "Speed/torque limit Ctrl" 2 "Torque Ctrl" 1 "Speed Ctrl" 0 "Override disabled" ;
VAL_ 2348810282 TSC1_ACCE_ReqSpdCtrlConditions 3 "Stability Optimized for driveline engaged and/or in lockup condition 2" 2 "Stability Optimized for driveline engaged and/or in lockup condition 1" 1 "Stability Optimized for driveline disengaged and non-lockup conditions" 0 "Transient Optimized for driveline disengaged and non-lockup conditions" ;
VAL_ 2348810282 TSC1_ACCE_OvrrdCtrlModePriority 3 "Low priority" 2 "Medium priority" 1 "High priority" 0 "Highest priority" ;
VAL_ 2348810282 TSC1_ACCE_TransRate 7 "Use standard TSC1 transmission rates of 10 ms to Eng" 6 "20 ms transmission rate" 5 "50 ms transmission rate" 4 "100 ms transmission rate" 3 "250 ms transmission rate" 2 "500 ms transmission rate" 1 "750 ms transmission rate" 0 "1000 ms transmission rate" ;
VAL_ 2348810282 TSC1_ACCE_CtrlPurpose 31 " Temporary Power Train Ctrl (Original use of TSC1 Cmd)" 30 "Reserved" 5 "Reserved" 4 "P5 = Eng Protection" 3 "P4 = Road Speed Governor" 2 "P3 = PTO Governor" 1 "P2 = Cruise Ctrl" 0 "P1 = Accelerator Pedal/Operator Selection" ;
VAL_ 2348810282 TSC1_ACCE_EngReqTrqHR 15 "NA" 14 "Reserved" 8 "Reserved" 7 "+0.875%" 6 "+0.750%" 5 "+0.625%" 4 "+0.500%" 3 "+0.375%" 2 "+0.250%" 1 "+0.125%" 0 "+0.000%" ;
VAL_ 2349075360 XBR2_EBIMode 3 "Reserved" 2 "Endurance Brk Integration allowed" 1 "Only Endurance Brks allowed" 0 "No Endurance Brk Integration allowed" ;
VAL_ 2349075360 XBR2_Priority 3 "Low priority" 2 "Medium priority" 1 "High priority" 0 "Highest priority" ;
VAL_ 2349075360 XBR2_CtrlMode 3 "Reserved" 2 "Acc Ctrl with maximum mode" 1 "Acc Ctrl with addition mode" 0 "Override disabled" ;
VAL_ 2566864170 EPB2_ExtInhibitReqForPBRelease 2 "inhibit auto and manual release" 1 "inhibit auto release" 0 "no inhibit active" ;
VAL_ 2566864170 EPB2_ExtInhibitReqForPBApply 3 "not available" 2 "error" 1 "automatic apply inhibited" 0 "no inhibit active" ;
VAL_ 2566864170 EPB2_ExtApplyReqForEPB 3 "not available" 2 "error" 1 "parking brake application requested" 0 "parking brake application not requested" ;
VAL_ 2566864170 EPB2_ExtReleaseReqForEPB 3 "not available" 2 "error" 1 "parking brake release requested" 0 "parking brake release not requested" ;
VAL_ 2566864170 EPB2_AutoDrvState 3 "not available" 2 "error" 1 "autonomous driving" 0 "manual driving" ;
VAL_ 2566857510 ADU1_ADUStat 15 "NA" 14 "Error" 13 "Rserved" 2 "Rserved" 1 "Auto" 0 "Manual" ;
VAL_ 2566857510 ADU1_ADUBrakeSwitch 3 "NA" 2 "Erorr" 1 "Brake pedal depressed" 0 "Brake pedal released" ;
VAL_ 2566858534 ADU_Cmd_FrontWiperSwitchCmd 15 "NA" 14 "Reserved" 6 "Reserved" 5 "Delayed2" 4 "Delayed1" 3 "high" 2 "medium" 1 "low" 0 "off" ;
VAL_ 2566858534 ADU_Cmd_FrontWasherSwitchCmd 7 "NA" 6 "Reserved" 2 "Reserved" 1 "low" 0 "off" ;
VAL_ 2566858534 ADU_Cmd_ADUToBCM 15 "not available" 14 "Reserved" 2 "Reserved" 1 "响应" 0 "不响应" ;
VAL_ 2566858534 ADU_Cmd_DrvDoor1UnlockReq 3 "Not available" 2 "Locked" 1 "Unlocked" 0 "No Request" ;
VAL_ 2566858534 ADU_Cmd_PassengerDoor2UnlockReq 3 "Not available" 2 "Locked" 1 "Unlocked" 0 "No Request" ;
VAL_ 2566858534 ADU_Cmd_BackBrakeLightCmd 3 "not available" 2 "error" 1 "制动踏板踩下" 0 "制动踏板未踩下" ;
VAL_ 2566858534 ADU_Cmd_HornCmd 3 "not available" 2 "Reserved" 1 "开启前后喇叭" 0 "关闭前后喇叭" ;
VAL_ 2566779431 VCU_Status_VCUMode 15 "NA" 14 "Error" 13 " Reserved" 2 " Reserved" 1 "Auto" 0 "Manual" ;
VAL_ 2566779431 VCU_Status_ManualBrakeSwitch 3 "NA" 2 "Erorr" 1 "Brake pedal depressed" 0 "Brake pedal released" ;
VAL_ 2566769953 OWW_FrontOperatorWiperSwitch 15 "Not available" 14 "Reserved" 6 "Reserved" 5 "Delayed 2" 4 "Delayed 1" 3 "High" 2 "Medium" 1 "Low" 0 "Off" ;
VAL_ 2566769953 OWW_FrontOperatorWasherSwitch 7 "Not available" 6 "Reserved" 2 "Reserved" 1 "Low(On)" 0 "Off" ;
VAL_ 2566849057 SC_IGOffPostnLightAlert 3 "Don’t Care" 2 "Reserved" 1 "Alert" 0 "No alert" ;
VAL_ 2566849057 SC_LDWSwitchStat 3 "NA" 2 "Error" 1 "Pressed" 0 "Not pressed" ;
VAL_ 2566849057 SC_FCWSwitchStat 3 "NA" 2 "Error" 1 "Pressed" 0 "Not pressed" ;
VAL_ 2566849057 SC_ReverseGearSwitch 3 "Not available" 2 "Reserved" 1 "Activate" 0 "De-activate" ;
VAL_ 2566849057 SC_RearWorkLampSwitch 3 "Not available" 2 "Reserved" 1 "Activate" 0 "De-activate" ;
VAL_ 2566849057 SC_SleepAreaLightSwitch 3 "Not available" 2 "Error" 1 "Pressed" 0 "Not pressed" ;
VAL_ 2566849057 SC_IndoorLightSwitch 3 "Not available" 2 "Error" 1 "Pressed" 0 "Not pressed" ;
VAL_ 2566849057 SC_HornSwitch 3 "Not available" 2 "Error" 1 "Pressed" 0 "Not pressed" ;
VAL_ 2566849057 SC_HornSelectionSwitch 3 "Not Available" 2 "Reserved" 1 "air horn to be blared" 0 "electric horn to be blared" ;
VAL_ 2566849057 SC_CabDoorWarnOFFSwitch 3 "Not available" 2 "Reserved" 1 "Activate" 0 "De-activate" ;
VAL_ 2566849057 SC_AutoLightCtrlSwitch 3 "Not available" 2 "Reserved" 1 "Activate" 0 "De-activate" ;
VAL_ 2566848801 BCU_IgnitionPstn 7 "Invalid Value" 6 "Err" 5 "Reserve" 4 "Reserve" 3 "Start(reserve)" 2 "ON" 1 "ACC" 0 "Off" ;
VAL_ 2566848801 BCU_DriverSeatBeltAlert 3 "Not Available" 2 "Reserved" 1 "Alert" 0 "No Alert" ;
VAL_ 2566848801 BCU_PassengerSeatBeltAlert 3 "Not Available" 2 "Reserved" 1 "Alert" 0 "No Alert" ;
VAL_ 2566849575 HCU_BMS_HCUSysStat 3 "不可用" 2 "故障，自检输出严重故障。" 1 "报警，自检输出一般故障；" 0 "正常；" ;
VAL_ 2566849575 HCU_BMS_ReadyToDriveStat 3 "整车可以驱动。" 2 "电机工作就绪；" 1 "附件工作就绪；" 0 "未就绪；" ;
VAL_ 2566849575 HCU_BMS_PermitCharge 3 "Not available" 2 "Reserved" 1 "Permit" 0 "Not Permit" ;
VAL_ 2566849575 HCU_BMS_SleepCmd 3 "Not available" 2 "Reserved" 1 "Sleep Cmd" 0 "No Cmd" ;
VAL_ 2566849575 HCU_BMS_HighVoltSysFailStat 3 "Level 3 Failure" 2 "Level 2 Failure" 1 "Level 1 Failure" 0 "No Error" ;
VAL_ 2566862323 BMS1_PowerBattSysStat 7 "Reserved" 4 "Reserved" 3 "Third Alarm" 2 "Second Alarm" 1 "First Alarm" 0 "Normal" ;
VAL_ 2566862323 BMS1_PowerBattChargeReq 7 "Reserved" 4 "Reserved" 3 "Undercharge Req (Reserved)" 2 "Chrg stop Req (Reserved)" 1 "Charge Req" 0 "No charge Req" ;
VAL_ 2566862323 BMS1_PowerBattChargeStat 3 "Charge fault" 2 "Charging completed" 1 "Charging" 0 "No charging" ;
VAL_ 2566862323 BMS1_PowerBattHeatStat 3 "Heating complete" 2 "Heating failure" 1 "Heating" 0 "No heating" ;
VAL_ 2566863603 BMS5_BMSMainNgtvCoilDrvStat 3 "Not available" 2 "Reserved" 1 "Connect" 0 "Disconnect" ;
VAL_ 2566863603 BMS5_MainNgtvRelayDisconnectReq 3 "Not available" 2 "Reserved" 1 "Disconnect Req" 0 "No Req" ;
VAL_ 2566863603 BMS5_MainNgtvRelayStat 7 "Not available" 6 "Reserved" 4 "Reserved" 3 "normally open" 2 "Adhesion" 1 "Connect" 0 "Disconnect" ;
VAL_ 2566863603 BMS5_BattPackHeatCtrlCmdPstv 3 "Not available" 2 "Reserved" 1 "Connect" 0 "Disconnect" ;
VAL_ 2566863603 BMS5_BattPackHeatCtrlCmdNgtv 3 "Not available" 2 "Reserved" 1 "Connect" 0 "Disconnect" ;
VAL_ 2566863603 BMS5_ChargePlugConnectionStat 3 "Not available" 2 "Reserved" 1 "Connect" 0 "Disconnect" ;
VAL_ 2566863603 BMS5_ChargePlug2ConnectionStat 3 "Not available" 2 "Reserved" 1 "Connect" 0 "Disconnect" ;
VAL_ 2566863603 BMS5_ChargeRelayStatPstv 7 "Not available" 6 "Reserved" 4 "Reserved" 3 "normally open" 2 "Adhesion" 1 "Connect" 0 "Disconnect" ;
VAL_ 2566863603 BMS5_ChargeRelayStatNgtv 7 "Not available" 6 "Reserved" 4 "Reserved" 3 "normally open" 2 "Adhesion" 1 "Connect" 0 "Disconnect" ;
VAL_ 2566834721 DM1_BCM_AmberWarningLamp 3 "保留" 2 "保留" 1 "点亮" 0 "关闭" ;
VAL_ 2566834721 DM1_BCM_RedStopLamp 3 "保留" 2 "保留" 1 "点亮" 0 "关闭" ;
VAL_ 2348814378 TSC1_ACCDR_EngOvrrdCtrlMode 3 "Speed/torque limit Ctrl" 2 "Torque Ctrl" 1 "Speed Ctrl" 0 "Override disabled" ;
VAL_ 2348814378 TSC1_ACCDR_ReqSpdCtrlConditions 3 "Stability Optimized for driveline engaged and/or in lockup condition 2" 2 "Stability Optimized for driveline engaged and/or in lockup condition 1" 1 "Stability Optimized for driveline disengaged and non-lockup conditions" 0 "Transient Optimized for driveline disengaged and non-lockup conditions" ;
VAL_ 2348814378 TSC1_ACCDR_OvrrdCtrlModePriority 3 "Low priority" 2 "Medium priority" 1 "High priority" 0 "Highest priority" ;
VAL_ 2348814378 TSC1_ACCDR_TransRate 7 "Use standard TSC1 transmission rates of 10 ms to Eng" 6 "20 ms transmission rate" 5 "50 ms transmission rate" 4 "100 ms transmission rate" 3 "250 ms transmission rate" 2 "500 ms transmission rate" 1 "750 ms transmission rate" 0 "1000 ms transmission rate" ;
VAL_ 2348814378 TSC1_ACCDR_CtrlPurpose 31 " P32=Temporary Power Train Ctrl (Original use of TSC1 Cmd)" 30 "Reserved" 5 "Reserved" 4 "P5 = Eng Protection" 3 "P4 = Road Speed Governor" 2 "P3 = PTO Governor" 1 "P2 = Cruise Ctrl" 0 "P1 = Accelerator Pedal/Operator Selection" ;
VAL_ 2348814378 TSC1_ACCDR_EngReqTrqHR 15 "NA" 14 "Reserved" 8 "Reserved" 7 "+0.875%" 6 "+0.750%" 5 "+0.625%" 4 "+0.500%" 3 "+0.375%" 2 "+0.250%" 1 "+0.125%" 0 "+0.000%" ;
VAL_ 2566894099 EPS1_EPSStat 15 "不可用" 14 "保留" 8 "保留" 7 "警告模式（无电动助力，无法进入自动驾驶模式）" 6 "警告模式（有电动助力，无法进入自动驾驶模式）" 5 "人工介入模式" 4 "手动模式" 3 "力矩叠加模式" 2 "保留" 1 "自动驾驶模式" 0 "待机模式" ;
VAL_ 2566893862 ADV_EPS_OperateMode 15 "不可用" 14 "保留" 8 "保留" 7 "警告模式（无电动助力，无法进入自动驾驶模式）" 6 "警告模式（有电动助力，无法进入自动驾驶模式）" 5 "人工介入模式" 4 "手动模式" 3 "力矩叠加模式" 2 "保留" 1 "自动驾驶模式" 0 "待机模式" ;
VAL_ 2566893862 ADV_EPS_ADVStatus 1 "ADV状态正常" 0 "ADV状态异常" ;
VAL_ 2566893862 ADV_EPS_SteerAngleStat 1 "正常" 0 "异常" ;
VAL_ 2566799393 LD_RunLight 3 "Not Available" 2 "Fault Detected" 1 "Activated" 0 "De-activated" ;
VAL_ 2566799393 LD_LowBeamHeadLightData 3 "Not Available" 2 "Fault Detected" 1 "Activated" 0 "De-activated" ;
VAL_ 2566799393 LD_HighBeamHeadLightData 3 "Not Available" 2 "Fault Detected" 1 "Activated" 0 "De-activated" ;
VAL_ 2566799393 LD_RightTurnSignalLights 3 "Not Available" 2 "Fault Detected" 1 "Activated" 0 "De-activated" ;
VAL_ 2566799393 LD_LeftTurnSignalLights 3 "Not Available" 2 "Fault Detected" 1 "Activated" 0 "De-activated" ;
VAL_ 2566799393 LD_FrontFogLights 3 "Not Available" 2 "Fault Detected" 1 "Activated" 0 "De-activated" ;
VAL_ 2566799393 LD_RearFogLights 3 "Not Available" 2 "Fault Detected" 1 "Activated" 0 "De-activated" ;
VAL_ 2566799393 LD_BackUpLightAndAlarmHorn 3 "Not Available" 2 "Fault Detected" 1 "Activated" 0 "De-activated" ;
VAL_ 2566799393 LD_CenterStopLight 3 "Not Available" 2 "Fault Detected" 1 "Activated" 0 "De-activated" ;
VAL_ 2566799393 LD_ImplementMarkerLightData 3 "Not Available" 2 "Fault Detected" 1 "Activated" 0 "De-activated" ;
VAL_ 2566860065 BCM_Status_BCMRespStat 15 "NA" 14 "Reserved" 4 "Reserved" 3 "error" 2 "failure" 1 "respond to ADV request" 0 "stand by（响应组合开关）" ;
VAL_ 2566860065 BCM_Status_BackBrakeLightStat 3 "not available" 2 "error" 1 "on" 0 "off" ;
VAL_ 2566860065 BCM_Status_HornStat 3 "not available" 2 "Reserved" 1 "前后喇叭都开启" 0 "前后喇叭都关闭" ;
VAL_ 2566860065 BCM_Status_WiperStat 15 "Not available" 14 "Reserved" 7 "Reserved" 6 "Reserved" 5 "interval level 2" 4 "interval level 1" 3 "High" 2 "Medium" 1 "Low" 0 "Off" ;
VAL_ 2566834931 DM1_BMS_AmberWarningLamp 3 "保留" 2 "保留" 1 "点亮" 0 "关闭" ;
VAL_ 2566834931 DM1_BMS_RedStopLamp 3 "保留" 2 "保留" 1 "点亮" 0 "关闭" ;
VAL_ 2566834784 DM1_PTU_AmberWarningLamp 3 "保留" 2 "保留" 1 "点亮" 0 "关闭" ;
VAL_ 2566834784 DM1_PTU_RedStopLamp 3 "保留" 2 "保留" 1 "点亮" 0 "关闭" ;
VAL_ 2566834741 DM1_DCDC2_AmberWarningLamp 3 "保留" 2 "保留" 1 "点亮" 0 "关闭" ;
VAL_ 2566834741 DM1_DCDC2_RedStopLamp 3 "保留" 2 "保留" 1 "点亮" 0 "关闭" ;
VAL_ 2566834736 DM1_APCU_AmberWarningLamp 3 "保留" 2 "保留" 1 "点亮" 0 "关闭" ;
VAL_ 2566834736 DM1_APCU_RedStopLamp 3 "保留" 2 "保留" 1 "点亮" 0 "关闭" ;
VAL_ 2566849516 FBCM_DriverWindowSwitch 3 "No Window Switch is pressed" 2 "Reserved" 1 "Wndw move down Swch is pressed" 0 "Wndw move up Swch is pressed" ;
VAL_ 2566849516 FBCM_DriverCtrlPasgrWindowSwitch 3 "No Wndw Swch is pressed" 2 "Reserved" 1 "Wndw move down Swch is pressed" 0 "Wndw move up Swch is pressed" ;
VAL_ 2566849516 FBCM_PassengerWindowSwitch 3 "No Wndw Swch is pressed" 2 "Reserved" 1 "Wndw move down Swch is pressed" 0 "Wndw move up Swch is pressed" ;
VAL_ 2566849516 FBCM_CabDoorsLockSwitch 3 "No lock/unlock Swch is pressed" 2 "Reserved" 1 "Cab doors unlock Swch is pressed" 0 "Cab doors lock Swch is pressed" ;
VAL_ 2566849516 FBCM_BackMirrorHeatSwitch 3 "Not available" 2 "Error" 1 "Pressed" 0 "Not pressed" ;
VAL_ 2566849516 FBCM_BackMirrorSelectSwitch 3 "Not Available" 2 "Reserved" 1 "select right back mirror" 0 "select left back mirror" ;
VAL_ 2566849516 FBCM_BackMirrorAdjustSwch 15 "Take no action" 14 "Reserved" 4 "Reserved" 3 "Wndw move right" 2 "Wndw move left" 1 "Wndw move down" 0 "Wndw move up" ;
VAL_ 2566849516 FBCM_VehAntiTheftStat 3 "Warn" 2 "Fortification" 1 "Pre-Warn" 0 "Idle" ;
VAL_ 2566849516 FBCM_RmtLightInspectCmd 3 "Don’t Care" 2 "Reserved" 1 "Activate" 0 "De-activate" ;
VAL_ 2566849516 FBCM_RmtSearchVehCmd 3 "Don’t Care" 2 "Reserved" 1 "Activate" 0 "De-activate" ;
VAL_ 2566849516 FBCM_LockOrUnlockSuccessAlert 3 "Lock/Unlock Failure Alert" 2 "Unlock Success Alert" 1 "Lock Success Alert" 0 "No Alert" ;
VAL_ 2566849516 FBCM_RMKeyBattStat 3 "Invalid Value" 2 "Reserved" 1 "Change Rmot key Batt" 0 "Normal" ;
VAL_ 2566913318 ADUSt_ADCtrlStat 7 "NA" 6 "Error" 5 "Reserved" 4 "Reserved" 3 "Active" 2 "Passive" 1 "Standby" 0 "Init" ;
VAL_ 2566913318 ADUSt_EBStat 1 " Active" 0 " Inactive" ;
VAL_ 2566913318 ADUSt_EBSrc 3 "Manual EB Switch" 2 "Cloud EB Req" 1 "ADU EB Req" 0 "No EB Req" ;
VAL_ 2566913318 ADUSt_ADCtrlReq 3 "NA" 2 "Request-Urgent" 1 "Request-Normal" 0 "No Request" ;
VAL_ 2566906109 IGWSt_IGWStat 7 "NA" 6 "Error" 5 "Reserved" 4 "AEB" 3 "Routing" 2 "Passive" 1 "Standby" 0 "Init" ;
VAL_ 2566906109 IGWSt_RouteStat 7 "NA" 6 "Reserved" 5 "Reserved" 4 "IGW" 3 "RCU" 2 "RDU" 1 "ADU" 0 "Default" ;
SIG_GROUP_ 2566844672 CCVS1_sg 1 : CCVS1_PBSwitch CCVS1_CruiseCtrlPauseSwitch CCVS1_WheelBasedVehSpd CruiseCtrlActive CCVS1_CruiseCtrlEnbSwitch CCVS1_BrakeSwitch CCVS1_ClutchSwitch CCVS1_CruiseCtrlSetSwitch CCVS1_CruiseCtrlResumeSwitch CCVS1_CruiseCtrlSetSpd CCVS1_PTOManagmentState CCVS1_CruiseCtrlState;
SIG_GROUP_ 2565866755 ETC2_sg 1 : ETC2_TransSelectedGear ETC2_TransActualGearRatio ETC2_TransCurrentGear;
SIG_GROUP_ 2566834768 DM1_EPB_sg 1 : DM1_EPB_ProtectLamp DM1_EPB_AmberWarningLamp DM1_EPB_RedStopLamp DM1_EPB_MalfunctionIndicatorLamp DM1_EPB_SAELamp_Reserved DM1_EPB_SPN8_LeastSignificantBit DM1_EPB_SPN_secondByteOfSPN DM1_EPB_FMI DM1_EPB_SPN3MmostSignificantBit DM1_EPB_OccurrenceCount DM1_EPB_SPNConversionMethod;
SIG_GROUP_ 2566863952 EPB1_sg 1 : EPB1_PressOfSpringBrakeChamber EPB1_ReasonForInhibitOfRelease EPB1_ReasonForInhibitOfApply EPB1_AmberWarnLampStat EPB1_RedStopLampStat EPB1_StateOfInhibitOfEPBRelease EPB1_StateOfEPB EPB1_WorkModeOfEPB EPB1_TrailerTestActivationState EPB1_StateOfInhibitOfEPBApply EPB1_EPBHCUInParkState EPB1_EPBHCUInReleaseState EPB1_PstnOfEPBHCU;
SIG_GROUP_ 2566834699 DM1_ABS_sg 1 : DM1_ABS_ProtectLamp DM1_ABS_AmberWarningLamp DM1_ABS_RedStopLamp DM1_ABS_MalfunctionIndicatorLamp DM1_ABS_SPN8_LeastSignificantBit DM1_ABS_SPN_secondByteOfSPN DM1_ABS_FMI DM1_ABS_SPN3MmostSignificantBit DM1_ABS_OccurrenceCount DM1_ABS_SPNConversionMethod;
SIG_GROUP_ 2565865739 EBC1_sg 1 : EBC1_ASREngCtrlActive EBC1_ASRBrakeCtrlActive EBC1_ABSActive EBC1_EBSBrakeSwitch EBC1_BrakePedalPstn EBC1_ABSOffroadSwitch EBC1_ASROffroadSwitch EBC1_ASRHillHolderSwitch EBC1_ABSFullyOperational EBC1_EBSRedWarnSignal EBC1_ABSOrEBSAmberWarnSignal EBC1_ATCOrASRInfoSignal EBC1_SourceAddressOfCtrlDevice EBC1_TractorMountTrailerABSWarn;
SIG_GROUP_ 2566831883 EBC2_sg 1 : EBC2_FrontAxleSpeed EBC2_RelativeSpdFrontAxleLWhl EBC2_RelativeSpdFrontAxleRWhl EBC2_RelativeSpdRearAxle1LWhl EBC2_RelativeSpdRearAxle1RWhl EBC2_RelativeSpdRearAxle2LWhl EBC2_RelativeSpdRearAxle2RWhl;
SIG_GROUP_ 2566767627 EBC5_sg 1 : EBC5_BrakeTempWarning EBC5_HaltBrakeMode EBC5_HillHolderMode EBC5_FoundationBrakeUse EBC5_XBRSysState EBC5_XBRActiveCtrlMode EBC5_XBRAccelLim EBC5_EmergencyBrakeActive;
SIG_GROUP_ 2566811659 CVW_sg 1 : CVW_PoweredVehWeight CVW_GrossCombineVehWeight;
SIG_GROUP_ 2565867787 VDC2_sg 1 : VDC2_SteerWheelAng VDC2_SteerWheelTurnCounter VDC2_SteerWheelAngSensorType VDC2_YawRate VDC2_LateralAccel VDC2_LongitudinalAccel;
SIG_GROUP_ 2365473062 LC_ADU_sg 1 : LC_ADU_RunLightCmd LC_ADU_LowBeamHeadLightCmd LC_ADU_HighBeamHeadLightCmd LC_ADU_TractorFrontFogLightsCmd LC_ADU_RightTurnSignalLightsCmd LC_ADU_LeftTurnSignalLightsCmd LC_ADU_BackUpLightAndHornCmd LC_ADU_ImplementMarkerLightCmd LC_ADU_RearFogLightCmd;
SIG_GROUP_ 2365473057 LC_sg 1 : LC_RunLightCmd LC_LowBeamHeadLightCmd LC_HighBeamHeadLightCmd LC_TractorFrontFogLightsCmd LC_RightTurnSignalLightsCmd LC_LeftTurnSignalLightsCmd LC_BackUpLightAndAlarmHornCmd LC_CenterStopLightCmd LC_ImplementMarkerLightCmd LC_RearFogLightCmd LC_DriverSideDomeLight LC_PassengerSideDomeLight;
SIG_GROUP_ 2566759713 DC2_sg 1 : DC2_LockStatOfDoor1 DC2_OpenStatOfDoor1 DC2_LockStatOfDoor2 DC2_OpenStatOfDoor2;
SIG_GROUP_ 2365578991 MCU1_sg 1 : MCU1_MotorWorkMode MCU1_MotorRotateDirection MCU1_MotorSysStat MCU1_ActualMotorTrqHR MCU1_MaxOutputMotorTrqHR MCU1_MotorTrq MCU1_MaxOutputMotorTrq MCU1_MotorSpd MCU1_HighVoltOffPermit MCU1_MotorDischargeStat MCU1_MotorFaliureStat MCU1_MsgCounter MCU1_MsgChecksum;
SIG_GROUP_ 2566834707 DM1_EPS_sg 1 : DM1_EPS_ProtectLamp DM1_EPS_AmberWarningLamp DM1_EPS_RedStopLamp DM1_EPS_MalfunctionIndicatorLamp DM1_EPS_SAELamp_Reserved DM1_EPS_SPN8_LeastSignificantBit DM1_EPS_SPN_secondByteOfSPN DM1_EPS_FMI DM1_EPS_SPN3MmostSignificantBit DM1_EPS_OccurrenceCount DM1_EPS_SPNConversionMethod;
SIG_GROUP_ 2566845491 TIRE1_sg 1 : TIRE1_Location TIRE1_Press TIRE1_Temp TIRE1_Stat TIRE1_ExtendTirePressSupport TIRE1_AirLeakageRate TIRE1_PressThresholdDetect;
SIG_GROUP_ 2566668851 TIRE2_sg 1 : TIRE2_Location TIRE2_PressExtendRange TIRE2_ReqTirePress;
SIG_GROUP_ 2566897971 TIRE3_sg 1 : TIRE3_TireLocation TIRE3_TireSensorMatchStat TIRE3_TireSensorSelfLearningStat TIRE3_TireSensorElectricalFault TIRE3_TireTemThresholdDetection;
SIG_GROUP_ 2566834739 DM1_TPMS_sg 1 : DM1_TPMS_ProtectLamp DM1_TPMS_AmberWarningLamp DM1_TPMS_RedStopLamp DM1_TPMS_MalfunctionLamp DM1_TPMS_SAELamp_Reserved DM1_TPMS_SPN_LeastSignificantBit DM1_TPMS_SPN_secondByteOfSPN DM1_TPMS_FMI DM1_TPMS_SPN3MmostSignificantBit DM1_TPMS_OccurrenceCount DM1_TPMS_SPNConversionMethod;
SIG_GROUP_ 2364539648 EEC2_sg 1 : EEC2_AccelPedal1LowIdleSwitch EEC2_AccelPedalKickdownSwitch EEC2_AccelPedalPstn EEC2_PercentLoadAtCurrentSpd;
SIG_GROUP_ 2348810282 TSC1_ACCE_sg 1 : TSC1_ACCE_EngOvrrdCtrlMode TSC1_ACCE_ReqSpdCtrlConditions TSC1_ACCE_OvrrdCtrlModePriority TSC1_ACCE_EngReqTrqOrTrqLim TSC1_ACCE_TransRate TSC1_ACCE_CtrlPurpose TSC1_ACCE_EngReqTrqHR TSC1_ACCE_MessageCounter TSC1_ACCE_MessageChecksum;
SIG_GROUP_ 2349075360 XBR2_sg 1 : XBR2_ExtAccelDemand XBR2_EBIMode XBR2_Priority XBR2_CtrlMode XBR2_MessageCounter XBR2_MessageChecksum;
SIG_GROUP_ 2348875814 TC1_ADU_sg 1 : TC1_ADU_TransReqGear;
SIG_GROUP_ 2566864170 EPB2_sg 1 : EPB2_ExtPressDemandForEPB EPB2_ExtInhibitReqForPBRelease EPB2_ExtInhibitReqForPBApply EPB2_ExtApplyReqForEPB EPB2_ExtReleaseReqForEPB EPB2_AutoDrvState EPB2_MessageCounter EPB2_MessageChecksum;
SIG_GROUP_ 2566857510 ADU1_sg 1 : ADU1_ADUStat ADU1_ADUTargetSpd ADU1_ADUBrakeSwitch ADU1_ADUTargetAccel;
SIG_GROUP_ 2566858534 ADU_Cmd_sg 1 : ADU_Cmd_FrontWiperSwitchCmd ADU_Cmd_FrontWasherSwitchCmd ADU_Cmd_ADUToBCM ADU_Cmd_DrvDoor1UnlockReq ADU_Cmd_PassengerDoor2UnlockReq ADU_Cmd_BackBrakeLightCmd ADU_Cmd_HornCmd;
SIG_GROUP_ 2566779431 VCU_Status_sg 1 : VCU_Status_VCUMode VCU_Status_ManualBrakeSwitch VCU_Status_ManualAccelPedalPstn VCU_Status_VCUAutoToManualTips VCU_Status_ActualMaxDrivePctTrq;
SIG_GROUP_ 2566769953 OWW_sg 1 : OWW_FrontOperatorWiperSwitch OWW_FrontOperatorWasherSwitch;
SIG_GROUP_ 2566849057 SC_sg 1 : SC_IGOffPostnLightAlert SC_LDWSwitchStat SC_FCWSwitchStat SC_ReverseGearSwitch SC_RearWorkLampSwitch SC_SleepAreaLightSwitch SC_IndoorLightSwitch SC_HornSwitch SC_HornSelectionSwitch SC_CabDoorWarnOFFSwitch SC_AutoLightCtrlSwitch;
SIG_GROUP_ 2566848801 BCU_sg 1 : BCU_IgnitionPstn BCU_DriverSeatBeltAlert BCU_PassengerSeatBeltAlert;
SIG_GROUP_ 2566849575 HCU_BMS_sg 1 : HCU_BMS_HCUSysStat HCU_BMS_ReadyToDriveStat HCU_BMS_PermitCharge HCU_BMS_EnduranceMileage HCU_BMS_SleepCmd HCU_BMS_HighVoltSysFailStat;
SIG_GROUP_ 2566862323 BMS1_sg 1 : BMS1_PowerBattVolt BMS1_PowerBattCurrent BMS1_PowerBattSOC BMS1_PowerBattSysStat BMS1_PowerBattChargeReq BMS1_PowerBattChargeStat BMS1_PowerBattHeatStat BMS1_MsgCounter BMS1_MsgChecksum;
SIG_GROUP_ 2566863603 BMS5_sg 1 : BMS5_BMSMainNgtvCoilDrvStat BMS5_PowerBattSOH BMS5_MainNgtvRelayDisconnectReq BMS5_MainNgtvRelayStat BMS5_BattPackHeatCtrlCmdPstv BMS5_BattPackHeatCtrlCmdNgtv BMS5_ChargePlugConnectionStat BMS5_ChargePlug2ConnectionStat BMS5_ChargeRelayStatPstv BMS5_ChargeRelayStatNgtv;
SIG_GROUP_ 2566840343 VD_sg 1 : VD_TripDistance VD_TotalVehDistance;
SIG_GROUP_ 2566834721 DM1_BCM_sg 1 : DM1_BCM_AmberWarningLamp DM1_BCM_RedStopLamp DM1_BCM_SAELamp_Reserved DM1_BCM_SPN8_LeastSignificantBit DM1_BCM_SPN_secondByteOfSPN DM1_BCM_FMI DM1_BCM_SPN3MmostSignificantBit DM1_BCM_OccurrenceCount DM1_BCM_SPNConversionMethod;
SIG_GROUP_ 2348814378 TSC1_ACCDR_sg 1 : TSC1_ACCDR_EngOvrrdCtrlMode TSC1_ACCDR_ReqSpdCtrlConditions TSC1_ACCDR_OvrrdCtrlModePriority TSC1_ACCDR_EngReqTrqOrTrqLim TSC1_ACCDR_TransRate TSC1_ACCDR_CtrlPurpose TSC1_ACCDR_EngReqTrqHR TSC1_ACCDR_MessageCounter TSC1_ACCDR_MessageChecksum;
SIG_GROUP_ 2566841127 EC_EM1_sg 1 : EC_EM1_EngSpdAtPoint1 EC_EM1_EngReferenceTrq EC_EM1_SupportVariableRateTSC1;
SIG_GROUP_ 2566894099 EPS_1_sg 1 : EPS1_SteerWheelAng EPS1_MotorAssistTrq EPS1_SteerAngSpd EPS1_HandTrq EPS1_EPSStat EPS1_MessageCounter EPS1_MessageChecksum;
SIG_GROUP_ 2566893862 ADV_EPS_sg 1 : ADV_EPS_TargetSteerWheelCmd ADV_EPS_OperateMode ADV_EPS_ADVStatus ADV_EPS_SteerAngleStat ADV_EPS_SteerAdditionalTrq ADV_EPS_SteerAngSpd ADV_EPS_MessageCounter ADV_EPS_MessageChecksum;
SIG_GROUP_ 2566799393 LD_sg 1 : LD_RunLight LD_LowBeamHeadLightData LD_HighBeamHeadLightData LD_RightTurnSignalLights LD_LeftTurnSignalLights LD_FrontFogLights LD_RearFogLights LD_BackUpLightAndAlarmHorn LD_CenterStopLight LD_ImplementMarkerLightData;
SIG_GROUP_ 2566860065 BCM_Status_sg 1 : BCM_Status_BCMRespStat BCM_Status_BackBrakeLightStat BCM_Status_HornStat BCM_Status_WiperStat;
SIG_GROUP_ 2566834931 DM1_BMS_sg 1 : DM1_BMS_AmberWarningLamp DM1_BMS_RedStopLamp DM1_BMS_SAELamp_Reserved DM1_BMS_SPN8_LeastSignificantBit DM1_BMS_SPN_secondByteOfSPN DM1_BMS_FMI DM1_BMS_SPN3MmostSignificantBit DM1_BMS_OccurrenceCount DM1_BMS_SPNConversionMethod;
SIG_GROUP_ 2566834784 DM1_PTU_sg 1 : DM1_PTU_AmberWarningLamp DM1_PTU_RedStopLamp DM1_PTU_SAELamp_Reserved DM1_PTU_SPN8_LeastSignificantBit DM1_PTU_SPN_secondByteOfSPN DM1_PTU_FMI DM1_PTU_SPN3MmostSignificantBit DM1_PTU_OccurrenceCount DM1_PTU_SPNConversionMethod;
SIG_GROUP_ 2566834741 DM1_DCDC2_sg 1 : DM1_DCDC2_AmberWarningLamp DM1_DCDC2_RedStopLamp DM1_DCDC2_SAELamp_Reserved DM1_DCDC2_SPN_LeastSgnificantBit DM1_DCDC2_SPN_secondByteOfSPN DM1_DCDC2_FMI DM1_DCDC2_SPNMmostSignificantBit DM1_DCDC2_OccurrenceCount DM1_DCDC2_SPNConversionMethod;
SIG_GROUP_ 2566834736 DM1_APCU_sg 1 : DM1_APCU_AmberWarningLamp DM1_APCU_RedStopLamp DM1_APCU_SAELamp_Reserved DM1_APCU_SPN_LeastSignificantBit DM1_APCU_SPN_secondByteOfSPN DM1_APCU_FMI DM1_APCU_SPN3MmostSignificantBit DM1_APCU_OccurrenceCount DM1_APCU_SPNConversionMethod;
SIG_GROUP_ 2566849516 FBCM_sg 1 : FBCM_DriverWindowSwitch FBCM_DriverCtrlPasgrWindowSwitch FBCM_PassengerWindowSwitch FBCM_CabDoorsLockSwitch FBCM_BackMirrorHeatSwitch FBCM_BackMirrorSelectSwitch FBCM_BackMirrorAdjustSwch FBCM_VehAntiTheftStat FBCM_RmtLightInspectCmd FBCM_RmtSearchVehCmd FBCM_LockOrUnlockSuccessAlert FBCM_RMKeyBattStat;
SIG_GROUP_ 2632777552 TPCM_EPB_sg 1 : TPCM_EPB;
SIG_GROUP_ 2632712016 TPDT_EPB_sg 1 : TPDT_EPB;
SIG_GROUP_ 2632777483 TPCM_EBS_sg 1 : TPCM_EBS;
SIG_GROUP_ 2632711947 TPDT_EBS_sg 1 : TPDT_EBS;
SIG_GROUP_ 2632777491 TPCM_EPS_sg 1 : TPCM_EPS;
SIG_GROUP_ 2632711955 TPDT_EPS_sg 1 : TPDT_EPS;
SIG_GROUP_ 2632777505 TPCM_BCM_sg 1 : TPCM_BCM;
SIG_GROUP_ 2632711969 TPDT_BCM_sg 1 : TPDT_BCM;
SIG_GROUP_ 2632777523 TPCM_TPMS_sg 1 : TPCM_TPMS;
SIG_GROUP_ 2632711987 TPDT_TPMS_sg 1 : TPDT_TPMS;
SIG_GROUP_ 2632777715 TPCM_BMS_sg 1 : TPCM_BMS;
SIG_GROUP_ 2632712179 TPDT_BMS_sg 1 : TPDT_BMS;
SIG_GROUP_ 2632777511 TPCM_VCU_sg 1 : TPCM_VCU;
SIG_GROUP_ 2632711975 TPDT_VCU_sg 1 : TPDT_VCU;
SIG_GROUP_ 2632777568 TPCM_PTU_sg 1 : TPCM_PTU;
SIG_GROUP_ 2632712032 TPDT_PTU_sg 1 : TPDT_PTU;
SIG_GROUP_ 2632777525 TPCM_DCDC2_sg 1 : TPCM_DCDC2;
SIG_GROUP_ 2632711989 TPDT_DCDC2_sg 1 : TPDT_DCDC2;
SIG_GROUP_ 2632777520 TPCM_APCU_sg 1 : TPCM_APCU;
SIG_GROUP_ 2632711984 TPDT_APCU_sg 1 : TPDT_APCU;
SIG_GROUP_ 2298375691 HRW_sg 1 : HRW_FrontAxleLeftWheelSpd HRW_FrontAxleRightWheelSpd HRW_RearAxleLeftWheelSpd HRW_RearAxleRightWheelSpd;
SIG_GROUP_ 2566913318 ADUSt_sg 1 : ADUSt_ADCtrlStat ADUSt_EBStat ADUSt_EBSrc ADUSt_ADCtrlReq ADUSt_LiveCounter;
SIG_GROUP_ 2566906109 IGWSt_sg 1 : IGWSt_IGWStat IGWSt_RouteStat IGWSt_ErrorStat IGWSt_LiveCounter;
